VERSION ""

NS_ :

BS_:

BU_:IC_MMI AVM GW AC BCM DSM_D DSM_P FSCM CWC
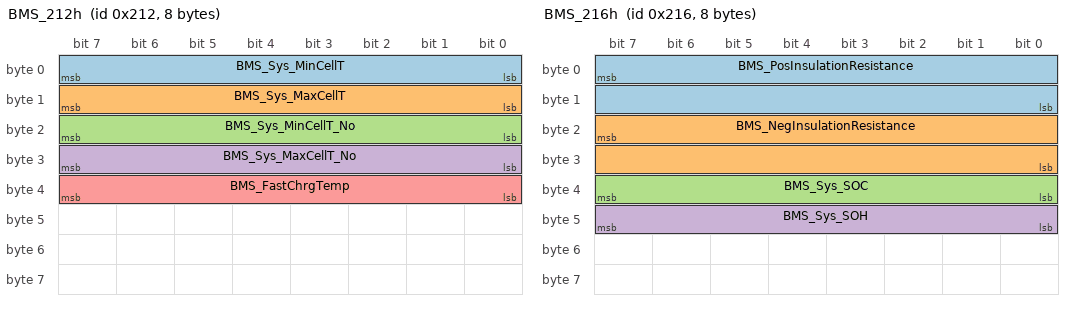
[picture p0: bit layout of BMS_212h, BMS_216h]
BO_ 530 BMS_212h: 8 GW
 SG_ BMS_Sys_MinCellT : 7|8@0+ (1,-50) [-50|204] "℃" IC_MMI
 SG_ BMS_Sys_MaxCellT : 15|8@0+ (1,-50) [-50|204] "℃" IC_MMI
 SG_ BMS_Sys_MinCellT_No : 23|8@0+ (1,0) [0|254] "℃" IC_MMI
 SG_ BMS_Sys_MaxCellT_No : 31|8@0+ (1,0) [0|254] "℃" IC_MMI
 SG_ BMS_FastChrgTemp : 39|8@0+ (1,-50) [-50|204] "℃" IC_MMI

BO_ 534 BMS_216h: 8 GW
 SG_ BMS_PosInsulationResistance : 7|16@0+ (1,0) [0|60000] "kΩ" IC_MMI
 SG_ BMS_NegInsulationResistance : 23|16@0+ (1,0) [0|60000] "kΩ" IC_MMI
 SG_ BMS_Sys_SOC : 39|8@0+ (1,0) [0|100] "%" IC_MMI
 SG_ BMS_Sys_SOH : 47|8@0+ (1,0) [0|100] "%" IC_MMI

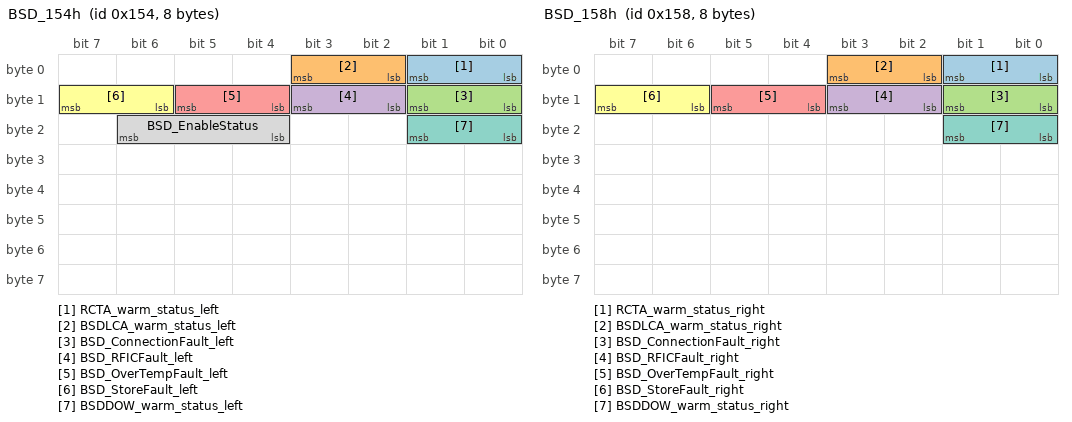
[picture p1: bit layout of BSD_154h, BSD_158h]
BO_ 340 BSD_154h: 8 GW
 SG_ RCTA_warm_status_left : 1|2@0+ (1,0) [0|3] "" IC_MMI
 SG_ BSDLCA_warm_status_left : 3|2@0+ (1,0) [0|3] "" IC_MMI
 SG_ BSD_ConnectionFault_left : 9|2@0+ (1,0) [0|3] "" IC_MMI
 SG_ BSD_RFICFault_left : 11|2@0+ (1,0) [0|3] "" IC_MMI
 SG_ BSD_OverTempFault_left : 13|2@0+ (1,0) [0|3] "" IC_MMI
 SG_ BSD_StoreFault_left : 15|2@0+ (1,0) [0|3] "" IC_MMI
 SG_ BSDDOW_warm_status_left : 17|2@0+ (1,0) [0|3] "" IC_MMI
 SG_ BSD_EnableStatus : 22|3@0+ (1,0) [0|7] "" IC_MMI

BO_ 344 BSD_158h: 8 GW
 SG_ RCTA_warm_status_right : 1|2@0+ (1,0) [0|3] "" IC_MMI
 SG_ BSDLCA_warm_status_right : 3|2@0+ (1,0) [0|3] "" IC_MMI
 SG_ BSD_ConnectionFault_right : 9|2@0+ (1,0) [0|3] "" IC_MMI
 SG_ BSD_RFICFault_right : 11|2@0+ (1,0) [0|3] "" IC_MMI
 SG_ BSD_OverTempFault_right : 13|2@0+ (1,0) [0|3] "" IC_MMI
 SG_ BSD_StoreFault_right : 15|2@0+ (1,0) [0|3] "" IC_MMI
 SG_ BSDDOW_warm_status_right : 17|2@0+ (1,0) [0|3] "" IC_MMI

BO_ 148 EHB_94h: 8 GW
 SG_ EHB_AEB_Available : 2|1@0+ (1,0) [0|1] "" IC_MMI
 SG_ EHB_ACC_Available : 3|1@0+ (1,0) [0|1] "" IC_MMI
 SG_ EHB_BrkPelPosActVD : 4|1@0+ (1,0) [0|1] "" IC_MMI
 SG_ EHB_FaultSt : 7|3@0+ (1,0) [0|7] "" IC_MMI
 SG_ EHB_BrkPelPosAct : 1|10@0+ (0.1,0) [0|100] "%" IC_MMI
 SG_ EHB_AEB_Jerk_Response : 19|1@0+ (1,0) [0|1] "" IC_MMI
 SG_ EHB_AEB_Request_Response : 20|1@0+ (1,0) [0|1] "" IC_MMI
 SG_ EHB_Prefill_Response : 21|1@0+ (1,0) [0|1] "" IC_MMI
 SG_ EHB_ACC_Request_Response : 22|1@0+ (1,0) [0|1] "" IC_MMI
 SG_ EHB_RegTorqReqVD : 23|1@0+ (1,0) [0|1] "" IC_MMI
 SG_ EHB_RegTorqReqWhl : 28|13@0+ (1,-6000) [-6000|0] "Nm" IC_MMI
 SG_ EHB_BrakePedalAppliedSt : 40|1@0+ (1,0) [0|1] "" IC_MMI
 SG_ EHB_94h_AliveCounter : 47|4@0+ (1,0) [0|15] "" IC_MMI
 SG_ EHB_BrakePedalApplied_Validity : 49|2@0+ (1,0) [0|3] "" IC_MMI
 SG_ EHBDiagActive : 52|1@0+ (1,0) [0|1] "" IC_MMI
 SG_ EHB_BrkLightAct : 53|1@0+ (1,0) [0|1] "" IC_MMI,BCM
 SG_ EHB_Hold : 54|1@0+ (1,0) [0|1] "" IC_MMI
 SG_ EHB_Hold_Available : 55|1@0+ (1,0) [0|1] "" IC_MMI
 SG_ EHB_94h_Checksum : 63|8@0+ (1,0) [0|255] "" IC_MMI

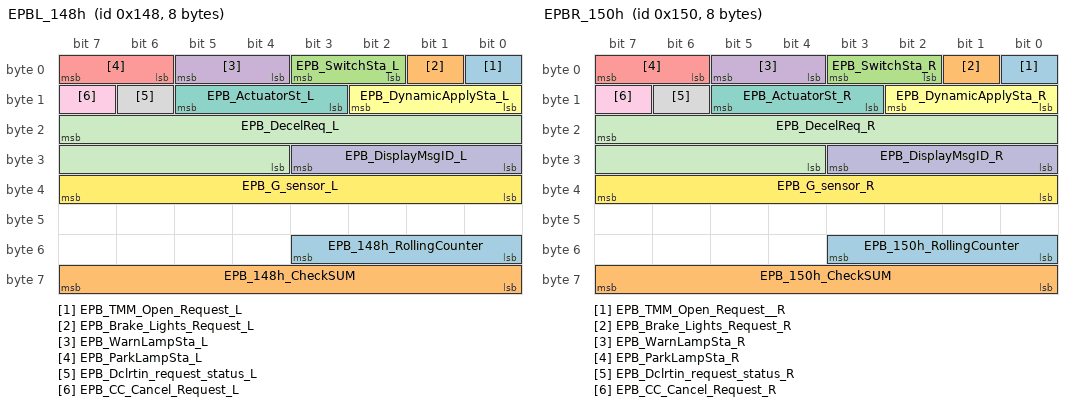
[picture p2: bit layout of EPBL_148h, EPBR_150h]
BO_ 328 EPBL_148h: 8 GW
 SG_ EPB_TMM_Open_Request_L : 0|1@0+ (1,0) [0|1] "" IC_MMI
 SG_ EPB_Brake_Lights_Request_L : 1|1@0+ (1,0) [0|1] "" IC_MMI,BCM
 SG_ EPB_SwitchSta_L : 3|2@0+ (1,0) [0|3] "" IC_MMI
 SG_ EPB_WarnLampSta_L : 5|2@0+ (1,0) [0|3] "" IC_MMI
 SG_ EPB_ParkLampSta_L : 7|2@0+ (1,0) [0|3] "" IC_MMI
 SG_ EPB_DynamicApplySta_L : 10|3@0+ (1,0) [0|7] "" IC_MMI
 SG_ EPB_ActuatorSt_L : 13|3@0+ (1,0) [0|7] "" IC_MMI,AVM
 SG_ EPB_Dclrtin_request_status_L : 14|1@0+ (1,0) [0|1] "" IC_MMI
 SG_ EPB_CC_Cancel_Request_L : 15|1@0+ (1,0) [0|1] "" IC_MMI
 SG_ EPB_DisplayMsgID_L : 27|4@0+ (1,0) [0|15] "" IC_MMI
 SG_ EPB_DecelReq_L : 23|12@0+ (0.01,-20.48) [-20.48|20.47] "" IC_MMI
 SG_ EPB_G_sensor_L : 39|8@0+ (1,0) [0|255] "" IC_MMI
 SG_ EPB_148h_RollingCounter : 51|4@0+ (1,0) [0|15] "" IC_MMI,AVM,BCM
 SG_ EPB_148h_CheckSUM : 63|8@0+ (1,0) [0|255] "" IC_MMI,AVM,BCM

BO_ 336 EPBR_150h: 8 GW
 SG_ EPB_TMM_Open_Request__R : 0|1@0+ (1,0) [0|1] "" IC_MMI
 SG_ EPB_Brake_Lights_Request_R : 1|1@0+ (1,0) [0|1] "" IC_MMI,BCM
 SG_ EPB_SwitchSta_R : 3|2@0+ (1,0) [0|3] "" IC_MMI
 SG_ EPB_WarnLampSta_R : 5|2@0+ (1,0) [0|3] "" IC_MMI
 SG_ EPB_ParkLampSta_R : 7|2@0+ (1,0) [0|3] "" IC_MMI
 SG_ EPB_DynamicApplySta_R : 10|3@0+ (1,0) [0|7] "" IC_MMI
 SG_ EPB_ActuatorSt_R : 13|3@0+ (1,0) [0|7] "" IC_MMI,AVM
 SG_ EPB_Dclrtin_request_status_R : 14|1@0+ (1,0) [0|1] "" IC_MMI
 SG_ EPB_CC_Cancel_Request_R : 15|1@0+ (1,0) [0|1] "" IC_MMI
 SG_ EPB_DisplayMsgID_R : 27|4@0+ (1,0) [0|15] "" IC_MMI
 SG_ EPB_DecelReq_R : 23|12@0+ (0.01,-20.48) [-20.48|20.47] "" IC_MMI
 SG_ EPB_G_sensor_R : 39|8@0+ (1,0) [0|255] "" IC_MMI
 SG_ EPB_150h_RollingCounter : 51|4@0+ (1,0) [0|15] "" IC_MMI,AVM,BCM
 SG_ EPB_150h_CheckSUM : 63|8@0+ (1,0) [0|255] "" IC_MMI,AVM,BCM

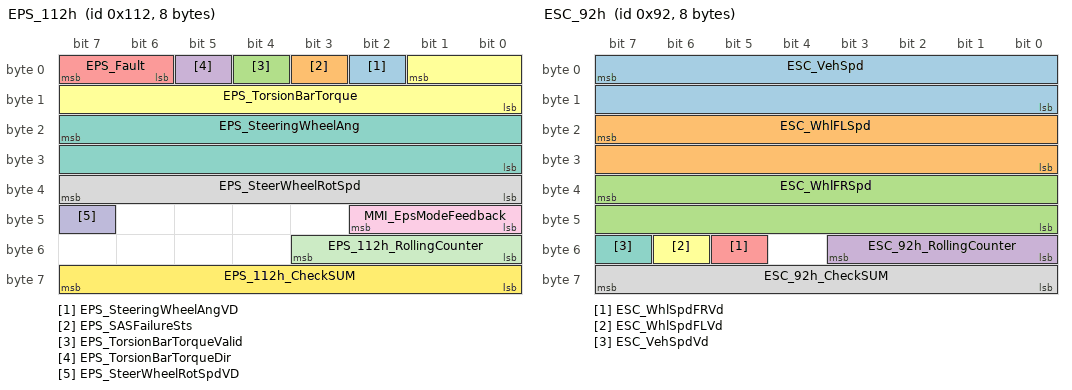
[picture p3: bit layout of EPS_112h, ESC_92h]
BO_ 274 EPS_112h: 8 GW
 SG_ EPS_SteeringWheelAngVD : 2|1@0+ (1,0) [0|1] "" IC_MMI,AVM
 SG_ EPS_SASFailureSts : 3|1@0+ (1,0) [0|1] "" IC_MMI,AVM
 SG_ EPS_TorsionBarTorqueValid : 4|1@0+ (1,0) [0|1] "" IC_MMI
 SG_ EPS_TorsionBarTorqueDir : 5|1@0+ (1,0) [0|1] "" IC_MMI
 SG_ EPS_Fault : 7|2@0+ (1,0) [0|3] "" IC_MMI
 SG_ EPS_TorsionBarTorque : 1|10@0+ (0.01,0) [0|8] "Nm" IC_MMI
 SG_ EPS_SteeringWheelAng : 23|16@0+ (0.1,-780) [-780|780] "degree" IC_MMI,AVM
 SG_ EPS_SteerWheelRotSpd : 39|8@0+ (4,0) [0|1016] "deg/s" IC_MMI
 SG_ MMI_EpsModeFeedback : 42|3@0+ (1,0) [0|7] "" IC_MMI
 SG_ EPS_SteerWheelRotSpdVD : 47|1@0+ (1,0) [0|1] "" IC_MMI
 SG_ EPS_112h_RollingCounter : 51|4@0+ (1,0) [0|15] "" IC_MMI
 SG_ EPS_112h_CheckSUM : 63|8@0+ (1,0) [0|255] "" IC_MMI

BO_ 144 ESC_90h: 8 GW
 SG_ ESC_TCSActive : 0|1@0+ (1,0) [0|1] "" IC_MMI
 SG_ ESC_HHC_Failure : 1|1@0+ (1,0) [0|1] "" IC_MMI
 SG_ ESC_HHCActive : 2|1@0+ (1,0) [0|1] "" IC_MMI
 SG_ ESC_EBDFailed : 3|1@0+ (1,0) [0|1] "" IC_MMI
 SG_ ESC_EBDActive : 4|1@0+ (1,0) [0|1] "" IC_MMI
 SG_ ESC_RBSState : 5|1@0+ (1,0) [0|1] "" IC_MMI
 SG_ ESC_ABSFailed : 6|1@0+ (1,0) [0|1] "" IC_MMI
 SG_ ESC_ABSActive : 7|1@0+ (1,0) [0|1] "" IC_MMI
 SG_ ESC_AVHactive : 8|1@0+ (1,0) [0|1] "" IC_MMI
 SG_ ESC_AutoholdStandby : 9|1@0+ (1,0) [0|1] "" IC_MMI
 SG_ ESC_AutoholdFailure : 10|1@0+ (1,0) [0|1] "" IC_MMI
 SG_ ESC_Sw : 11|1@0+ (1,0) [0|1] "" IC_MMI
 SG_ ESC_HBAActive : 12|1@0+ (1,0) [0|1] "" IC_MMI
 SG_ ESC_VDCFailure : 13|1@0+ (1,0) [0|1] "" IC_MMI
 SG_ ESC_VDCActive : 14|1@0+ (1,0) [0|1] "" IC_MMI
 SG_ ESC_TCSFailure : 15|1@0+ (1,0) [0|1] "" IC_MMI
 SG_ ESC_CDPAvailable : 20|1@0+ (1,0) [0|1] "" IC_MMI
 SG_ ESC_CDPActive : 21|1@0+ (1,0) [0|1] "" IC_MMI
 SG_ ESC_EPBRequest : 23|2@0+ (1,0) [0|3] "" IC_MMI
 SG_ ESC_BrkPrs : 19|12@0+ (0.1,0) [0|190] "bar" IC_MMI
 SG_ ESC_AVH_Warning1 : 40|1@0+ (1,0) [0|1] "" IC_MMI
 SG_ ESC_AVH_Warning2 : 41|1@0+ (1,0) [0|1] "" IC_MMI
 SG_ ESC_AVH_Warning3 : 42|1@0+ (1,0) [0|1] "" IC_MMI
 SG_ ESC_AVH_Warning4 : 43|1@0+ (1,0) [0|1] "" IC_MMI
 SG_ ESC_Brake_Light_Control : 38|1@0+ (1,0) [0|1] "" IC_MMI,BCM
 SG_ ESC_BrkPrsVd : 39|1@0+ (1,0) [0|1] "" IC_MMI
 SG_ ESC_90h_RollingCounter : 51|4@0+ (1,0) [0|15] "" IC_MMI,BCM
 SG_ ESC_90h_CheckSUM : 63|8@0+ (1,0) [0|255] "" IC_MMI,BCM

BO_ 146 ESC_92h: 8 GW
 SG_ ESC_VehSpd : 7|16@0+ (0.05625,0) [0|299.98] "km/h" IC_MMI,AVM,AC,BCM,DSM_D,DSM_P
 SG_ ESC_WhlFLSpd : 23|16@0+ (0.05625,0) [0|299.98125] "km/h" IC_MMI,AVM,BCM
 SG_ ESC_WhlFRSpd : 39|16@0+ (0.05625,0) [0|299.98125] "km/h" IC_MMI,AVM,BCM
 SG_ ESC_92h_RollingCounter : 51|4@0+ (1,0) [0|15] "" IC_MMI,AVM,AC,BCM,DSM_D,DSM_P
 SG_ ESC_WhlSpdFRVd : 53|1@0+ (1,0) [0|1] "" IC_MMI,AVM,BCM
 SG_ ESC_WhlSpdFLVd : 54|1@0+ (1,0) [0|1] "" IC_MMI,AVM,BCM
 SG_ ESC_VehSpdVd : 55|1@0+ (1,0) [0|1] "" IC_MMI,AVM,AC,BCM,DSM_D,DSM_P
 SG_ ESC_92h_CheckSUM : 63|8@0+ (1,0) [0|255] "" IC_MMI,AVM,AC,BCM,DSM_D,DSM_P

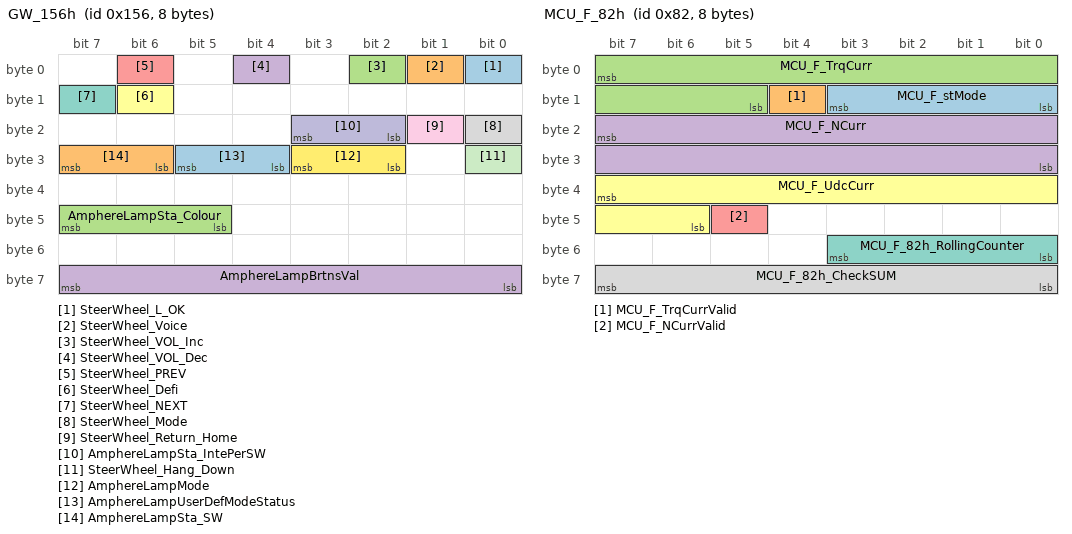
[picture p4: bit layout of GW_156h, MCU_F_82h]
BO_ 342 GW_156h: 8 GW
 SG_ SteerWheel_L_OK : 0|1@0+ (1,0) [0|1] "" IC_MMI
 SG_ SteerWheel_Voice : 1|1@0+ (1,0) [0|1] "" IC_MMI
 SG_ SteerWheel_VOL_Inc : 2|1@0+ (1,0) [0|1] "" IC_MMI
 SG_ SteerWheel_VOL_Dec : 4|1@0+ (1,0) [0|1] "" IC_MMI
 SG_ SteerWheel_PREV : 6|1@0+ (1,0) [0|1] "" IC_MMI
 SG_ SteerWheel_Defi : 14|1@0+ (1,0) [0|1] "" IC_MMI
 SG_ SteerWheel_NEXT : 15|1@0+ (1,0) [0|1] "" IC_MMI
 SG_ SteerWheel_Mode : 16|1@0+ (1,0) [0|1] "" IC_MMI
 SG_ SteerWheel_Return_Home : 17|1@0+ (1,0) [0|1] "" IC_MMI
 SG_ AmphereLampSta_IntePerSW : 19|2@0+ (1,0) [0|3] "" IC_MMI
 SG_ SteerWheel_Hang_Down : 24|1@0+ (1,0) [0|1] "" IC_MMI
 SG_ AmphereLampMode : 27|2@0+ (1,0) [0|3] "" IC_MMI
 SG_ AmphereLampUserDefModeStatus : 29|2@0+ (1,0) [0|3] "" IC_MMI
 SG_ AmphereLampSta_SW : 31|2@0+ (1,0) [0|3] "" IC_MMI
 SG_ AmphereLampSta_Colour : 47|3@0+ (1,0) [0|7] "" IC_MMI
 SG_ AmphereLampBrtnsVal : 63|8@0+ (1,0) [0|100] "%" IC_MMI

BO_ 594 MCU_F_252h: 8 GW
 SG_ MCU_F_FailureNum : 7|8@0+ (1,0) [0|255] "" IC_MMI
 SG_ MCU_F_ResolverFault : 8|1@0+ (1,0) [0|1] "" IC_MMI
 SG_ MCU_F_Err_IGBT : 9|1@0+ (1,0) [0|1] "" IC_MMI
 SG_ MCU_F_CurrentOverload : 11|2@0+ (1,0) [0|3] "" IC_MMI
 SG_ MCU_F_Controllertemp_Status : 13|2@0+ (1,0) [0|3] "" IC_MMI
 SG_ MCU_F_stDischg : 15|2@0+ (1,0) [0|3] "" IC_MMI
 SG_ MCU_F_SpeedOtLoopFalult : 18|1@0+ (1,0) [0|1] "" IC_MMI
 SG_ MCU_F_MdTepErr : 19|1@0+ (1,0) [0|1] "" IC_MMI
 SG_ MCU_F_ControllerOverVolt_Status : 21|2@0+ (1,0) [0|3] "" IC_MMI
 SG_ MCU_F_MotorTemp_Fault : 23|2@0+ (1,0) [0|3] "" IC_MMI
 SG_ MCU_F_MotorOverSpd : 25|1@0+ (1,0) [0|1] "" IC_MMI
 SG_ MCU_F_VCUCommErr : 26|1@0+ (1,0) [0|1] "" IC_MMI
 SG_ MCU_F_ControllerLowUnderVolt_Status : 27|1@0+ (1,0) [0|1] "" IC_MMI
 SG_ MCU_F_ControllerUnderVolt_Status : 29|2@0+ (1,0) [0|3] "" IC_MMI
 SG_ MCU_F_ControllerFault : 17|3@0+ (1,0) [0|7] "" IC_MMI
 SG_ FMCU_HV_Interlock_Falult : 35|2@0+ (1,0) [0|3] "" IC_MMI
 SG_ FMCU_Uncap_Falult : 37|2@0+ (1,0) [0|3] "" IC_MMI
 SG_ MCU_F_MotTepErr : 39|1@0+ (1,0) [0|1] "" IC_MMI

BO_ 130 MCU_F_82h: 8 GW
 SG_ MCU_F_stMode : 11|4@0+ (1,0) [0|15] "" IC_MMI
 SG_ MCU_F_TrqCurrValid : 12|1@0+ (1,0) [0|1] "" IC_MMI
 SG_ MCU_F_TrqCurr : 7|11@0+ (1,-1024) [-1024|1023] "Nm" IC_MMI
 SG_ MCU_F_NCurr : 23|16@0+ (1,-32768) [-32768|32767] "1/min" IC_MMI,AVM,BCM
 SG_ MCU_F_NCurrValid : 45|1@0+ (1,0) [0|1] "" IC_MMI,AVM,BCM
 SG_ MCU_F_UdcCurr : 39|10@0+ (1,0) [0|1021] "V" IC_MMI
 SG_ MCU_F_82h_RollingCounter : 51|4@0+ (1,0) [0|15] "" IC_MMI,AVM,BCM
 SG_ MCU_F_82h_CheckSUM : 63|8@0+ (1,0) [0|255] "" IC_MMI,AVM,BCM

BO_ 132 MCU_F_84h: 8 GW
 SG_ MCU_F_ControlerTemp : 7|8@0+ (1,-50) [-50|205] "℃" IC_MMI
 SG_ MCU_F_TempCurr : 31|8@0+ (1,-50) [-50|205] "℃" IC_MMI

BO_ 580 MCU_R_244h: 8 GW
 SG_ MCU_R_ControlerTemp : 7|8@0+ (1,-50) [-50|205] "℃" IC_MMI
 SG_ MCU_R_TempCurr : 31|8@0+ (1,-50) [-50|205] "℃" IC_MMI

BO_ 608 MCU_R_260h: 8 GW
 SG_ MCU_R_FailureNum : 7|8@0+ (1,0) [0|255] "" IC_MMI
 SG_ MCU_R_ResolverFault : 8|1@0+ (1,0) [0|1] "" IC_MMI
 SG_ MCU_R_Err_IGBT : 9|1@0+ (1,0) [0|1] "" IC_MMI
 SG_ MCU_R_CurrentOverload : 11|2@0+ (1,0) [0|3] "" IC_MMI
 SG_ MCU_R_Controllertemp_Status : 13|2@0+ (1,0) [0|3] "" IC_MMI
 SG_ MCU_R_stDischg : 15|2@0+ (1,0) [0|3] "" IC_MMI
 SG_ MCU_R_SpeedOtLoopFalult : 18|1@0+ (1,0) [0|1] "" IC_MMI
 SG_ MCU_R_MdTepErr : 19|1@0+ (1,0) [0|1] "" IC_MMI
 SG_ MCU_R_ControllerOverVolt_Status : 21|2@0+ (1,0) [0|3] "" IC_MMI
 SG_ MCU_R_MotorTemp_Fault : 23|2@0+ (1,0) [0|3] "" IC_MMI
 SG_ MCU_R_MotorOverSpd : 25|1@0+ (1,0) [0|1] "" IC_MMI
 SG_ MCU_R_VCUCommErr : 26|1@0+ (1,0) [0|1] "" IC_MMI
 SG_ MCU_R_ControllerLowUnderVolt_Status : 27|1@0+ (1,0) [0|1] "" IC_MMI
 SG_ MCU_R_ControllerUnderVolt_Status : 29|2@0+ (1,0) [0|3] "" IC_MMI
 SG_ MCU_R_ControllerFault : 17|3@0+ (1,0) [0|7] "" IC_MMI
 SG_ RMCU_HV_Interlock_Falult : 35|2@0+ (1,0) [0|3] "" IC_MMI
 SG_ RMCU_Uncap_Falult : 37|2@0+ (1,0) [0|3] "" IC_MMI
 SG_ MCU_R_MotTepErr : 39|1@0+ (1,0) [0|1] "" IC_MMI

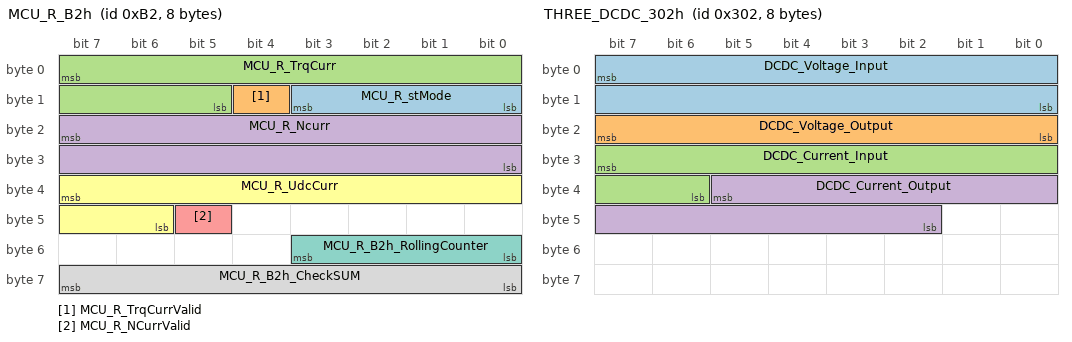
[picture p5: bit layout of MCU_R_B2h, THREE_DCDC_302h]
BO_ 178 MCU_R_B2h: 8 GW
 SG_ MCU_R_stMode : 11|4@0+ (1,0) [0|15] "" IC_MMI
 SG_ MCU_R_TrqCurrValid : 12|1@0+ (1,0) [0|1] "" IC_MMI
 SG_ MCU_R_TrqCurr : 7|11@0+ (1,-1024) [-1024|1023] "Nm" IC_MMI
 SG_ MCU_R_Ncurr : 23|16@0+ (1,-32768) [-32768|32767] "1/min" IC_MMI,AVM,BCM
 SG_ MCU_R_NCurrValid : 45|1@0+ (1,0) [0|1] "" IC_MMI,AVM,BCM
 SG_ MCU_R_UdcCurr : 39|10@0+ (1,0) [0|1021] "V" IC_MMI
 SG_ MCU_R_B2h_RollingCounter : 51|4@0+ (1,0) [0|15] "" IC_MMI,AVM,BCM
 SG_ MCU_R_B2h_CheckSUM : 63|8@0+ (1,0) [0|15] "" IC_MMI,AVM,BCM

BO_ 772 THREE_OBC_304h: 8 GW
 SG_ OBC_out_Cur_over_prot : 0|1@0+ (1,0) [0|1] "" IC_MMI
 SG_ OBC_out_vol_Less_prot : 1|1@0+ (1,0) [0|1] "" IC_MMI
 SG_ OBC_out_vol_over_prot : 2|1@0+ (1,0) [0|1] "" IC_MMI
 SG_ OBC_In_Cur_over_prot : 3|1@0+ (1,0) [0|1] "" IC_MMI
 SG_ OBC_ChargerInputVoltageLessFault : 4|1@0+ (1,0) [0|1] "" IC_MMI
 SG_ OBC_ChargerInputVoltageOverFault : 5|1@0+ (1,0) [0|1] "" IC_MMI
 SG_ ChargeInterfaceOverTemp : 6|1@0+ (1,0) [0|1] "" IC_MMI
 SG_ ChargeInterfacetemperature : 15|8@0+ (1,0) [0|255] "℃" IC_MMI
 SG_ OBC_ControllerTemp : 23|8@0+ (1,0) [0|255] "℃" IC_MMI
 SG_ OBC_ChargerOTP : 25|2@0+ (1,0) [0|3] "" IC_MMI
 SG_ OBC_ChargerCoolingRequest : 26|1@0+ (1,0) [0|1] "" IC_MMI
 SG_ OBC_ChargerHardwareFault : 27|1@0+ (1,0) [0|1] "" IC_MMI
 SG_ OBC_Charger_CAN_Fault : 28|1@0+ (1,0) [0|1] "" IC_MMI
 SG_ OBC_Charger_Fail_State : 29|1@0+ (1,0) [0|1] "" IC_MMI
 SG_ OBC_Charger_NoBatt : 31|2@0+ (1,0) [0|3] "" IC_MMI
 SG_ OBC_CP_DutyCycleValue : 39|8@0+ (1,0) [0|100] "%" IC_MMI
 SG_ OBC_CP_Rsv : 40|1@0+ (1,0) [0|1] "" IC_MMI
 SG_ OBC_CC_Resistance : 43|3@0+ (1,0) [0|7] "" IC_MMI
 SG_ OBC_ChargerStatus : 46|3@0+ (1,0) [0|7] "" IC_MMI
 SG_ KL30_UnderVolt : 49|2@0+ (1,0) [0|3] "" IC_MMI
 SG_ ElectronicLockSts : 50|1@0+ (1,0) [0|1] "" IC_MMI
 SG_ ElectronicLockFault : 52|2@0+ (1,0) [0|3] "" IC_MMI
 SG_ OBC_Charger_Instructions : 53|1@0+ (1,0) [0|1] "" IC_MMI
 SG_ OBC_Charger_Request : 54|1@0+ (1,0) [0|1] "" IC_MMI

BO_ 770 THREE_DCDC_302h: 8 GW
 SG_ DCDC_Voltage_Input : 7|16@0+ (0.1,0) [0|500] "V" IC_MMI
 SG_ DCDC_Voltage_Output : 23|8@0+ (0.1,0) [0|20] "A" IC_MMI
 SG_ DCDC_Current_Input : 31|10@0+ (0.1,0) [0|60] "V" IC_MMI
 SG_ DCDC_Current_Output : 37|12@0+ (0.1,0) [0|400] "A" IC_MMI

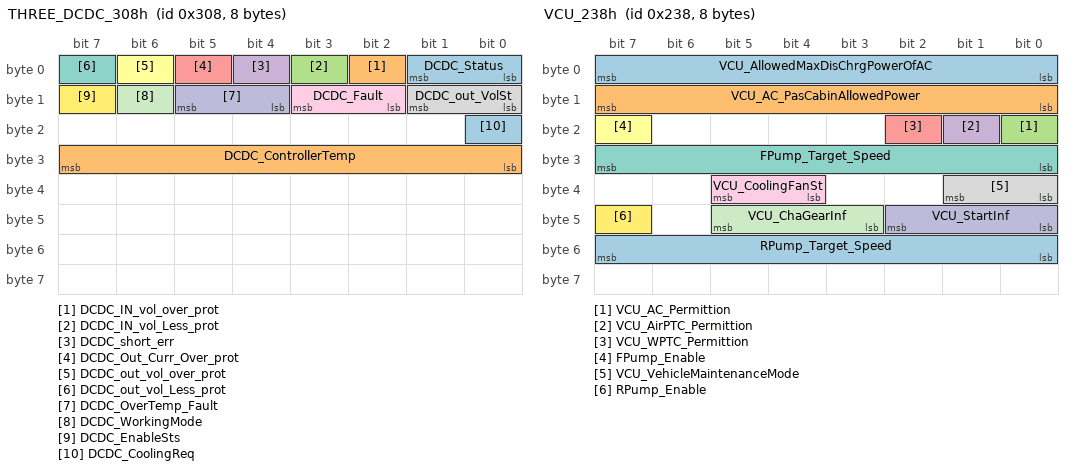
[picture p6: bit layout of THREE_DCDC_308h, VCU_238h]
BO_ 776 THREE_DCDC_308h: 8 GW
 SG_ DCDC_Status : 1|2@0+ (1,0) [0|3] "" IC_MMI
 SG_ DCDC_IN_vol_over_prot : 2|1@0+ (1,0) [0|1] "" IC_MMI
 SG_ DCDC_IN_vol_Less_prot : 3|1@0+ (1,0) [0|1] "" IC_MMI
 SG_ DCDC_short_err : 4|1@0+ (1,0) [0|1] "" IC_MMI
 SG_ DCDC_Out_Curr_Over_prot : 5|1@0+ (1,0) [0|1] "" IC_MMI
 SG_ DCDC_out_vol_over_prot : 6|1@0+ (1,0) [0|1] "" IC_MMI
 SG_ DCDC_out_vol_Less_prot : 7|1@0+ (1,0) [0|1] "" IC_MMI
 SG_ DCDC_out_VolSt : 9|2@0+ (1,0) [0|3] "" IC_MMI
 SG_ DCDC_Fault : 11|2@0+ (1,0) [0|3] "" IC_MMI
 SG_ DCDC_OverTemp_Fault : 13|2@0+ (1,0) [0|3] "" IC_MMI
 SG_ DCDC_WorkingMode : 14|1@0+ (1,0) [0|1] "" IC_MMI
 SG_ DCDC_EnableSts : 15|1@0+ (1,0) [0|1] "" IC_MMI
 SG_ DCDC_CoolingReq : 16|1@0+ (1,0) [0|1] "" IC_MMI
 SG_ DCDC_ControllerTemp : 31|8@0+ (1,0) [0|255] "℃" IC_MMI

BO_ 372 VCU_174h: 8 GW
 SG_ VCU_Err_BrakeSwitch : 0|1@0+ (1,0) [0|1] "" IC_MMI
 SG_ VCU_Err_BrakePedal : 1|1@0+ (1,0) [0|1] "" IC_MMI
 SG_ VCU_Err_AccPedal : 2|1@0+ (1,0) [0|1] "" IC_MMI
 SG_ VCU_GearPosition : 7|4@0+ (1,0) [0|15] "" IC_MMI,AVM,BCM,FSCM
 SG_ VCU_PrechrgAnodeRelay_Status : 9|2@0+ (1,0) [0|3] "" IC_MMI
 SG_ VCU_DischrgAnodeRelay_Control : 11|1@0+ (1,0) [0|1] "" IC_MMI
 SG_ VCU_DischrgAnodeRelay_Status : 14|2@0+ (1,0) [0|3] "" IC_MMI
 SG_ VCU_DischrgCathodeRelay_Control : 17|1@0+ (1,0) [0|1] "" IC_MMI
 SG_ VCU_DischrgCathodeRelay_status : 19|2@0+ (1,0) [0|3] "" IC_MMI
 SG_ VCU_PrechrgAnodeRelay_Control : 21|1@0+ (1,0) [0|1] "" IC_MMI
 SG_ VCU_PTSystem_Satus : 23|2@0+ (1,0) [0|3] "" IC_MMI,AVM
 SG_ VCU_VehSysStatus : 28|5@0+ (1,0) [0|31] "" IC_MMI,AVM,AC,BCM
 SG_ VCU_ChrgRelay_Control : 29|1@0+ (1,0) [0|1] "" IC_MMI
 SG_ VCU_Cruise_MainSwitch : 32|1@0+ (1,0) [0|1] "" IC_MMI
 SG_ VCU_OperationMode : 34|2@0+ (1,0) [0|3] "" IC_MMI,AC
 SG_ VCU_DrivingMode : 36|2@0+ (1,0) [0|1] "" IC_MMI
 SG_ VCU_SpeedMode : 37|1@0+ (1,0) [0|1] "" IC_MMI
 SG_ VCU_TortoiseIndicator : 44|1@0+ (1,0) [0|1] "" IC_MMI
 SG_ VCU_Comd_OpenHazardWarningLamp : 45|1@0+ (1,0) [0|1] "" IC_MMI,BCM
 SG_ VCU_ActiveDischargeOrder : 46|1@0+ (1,0) [0|1] "" IC_MMI
 SG_ VCU_Cruise_Enable : 47|1@0+ (1,0) [0|1] "" IC_MMI
 SG_ VCU_174h_RollingCounter : 51|4@0+ (1,0) [0|15] "" IC_MMI,AVM,AC,BCM,FSCM
 SG_ VCU_UnlockSts : 54|2@0+ (1,0) [0|3] "" IC_MMI,BCM
 SG_ VCU_StartAllow : 55|1@0+ (1,0) [0|1] "" IC_MMI,BCM
 SG_ VCU_174h_CheckSUM : 63|8@0+ (1,0) [0|255] "" IC_MMI,AVM,AC,BCM,FSCM

BO_ 568 VCU_238h: 8 GW
 SG_ VCU_AllowedMaxDisChrgPowerOfAC : 7|8@0+ (0.1,0) [0|20] "kw" IC_MMI,AC
 SG_ VCU_AC_PasCabinAllowedPower : 15|8@0+ (0.1,0) [0|20] "kw" IC_MMI,AC
 SG_ VCU_AC_Permittion : 16|1@0+ (1,0) [0|1] "" IC_MMI,AC
 SG_ VCU_AirPTC_Permittion : 17|1@0+ (1,0) [0|1] "" IC_MMI,AC
 SG_ VCU_WPTC_Permittion : 18|1@0+ (1,0) [0|1] "" IC_MMI,AC
 SG_ FPump_Enable : 23|1@0+ (1,0) [0|1] "" IC_MMI
 SG_ FPump_Target_Speed : 31|8@0+ (1,0) [0|100] "%" IC_MMI
 SG_ VCU_VehicleMaintenanceMode : 33|2@0+ (1,0) [0|3] "" IC_MMI,AC
 SG_ VCU_CoolingFanSt : 37|2@0+ (1,0) [0|3] "" IC_MMI,AC
 SG_ VCU_StartInf : 42|3@0+ (1,0) [0|7] "" IC_MMI
 SG_ VCU_ChaGearInf : 45|3@0+ (1,0) [0|7] "" IC_MMI
 SG_ RPump_Enable : 47|1@0+ (1,0) [0|1] "" IC_MMI
 SG_ RPump_Target_Speed : 55|8@0+ (1,0) [0|100] "%" IC_MMI

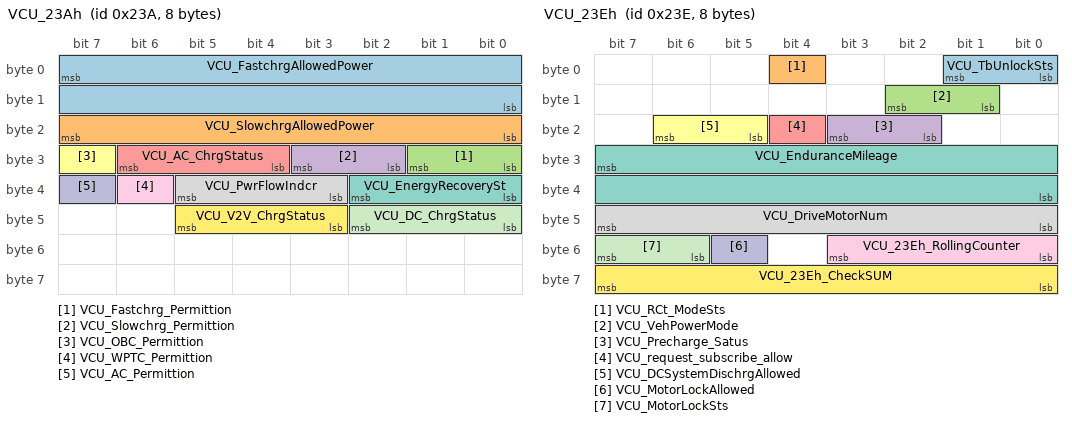
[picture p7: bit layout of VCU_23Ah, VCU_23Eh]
BO_ 570 VCU_23Ah: 8 GW
 SG_ VCU_FastchrgAllowedPower : 7|16@0+ (0.1,0) [0|100] "kw" IC_MMI
 SG_ VCU_SlowchrgAllowedPower : 23|8@0+ (0.1,0) [0|20] "kw" IC_MMI
 SG_ VCU_Fastchrg_Permittion : 25|2@0+ (1,0) [0|3] "" IC_MMI
 SG_ VCU_Slowchrg_Permittion : 27|2@0+ (1,0) [0|3] "" IC_MMI
 SG_ VCU_AC_ChrgStatus : 30|3@0+ (1,0) [0|7] "" IC_MMI
 SG_ VCU_OBC_Permittion : 31|1@0+ (1,0) [0|1] "" IC_MMI
 SG_ VCU_EnergyRecoverySt : 34|3@0+ (1,0) [0|7] "" IC_MMI
 SG_ VCU_PwrFlowIndcr : 37|3@0+ (1,0) [0|7] "" IC_MMI
 SG_ VCU_WPTC_Permittion : 38|1@0+ (1,0) [0|1] "" IC_MMI
 SG_ VCU_AC_Permittion : 39|1@0+ (1,0) [0|1] "" IC_MMI
 SG_ VCU_DC_ChrgStatus : 42|3@0+ (1,0) [0|7] "" IC_MMI
 SG_ VCU_V2V_ChrgStatus : 45|3@0+ (1,0) [0|7] "" IC_MMI

BO_ 574 VCU_23Eh: 8 GW
 SG_ VCU_TbUnlockSts : 1|2@0+ (1,0) [0|3] "" IC_MMI
 SG_ VCU_RCt_ModeSts : 4|1@0+ (1,0) [0|1] "" IC_MMI
 SG_ VCU_VehPowerMode : 10|2@0+ (1,0) [0|3] "" IC_MMI
 SG_ VCU_Precharge_Satus : 19|2@0+ (1,0) [0|3] "" IC_MMI
 SG_ VCU_request_subscribe_allow : 20|1@0+ (1,0) [0|1] "" IC_MMI
 SG_ VCU_DCSystemDischrgAllowed : 22|2@0+ (1,0) [0|3] "" IC_MMI
 SG_ VCU_EnduranceMileage : 31|16@0+ (0.1,0) [0|800] "km" IC_MMI
 SG_ VCU_DriveMotorNum : 47|8@0+ (1,0) [1|254] "" IC_MMI
 SG_ VCU_23Eh_RollingCounter : 51|4@0+ (1,0) [0|15] "" IC_MMI
 SG_ VCU_MotorLockAllowed : 53|1@0+ (1,0) [0|1] "" IC_MMI
 SG_ VCU_MotorLockSts : 55|2@0+ (1,0) [0|3] "" IC_MMI
 SG_ VCU_23Eh_CheckSUM : 63|8@0+ (1,0) [0|255] "" IC_MMI

BO_ 112 VCU_70h: 8 GW
 SG_ VCU_APA_FaildType : 2|3@0+ (1,0) [0|7] "" IC_MMI
 SG_ VCU_BrkPedPos_Validity : 3|1@0+ (1,0) [0|1] "" IC_MMI
 SG_ VCU_BrkSw_Sta : 4|1@0+ (1,0) [0|1] "" IC_MMI,AVM,BCM
 SG_ VCU_EHB_VLC_Response : 5|1@0+ (1,0) [0|1] "" IC_MMI
 SG_ VCU_BrkSw_V : 6|1@0+ (1,0) [0|1] "" IC_MMI,AVM,BCM
 SG_ VCU_Acc_Validity : 7|1@0+ (1,0) [0|1] "" IC_MMI,AVM
 SG_ VCU_BrkPed_Pos : 15|8@0+ (0.5,0) [0|100] "%" IC_MMI
 SG_ VCU_Acc_pedal_position : 23|8@0+ (0.5,0) [0|100] "%" IC_MMI,AVM
 SG_ VCU_APA_ActiveEnableSts : 30|1@0+ (1,0) [0|1] "bit" IC_MMI
 SG_ VCU_MotorTrqRegAllowed : 31|1@0+ (1,0) [0|1] "" IC_MMI
 SG_ VCU_MotorTrqRegLimit : 28|13@0+ (1,-6000) [-6000|0] "NM" IC_MMI
 SG_ VCU_Accel_Padel_Pos_Calc : 47|8@0+ (0.5,0) [0|100] "%" IC_MMI
 SG_ VCU_70h_RollingCounter : 51|4@0+ (1,0) [0|15] "" IC_MMI,AVM,BCM
 SG_ VCU_Request_Response : 52|1@0+ (1,0) [0|1] "" IC_MMI
 SG_ VCU_Kickdown_AEB : 53|1@0+ (1,0) [0|1] "" IC_MMI
 SG_ VCU_Accel_Padel_Override : 54|1@0+ (1,0) [0|1] "" IC_MMI
 SG_ VCU_Available : 55|1@0+ (1,0) [0|1] "" IC_MMI
 SG_ VCU_70h_CheckSUM : 63|8@0+ (1,0) [0|255] "" IC_MMI,AVM,BCM

BO_ 913 VSP_391h: 8 GW
 SG_ VSP_State : 2|2@0+ (1,0) [0|3] "" IC_MMI
 SG_ VSP_VoiceSourceSelectFeedback : 4|2@0+ (1,0) [0|3] "" IC_MMI

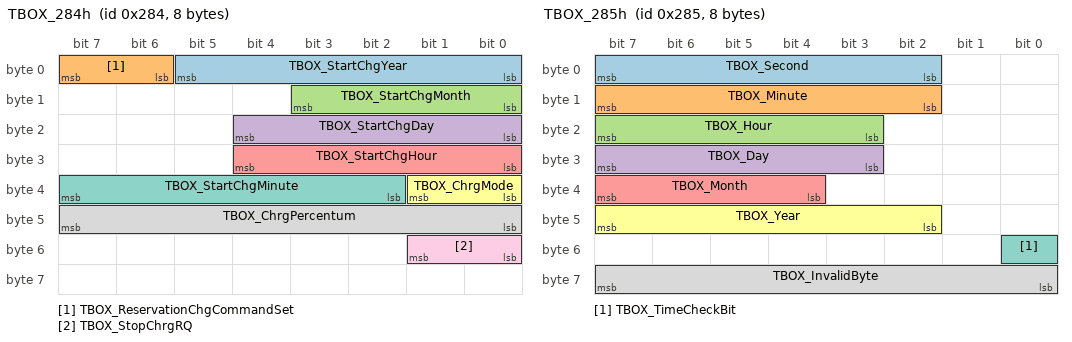
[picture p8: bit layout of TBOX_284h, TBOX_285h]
BO_ 644 TBOX_284h: 8 GW
 SG_ TBOX_StartChgYear : 5|6@0+ (1,2010) [2010|2072] "" IC_MMI
 SG_ TBOX_ReservationChgCommandSet : 7|2@0+ (1,0) [0|3] "" IC_MMI
 SG_ TBOX_StartChgMonth : 11|4@0+ (1,0) [1|12] "" IC_MMI
 SG_ TBOX_StartChgDay : 20|5@0+ (1,0) [1|31] "" IC_MMI
 SG_ TBOX_StartChgHour : 28|5@0+ (1,0) [0|23] "" IC_MMI
 SG_ TBOX_ChrgMode : 33|2@0+ (1,0) [0|3] "" IC_MMI
 SG_ TBOX_StartChgMinute : 39|6@0+ (1,0) [0|59] "" IC_MMI
 SG_ TBOX_ChrgPercentum : 47|8@0+ (1,0) [0|100] "%" IC_MMI
 SG_ TBOX_StopChrgRQ : 49|2@0+ (1,0) [0|3] "" IC_MMI

BO_ 645 TBOX_285h: 8 GW
 SG_ TBOX_Second : 7|6@0+ (1,0) [0|59] "s" IC_MMI,AVM,AC
 SG_ TBOX_Minute : 15|6@0+ (1,0) [0|59] "m" IC_MMI,AVM,AC
 SG_ TBOX_Hour : 23|5@0+ (1,0) [0|23] "h" IC_MMI,AVM,AC
 SG_ TBOX_Day : 31|5@0+ (1,0) [1|31] "d" IC_MMI,AVM,AC
 SG_ TBOX_Month : 39|4@0+ (1,0) [1|12] "m" IC_MMI,AVM,AC
 SG_ TBOX_Year : 47|6@0+ (1,2010) [2010|2072] "y" IC_MMI,AVM,AC
 SG_ TBOX_TimeCheckBit : 48|1@0+ (1,0) [0|1] "" IC_MMI,AVM,AC
 SG_ TBOX_InvalidByte : 63|8@0+ (1,0) [0|255] "" IC_MMI,AVM,AC

BO_ 662 TBOX_296h: 8 GW
 SG_ TBOX_VehiclePosition_longitude : 7|32@0+ (0.0000001,-180) [-180|180] "" IC_MMI,AC
 SG_ TBOX_VehiclePosition_latitude : 39|32@0+ (0.0000001,-90) [-90|90] "" IC_MMI,AC

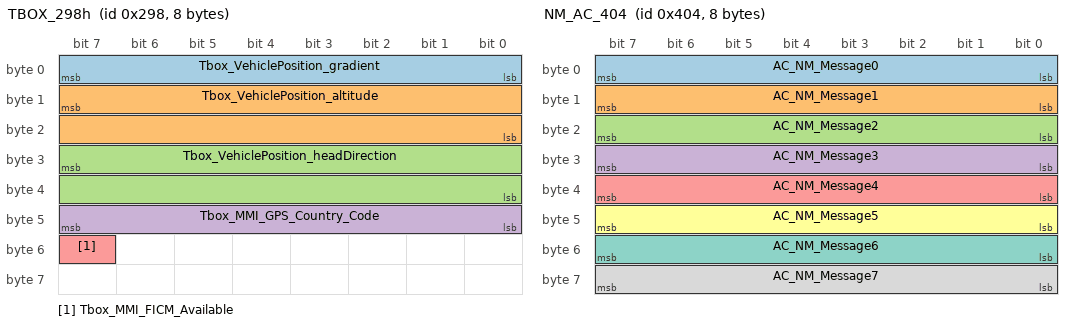
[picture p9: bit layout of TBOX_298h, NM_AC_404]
BO_ 664 TBOX_298h: 8 GW
 SG_ Tbox_VehiclePosition_gradient : 7|8@0+ (1,-90) [-90|90] "" IC_MMI,AC
 SG_ Tbox_VehiclePosition_altitude : 15|16@0+ (0.1,-53.4) [-53.4|6500] "" IC_MMI,AC
 SG_ Tbox_VehiclePosition_headDirection : 31|16@0+ (1,0) [0|359] "" IC_MMI,AC
 SG_ Tbox_MMI_GPS_Country_Code : 47|8@0+ (1,0) [0|255] "" IC_MMI
 SG_ Tbox_MMI_FICM_Available : 55|1@0+ (1,0) [0|1] "" IC_MMI

BO_ 1028 NM_AC_404: 8 AC
 SG_ AC_NM_Message0 : 7|8@0+ (1,0) [0|255] "" IC_MMI,GW,BCM
 SG_ AC_NM_Message1 : 15|8@0+ (1,0) [0|255] "" IC_MMI,GW,BCM
 SG_ AC_NM_Message2 : 23|8@0+ (1,0) [0|255] "" IC_MMI,GW,BCM
 SG_ AC_NM_Message3 : 31|8@0+ (1,0) [0|255] "" IC_MMI,GW,BCM
 SG_ AC_NM_Message4 : 39|8@0+ (1,0) [0|255] "" IC_MMI,GW,BCM
 SG_ AC_NM_Message5 : 47|8@0+ (1,0) [0|255] "" IC_MMI,GW,BCM
 SG_ AC_NM_Message6 : 55|8@0+ (1,0) [0|255] "" IC_MMI,GW,BCM
 SG_ AC_NM_Message7 : 63|8@0+ (1,0) [0|255] "" IC_MMI,GW,BCM

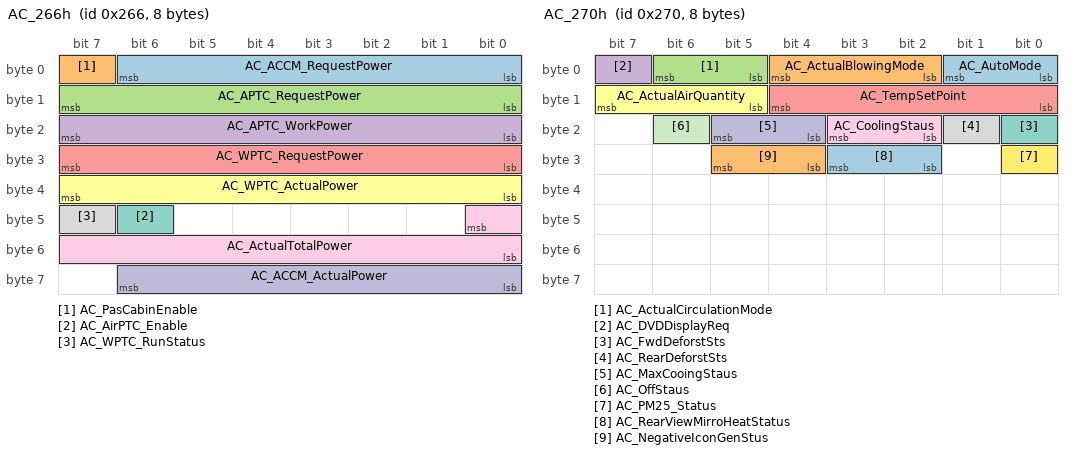
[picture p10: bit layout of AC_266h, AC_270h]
BO_ 614 AC_266h: 8 AC
 SG_ AC_ACCM_RequestPower : 6|7@0+ (40,0) [0|5000] "W" IC_MMI,GW
 SG_ AC_PasCabinEnable : 7|1@0+ (1,0) [0|1] "" IC_MMI,GW
 SG_ AC_APTC_RequestPower : 15|8@0+ (40,0) [0|6000] "W" IC_MMI,GW
 SG_ AC_APTC_WorkPower : 23|8@0+ (40,0) [0|6000] "W" IC_MMI,GW
 SG_ AC_WPTC_RequestPower : 31|8@0+ (40,0) [0|7000] "W" IC_MMI,GW
 SG_ AC_WPTC_ActualPower : 39|8@0+ (40,0) [0|7000] "W" IC_MMI,GW
 SG_ AC_AirPTC_Enable : 46|1@0+ (1,0) [0|1] "" IC_MMI,GW
 SG_ AC_WPTC_RunStatus : 47|1@0+ (1,0) [0|1] "" IC_MMI,GW
 SG_ AC_ActualTotalPower : 40|9@0+ (40,0) [0|20000] "W" IC_MMI,GW
 SG_ AC_ACCM_ActualPower : 62|7@0+ (40,0) [0|5000] "W" IC_MMI,GW

BO_ 624 AC_270h: 8 AC
 SG_ AC_AutoMode : 1|2@0+ (1,0) [0|3] "" IC_MMI,GW
 SG_ AC_ActualBlowingMode : 4|3@0+ (1,0) [0|7] "" IC_MMI,GW
 SG_ AC_ActualCirculationMode : 6|2@0+ (1,0) [0|3] "" IC_MMI,GW
 SG_ AC_DVDDisplayReq : 7|1@0+ (1,0) [0|1] "" IC_MMI,GW
 SG_ AC_TempSetPoint : 12|5@0+ (0.5,18) [18|32] "℃" IC_MMI,GW
 SG_ AC_ActualAirQuantity : 15|3@0+ (1,0) [0|7] "" IC_MMI,GW
 SG_ AC_FwdDeforstSts : 16|1@0+ (1,0) [0|1] "" IC_MMI,GW
 SG_ AC_RearDeforstSts : 17|1@0+ (1,0) [0|1] "" IC_MMI,GW
 SG_ AC_CoolingStaus : 19|2@0+ (1,0) [0|3] "" IC_MMI,GW
 SG_ AC_MaxCooingStaus : 21|2@0+ (1,0) [0|3] "" IC_MMI,GW
 SG_ AC_OffStaus : 22|1@0+ (1,0) [0|1] "" IC_MMI,GW
 SG_ AC_PM25_Status : 24|1@0+ (1,0) [0|1] "" IC_MMI,GW
 SG_ AC_RearViewMirroHeatStatus : 27|2@0+ (1,0) [0|3] "" IC_MMI,GW
 SG_ AC_NegativeIconGenStus : 29|2@0+ (1,0) [0|3] "" IC_MMI,GW

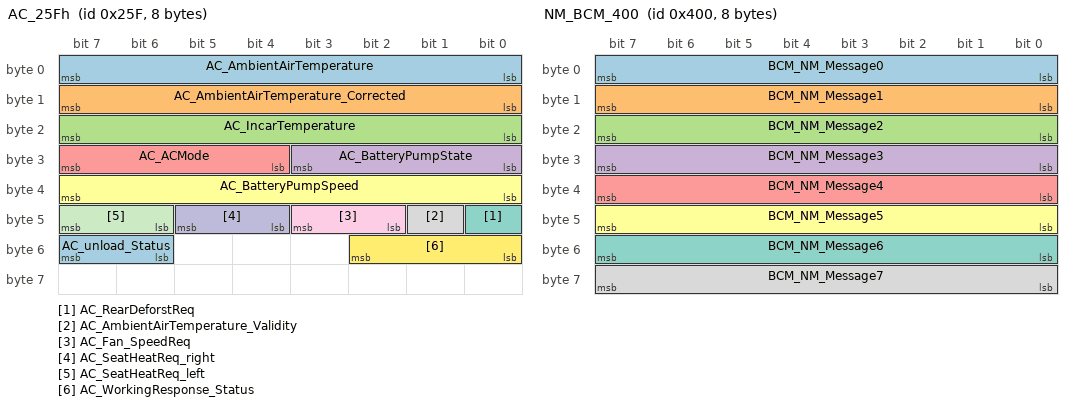
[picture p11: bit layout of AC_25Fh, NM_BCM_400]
BO_ 607 AC_25Fh: 8 AC
 SG_ AC_AmbientAirTemperature : 7|8@0+ (0.5,-40) [-40|87.5] "℃" IC_MMI,GW
 SG_ AC_AmbientAirTemperature_Corrected : 15|8@0+ (0.5,-40) [-40|87.5] "℃" IC_MMI,AVM,GW
 SG_ AC_IncarTemperature : 23|8@0+ (0.5,-40) [-40|87.5] "℃" IC_MMI,GW
 SG_ AC_BatteryPumpState : 27|4@0+ (1,0) [0|15] "" IC_MMI,GW
 SG_ AC_ACMode : 31|4@0+ (1,0) [0|15] "" IC_MMI,GW
 SG_ AC_BatteryPumpSpeed : 39|8@0+ (1,0) [0|100] "%" IC_MMI,GW
 SG_ AC_RearDeforstReq : 40|1@0+ (1,0) [0|1] "" IC_MMI,GW,BCM
 SG_ AC_AmbientAirTemperature_Validity : 41|1@0+ (1,0) [0|1] "" IC_MMI,AVM,GW
 SG_ AC_Fan_SpeedReq : 43|2@0+ (1,0) [0|3] "" IC_MMI,GW
 SG_ AC_SeatHeatReq_right : 45|2@0+ (1,0) [0|3] "" IC_MMI,GW
 SG_ AC_SeatHeatReq_left : 47|2@0+ (1,0) [0|3] "" IC_MMI,GW
 SG_ AC_WorkingResponse_Status : 50|3@0+ (1,0) [0|7] "" IC_MMI,GW
 SG_ AC_unload_Status : 55|2@0+ (1,0) [0|3] "" IC_MMI,GW

BO_ 1024 NM_BCM_400: 8 BCM
 SG_ BCM_NM_Message0 : 7|8@0+ (1,0) [0|255] "" IC_MMI,GW,AC
 SG_ BCM_NM_Message1 : 15|8@0+ (1,0) [0|255] "" IC_MMI,GW,AC
 SG_ BCM_NM_Message2 : 23|8@0+ (1,0) [0|255] "" IC_MMI,GW,AC
 SG_ BCM_NM_Message3 : 31|8@0+ (1,0) [0|255] "" IC_MMI,GW,AC
 SG_ BCM_NM_Message4 : 39|8@0+ (1,0) [0|255] "" IC_MMI,GW,AC
 SG_ BCM_NM_Message5 : 47|8@0+ (1,0) [0|255] "" IC_MMI,GW,AC
 SG_ BCM_NM_Message6 : 55|8@0+ (1,0) [0|255] "" IC_MMI,GW,AC
 SG_ BCM_NM_Message7 : 63|8@0+ (1,0) [0|255] "" IC_MMI,GW,AC

BO_ 338 BCM_152h: 8 BCM
 SG_ BCM_RFDoorSwitchSt : 0|1@0+ (1,0) [0|1] "" IC_MMI,AVM,GW,CWC
 SG_ BCM_LFDoorSwitchSt : 1|1@0+ (1,0) [0|1] "" IC_MMI,AVM,GW,DSM_D,DSM_P,CWC
 SG_ BCM_PositionLampSt : 2|1@0+ (1,0) [0|1] "" IC_MMI,GW
 SG_ BCM_FrontFogligthSt : 3|1@0+ (1,0) [0|1] "" IC_MMI,GW
 SG_ BCM_BackFogligthSt : 4|1@0+ (1,0) [0|1] "" IC_MMI,GW
 SG_ BCM_HighBeamStatus : 5|1@0+ (1,0) [0|1] "" IC_MMI,GW
 SG_ BCM_LowBeamStatus : 6|1@0+ (1,0) [0|1] "" IC_MMI,GW
 SG_ BCM_TrunkSt : 7|1@0+ (1,0) [0|1] "" IC_MMI,AVM,GW
 SG_ BCM_TurnLeverLoc : 9|2@0+ (1,0) [0|3] "" IC_MMI,AVM,GW
 SG_ BCM_RightligthFaultSt : 10|1@0+ (1,0) [0|1] "" IC_MMI,AVM,GW
 SG_ BCM_RightligthSt : 11|1@0+ (1,0) [0|1] "" IC_MMI,AVM,GW
 SG_ BCM_LetfligthFaultSt : 12|1@0+ (1,0) [0|1] "" IC_MMI,AVM,GW
 SG_ BCM_LetfligthSt : 13|1@0+ (1,0) [0|1] "" IC_MMI,AVM,GW
 SG_ BCM_LRDoorSwitchSt : 14|1@0+ (1,0) [0|1] "" IC_MMI,AVM,GW
 SG_ BCM_RRDoorSwitchSt : 15|1@0+ (1,0) [0|1] "" IC_MMI,AVM,GW
 SG_ BCM_CentralLockSt : 16|1@0+ (1,0) [0|1] "" IC_MMI,GW
 SG_ BCM_Reverse_Light : 17|1@0+ (1,0) [0|1] "" IC_MMI,GW
 SG_ BCM_Mainbeam_Available : 18|1@0+ (1,0) [0|1] "" IC_MMI,AVM,GW
 SG_ Bcm_OutSwitchPressCmd : 19|1@0+ (1,0) [0|1] "" IC_MMI,GW
 SG_ BCM_HazardwarnLampSt : 20|1@0+ (1,0) [0|1] "" IC_MMI,AVM,GW
 SG_ BCM_PassSeatbeltBucklestatus : 21|1@0+ (1,0) [0|1] "" IC_MMI,AVM,GW
 SG_ BCM_DrvSeatbeltBucklestatus : 22|1@0+ (1,0) [0|1] "" IC_MMI,AVM,GW
 SG_ BCM_FrontCoverSt : 23|1@0+ (1,0) [0|1] "" IC_MMI,AVM,GW
 SG_ BCM_Humidity : 31|8@0+ (0.39215,0) [0|100] "%" IC_MMI,GW,AC
 SG_ BCM_Auto_LightSwitch : 32|1@0+ (1,0) [0|1] "" IC_MMI,GW
 SG_ BCM_Brake_Light : 33|1@0+ (1,0) [0|1] "" IC_MMI,GW
 SG_ BCM_RearViewMirrorAutoFoldFucFeedback : 35|2@0+ (1,0) [0|3] "" IC_MMI,GW
 SG_ BCM_Rain_Sensor : 37|2@0+ (1,0) [0|3] "" IC_MMI,GW,AC
 SG_ BCM_DrvSeatbeltBucklevalidity : 38|1@0+ (1,0) [0|1] "" IC_MMI,AVM,GW
 SG_ BCM_PassSeatbeltBucklevalidity : 39|1@0+ (1,0) [0|1] "" IC_MMI,AVM,GW
 SG_ BCM_PowerMode : 42|3@0+ (1,0) [0|3] "" IC_MMI,GW,DSM_D,DSM_P,FSCM,CWC
 SG_ BCM_RearViewMirror : 45|2@0+ (1,0) [0|3] "" IC_MMI,GW
 SG_ BCM_ChargeCoverLockStatus : 46|1@0+ (1,0) [0|1] "" IC_MMI,GW
 SG_ BCM_RearDeforstSts : 47|1@0+ (1,0) [0|1] "" IC_MMI,GW,AC
 SG_ BCM_BkSeat_1_beltBucklevalidity : 48|1@0+ (1,0) [0|1] "" IC_MMI,GW
 SG_ BCM_BkSeat_1_beltBucklestatus : 49|1@0+ (1,0) [0|1] "" IC_MMI,GW
 SG_ BCM_BkSeat_2_beltBucklevalidity : 50|1@0+ (1,0) [0|1] "" IC_MMI,GW
 SG_ BCM_BkSeat_2_beltBucklestatus : 51|1@0+ (1,0) [0|1] "" IC_MMI,GW
 SG_ BCM_BkSeat_3_beltBucklevalidity : 52|1@0+ (1,0) [0|1] "" IC_MMI,GW
 SG_ BCM_BkSeat_3_beltBucklestatus : 53|1@0+ (1,0) [0|1] "" IC_MMI,GW
 SG_ BCM_RainAutoClsWindowFuncStus : 55|2@0+ (1,0) [0|3] "" IC_MMI
 SG_ BCM_LockVehicleWarmingTipStus : 57|2@0+ (1,0) [0|3] "" IC_MMI
 SG_ BCM_CourtesyLampStus : 58|1@0+ (1,0) [0|1] "" IC_MMI
 SG_ BCM_VehicleCourtesyLampFuncStus : 61|2@0+ (1,0) [0|3] "" IC_MMI
 SG_ BCM_AccLampSetStus : 63|2@0+ (1,0) [0|3] "" IC_MMI

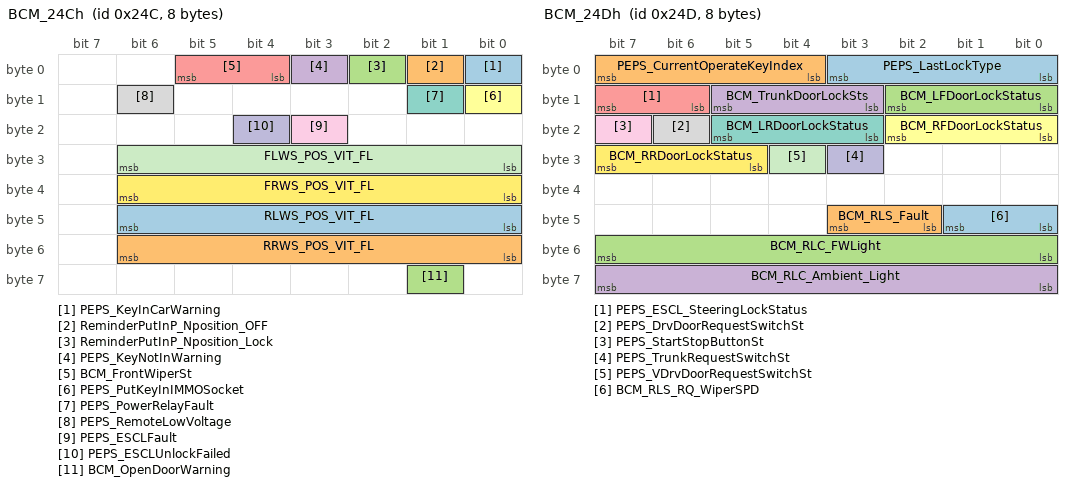
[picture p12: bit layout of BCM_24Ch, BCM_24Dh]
BO_ 588 BCM_24Ch: 8 BCM
 SG_ PEPS_KeyInCarWarning : 0|1@0+ (1,0) [0|1] "" IC_MMI,GW
 SG_ ReminderPutInP_Nposition_OFF : 1|1@0+ (1,0) [0|1] "" IC_MMI,GW
 SG_ ReminderPutInP_Nposition_Lock : 2|1@0+ (1,0) [0|1] "" IC_MMI,GW
 SG_ PEPS_KeyNotInWarning : 3|1@0+ (1,0) [0|1] "" IC_MMI,GW
 SG_ BCM_FrontWiperSt : 5|2@0+ (1,0) [0|3] "" IC_MMI,GW
 SG_ PEPS_PutKeyInIMMOSocket : 8|1@0+ (1,0) [0|1] "" IC_MMI,GW
 SG_ PEPS_PowerRelayFault : 9|1@0+ (1,0) [0|1] "" IC_MMI,GW
 SG_ PEPS_RemoteLowVoltage : 14|1@0+ (1,0) [0|1] "" IC_MMI,GW
 SG_ PEPS_ESCLFault : 19|1@0+ (1,0) [0|1] "" IC_MMI,GW
 SG_ PEPS_ESCLUnlockFailed : 20|1@0+ (1,0) [0|1] "" IC_MMI,GW
 SG_ FLWS_POS_VIT_FL : 30|7@0+ (1,0) [0|100] "%" IC_MMI,GW
 SG_ FRWS_POS_VIT_FL : 38|7@0+ (1,0) [0|100] "%" IC_MMI,GW
 SG_ RLWS_POS_VIT_FL : 46|7@0+ (1,0) [0|100] "%" IC_MMI,GW
 SG_ RRWS_POS_VIT_FL : 54|7@0+ (1,0) [0|100] "%" IC_MMI,GW
 SG_ BCM_OpenDoorWarning : 57|1@0+ (1,0) [0|1] "" IC_MMI,GW

BO_ 589 BCM_24Dh: 8 BCM
 SG_ PEPS_LastLockType : 3|4@0+ (1,0) [0|7] "" IC_MMI,GW
 SG_ PEPS_CurrentOperateKeyIndex : 7|4@0+ (1,0) [0|7] "" IC_MMI,GW
 SG_ BCM_LFDoorLockStatus : 10|3@0+ (1,0) [0|7] "" IC_MMI,GW
 SG_ BCM_TrunkDoorLockSts : 13|3@0+ (1,0) [0|7] "" IC_MMI,GW
 SG_ PEPS_ESCL_SteeringLockStatus : 15|2@0+ (1,0) [0|3] "" IC_MMI,GW
 SG_ BCM_RFDoorLockStatus : 18|3@0+ (1,0) [0|7] "" IC_MMI,GW
 SG_ BCM_LRDoorLockStatus : 21|3@0+ (1,0) [0|7] "" IC_MMI,GW
 SG_ PEPS_DrvDoorRequestSwitchSt : 22|1@0+ (1,0) [0|1] "" IC_MMI,GW
 SG_ PEPS_StartStopButtonSt : 23|1@0+ (1,0) [0|1] "" IC_MMI,GW
 SG_ PEPS_TrunkRequestSwitchSt : 27|1@0+ (1,0) [0|1] "" IC_MMI,GW
 SG_ PEPS_VDrvDoorRequestSwitchSt : 28|1@0+ (1,0) [0|1] "" IC_MMI,GW
 SG_ BCM_RRDoorLockStatus : 31|3@0+ (1,0) [0|7] "" IC_MMI,GW
 SG_ BCM_RLS_RQ_WiperSPD : 41|2@0+ (1,0) [0|3] "" IC_MMI,GW
 SG_ BCM_RLS_Fault : 43|2@0+ (1,0) [0|3] "" IC_MMI,GW,AC
 SG_ BCM_RLC_FWLight : 55|8@0+ (1,0) [0|255] "" IC_MMI,GW,AC
 SG_ BCM_RLC_Ambient_Light : 63|8@0+ (1,0) [0|255] "" IC_MMI,GW

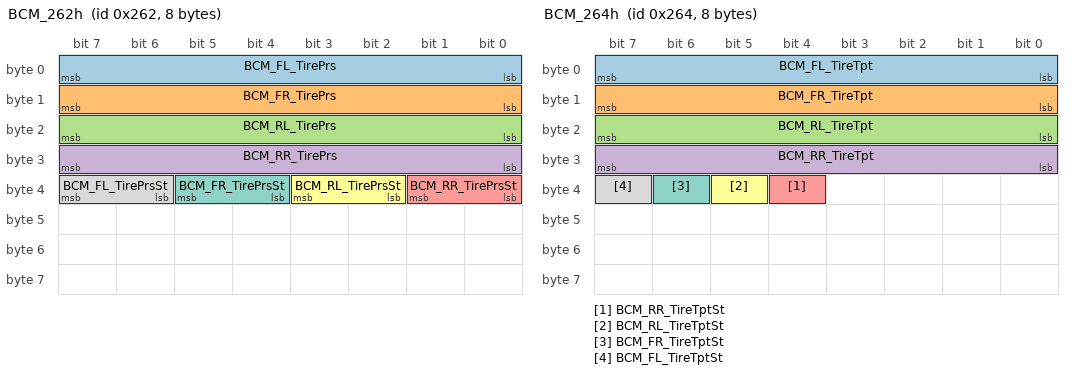
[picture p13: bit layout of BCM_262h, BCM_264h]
BO_ 610 BCM_262h: 8 BCM
 SG_ BCM_FL_TirePrs : 7|8@0+ (1.373,0) [0|348.742] "Kpa" IC_MMI,GW
 SG_ BCM_FR_TirePrs : 15|8@0+ (1.373,0) [0|348.742] "Kpa" IC_MMI,GW
 SG_ BCM_RL_TirePrs : 23|8@0+ (1.373,0) [0|348.742] "Kpa" IC_MMI,GW
 SG_ BCM_RR_TirePrs : 31|8@0+ (1.373,0) [0|348.742] "Kpa" IC_MMI,GW
 SG_ BCM_RR_TirePrsSt : 33|2@0+ (1,0) [0|3] "" IC_MMI,AVM,GW
 SG_ BCM_RL_TirePrsSt : 35|2@0+ (1,0) [0|3] "" IC_MMI,AVM,GW
 SG_ BCM_FR_TirePrsSt : 37|2@0+ (1,0) [0|3] "" IC_MMI,AVM,GW
 SG_ BCM_FL_TirePrsSt : 39|2@0+ (1,0) [0|3] "" IC_MMI,AVM,GW

BO_ 612 BCM_264h: 8 BCM
 SG_ BCM_FL_TireTpt : 7|8@0+ (1,-50) [-50|204] "" IC_MMI,GW
 SG_ BCM_FR_TireTpt : 15|8@0+ (1,-50) [-50|204] "" IC_MMI,GW
 SG_ BCM_RL_TireTpt : 23|8@0+ (1,-50) [-50|204] "" IC_MMI,GW
 SG_ BCM_RR_TireTpt : 31|8@0+ (1,-50) [-50|204] "" IC_MMI,GW
 SG_ BCM_RR_TireTptSt : 36|1@0+ (1,0) [0|1] "" IC_MMI,GW
 SG_ BCM_RL_TireTptSt : 37|1@0+ (1,0) [0|1] "" IC_MMI,GW
 SG_ BCM_FR_TireTptSt : 38|1@0+ (1,0) [0|1] "" IC_MMI,GW
 SG_ BCM_FL_TireTptSt : 39|1@0+ (1,0) [0|1] "" IC_MMI,GW

BO_ 613 BCM_265h: 8 BCM
 SG_ BCM_RR_TireLose : 0|1@0+ (1,0) [0|1] "" IC_MMI,GW
 SG_ BCM_RL_TireLose : 1|1@0+ (1,0) [0|1] "" IC_MMI,GW
 SG_ BCM_FR_TireLose : 2|1@0+ (1,0) [0|1] "" IC_MMI,GW
 SG_ BCM_FL_TireLose : 3|1@0+ (1,0) [0|1] "" IC_MMI,GW
 SG_ BCM_RR_TireLowVol : 4|1@0+ (1,0) [0|1] "" IC_MMI,GW
 SG_ BCM_RL_TireLowVol : 5|1@0+ (1,0) [0|1] "" IC_MMI,GW
 SG_ BCM_FR_TireLowVol : 6|1@0+ (1,0) [0|1] "" IC_MMI,GW
 SG_ BCM_FL_TireLowVol : 7|1@0+ (1,0) [0|1] "" IC_MMI,GW
 SG_ BCM_RR_TestSt : 9|1@0+ (1,0) [0|1] "" IC_MMI,AVM,GW
 SG_ BCM_RL_TestSt : 10|1@0+ (1,0) [0|1] "" IC_MMI,AVM,GW
 SG_ BCM_FR_TestSt : 11|1@0+ (1,0) [0|1] "" IC_MMI,AVM,GW
 SG_ BCM_FL_TestSt : 12|1@0+ (1,0) [0|1] "" IC_MMI,AVM,GW
 SG_ BCM_BatVol_ErrFlag : 13|1@0+ (1,0) [0|1] "" IC_MMI,GW
 SG_ BCM_TPMS_TestSt : 15|2@0+ (1,0) [0|3] "" IC_MMI,AVM,GW
 SG_ BCM_RR_Quikleakage : 20|1@0+ (1,0) [0|1] "" IC_MMI,AVM,GW
 SG_ BCM_RL_Quikleakage : 21|1@0+ (1,0) [0|1] "" IC_MMI,AVM,GW
 SG_ BCM_FR_Quikleakage : 22|1@0+ (1,0) [0|1] "" IC_MMI,AVM,GW
 SG_ BCM_FL_Quikleakage : 23|1@0+ (1,0) [0|1] "" IC_MMI,AVM,GW

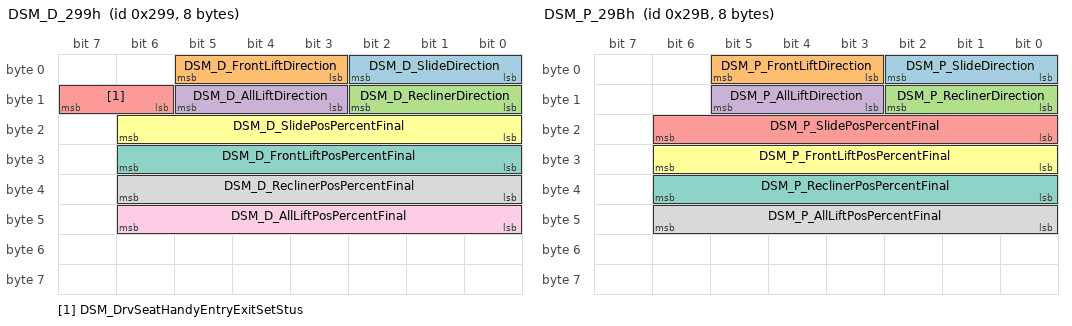
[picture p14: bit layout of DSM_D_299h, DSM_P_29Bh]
BO_ 665 DSM_D_299h: 8 DSM_D
 SG_ DSM_D_SlideDirection : 2|3@0+ (1,0) [0|3] "" IC_MMI
 SG_ DSM_D_FrontLiftDirection : 5|3@0+ (1,0) [0|3] "" IC_MMI
 SG_ DSM_D_ReclinerDirection : 10|3@0+ (1,0) [0|3] "" IC_MMI
 SG_ DSM_D_AllLiftDirection : 13|3@0+ (1,0) [0|3] "" IC_MMI
 SG_ DSM_DrvSeatHandyEntryExitSetStus : 15|2@0+ (1,0) [0|3] "" IC_MMI
 SG_ DSM_D_SlidePosPercentFinal : 22|7@0+ (1,0) [0|100] "%" IC_MMI
 SG_ DSM_D_FrontLiftPosPercentFinal : 30|7@0+ (1,0) [0|100] "%" IC_MMI
 SG_ DSM_D_ReclinerPosPercentFinal : 38|7@0+ (1,0) [0|100] "%" IC_MMI
 SG_ DSM_D_AllLiftPosPercentFinal : 46|7@0+ (1,0) [0|100] "%" IC_MMI

BO_ 667 DSM_P_29Bh: 8 DSM_P
 SG_ DSM_P_SlideDirection : 2|3@0+ (1,0) [0|3] "" IC_MMI
 SG_ DSM_P_FrontLiftDirection : 5|3@0+ (1,0) [0|3] "" IC_MMI
 SG_ DSM_P_ReclinerDirection : 10|3@0+ (1,0) [0|3] "" IC_MMI
 SG_ DSM_P_AllLiftDirection : 13|3@0+ (1,0) [0|3] "" IC_MMI
 SG_ DSM_P_SlidePosPercentFinal : 22|7@0+ (1,0) [0|100] "%" IC_MMI
 SG_ DSM_P_FrontLiftPosPercentFinal : 30|7@0+ (1,0) [0|100] "%" IC_MMI
 SG_ DSM_P_ReclinerPosPercentFinal : 38|7@0+ (1,0) [0|100] "%" IC_MMI
 SG_ DSM_P_AllLiftPosPercentFinal : 46|7@0+ (1,0) [0|100] "%" IC_MMI

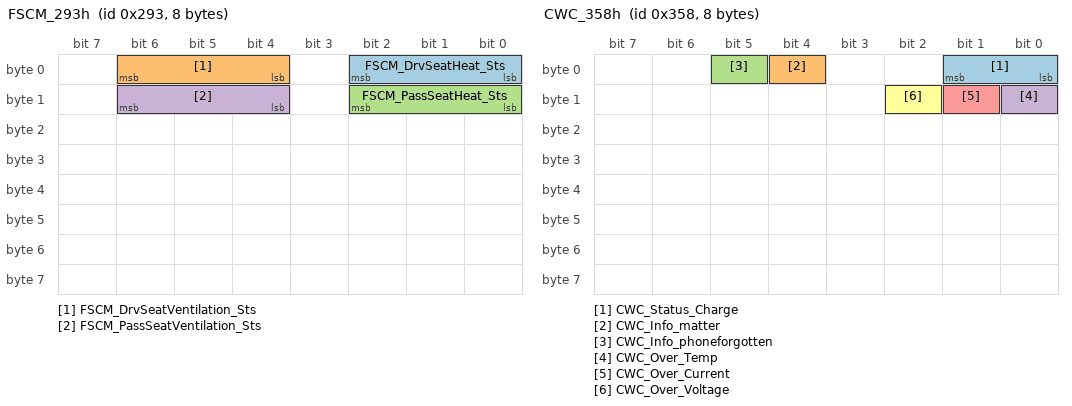
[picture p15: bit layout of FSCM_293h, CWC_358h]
BO_ 659 FSCM_293h: 8 FSCM
 SG_ FSCM_DrvSeatHeat_Sts : 2|3@0+ (1,0) [0|7] "" IC_MMI,GW
 SG_ FSCM_DrvSeatVentilation_Sts : 6|3@0+ (1,0) [0|7] "" IC_MMI,GW
 SG_ FSCM_PassSeatHeat_Sts : 10|3@0+ (1,0) [0|7] "" IC_MMI,GW
 SG_ FSCM_PassSeatVentilation_Sts : 14|3@0+ (1,0) [0|7] "" IC_MMI,GW

BO_ 856 CWC_358h: 8 CWC
 SG_ CWC_Status_Charge : 1|2@0+ (1,0) [0|3] "" IC_MMI
 SG_ CWC_Info_matter : 4|1@0+ (1,0) [0|1] "" IC_MMI
 SG_ CWC_Info_phoneforgotten : 5|1@0+ (1,0) [0|1] "" IC_MMI
 SG_ CWC_Over_Temp : 8|1@0+ (1,0) [0|1] "" IC_MMI
 SG_ CWC_Over_Current : 9|1@0+ (1,0) [0|1] "" IC_MMI
 SG_ CWC_Over_Voltage : 10|1@0+ (1,0) [0|1] "" IC_MMI

CM_ SG_ 530 BMS_Sys_MinCellT "Minimum temperature
最小温度";
CM_ SG_ 530 BMS_Sys_MaxCellT "Maximum temperature
最大温度";
CM_ SG_ 530 BMS_Sys_MinCellT_No "Minimum temperature range
最小温度位置";
CM_ SG_ 530 BMS_Sys_MaxCellT_No "Maximum temperature position
最大温度位置";
CM_ SG_ 530 BMS_FastChrgTemp "Fast Charging gun surface temperature
快充电枪表面温度";
CM_ SG_ 534 BMS_PosInsulationResistance "Cathode Insulation Resistance value
正极绝缘电阻值";
CM_ SG_ 534 BMS_NegInsulationResistance "Cathode Insulation Resistance value
负极绝缘电阻值";
CM_ SG_ 534 BMS_Sys_SOC "State Of Charge
电池SOC";
CM_ SG_ 534 BMS_Sys_SOH "State Of Health
电池SOH";
CM_ SG_ 340 RCTA_warm_status_left "后方交叉路口左侧车辆报警";
CM_ SG_ 340 BSDLCA_warm_status_left "左侧有车警告";
CM_ SG_ 340 BSD_ConnectionFault_left "左雷达异常报警";
CM_ SG_ 340 BSD_RFICFault_left "左雷达RFIC异常报警";
CM_ SG_ 340 BSD_OverTempFault_left "左雷达温度异常报警";
CM_ SG_ 340 BSD_StoreFault_left "左雷达存储异常报警";
CM_ SG_ 340 BSDDOW_warm_status_left "DOW左侧有车警告";
CM_ SG_ 340 BSD_EnableStatus "开关机状态反馈";
CM_ SG_ 344 RCTA_warm_status_right "后方交叉路口右侧车辆报警";
CM_ SG_ 344 BSDLCA_warm_status_right "右侧有车警告";
CM_ SG_ 344 BSD_ConnectionFault_right "右雷达异常报警";
CM_ SG_ 344 BSD_RFICFault_right "右雷达RFIC异常报警";
CM_ SG_ 344 BSD_OverTempFault_right "右雷达温度异常报警";
CM_ SG_ 344 BSD_StoreFault_right "右雷达存储异常报警";
CM_ SG_ 344 BSDDOW_warm_status_right "DOW右侧有车警告";
CM_ SG_ 148 EHB_AEB_Available "Indicates if EHB is ready to response AEB system decelerate request
指示EHB是否准备好响应AEB系统请求";
CM_ SG_ 148 EHB_ACC_Available "Indicates if EHB is ready to response ACC system decelerate request
指示EHB是否准备好响应ACC系统请求";
CM_ SG_ 148 EHB_BrkPelPosActVD "The actual value of brake pedal position validity
刹车踏板位置的实际值有效性";
CM_ SG_ 148 EHB_FaultSt "EHB Fault State
EHB 故障状态";
CM_ SG_ 148 EHB_BrkPelPosAct "The actual value of brake pedal position
刹车踏板位置的实际值";
CM_ SG_ 148 EHB_AEB_Jerk_Response "The signal indicates if ESP responsed AEB Jerk request or not
指示EHB是否响应了AEB的jerk请求";
CM_ SG_ 148 EHB_AEB_Request_Response "The signal indicates if ESP responsed AEB decelerate request or not
指示EHB是否响应了AEB的减速请求";
CM_ SG_ 148 EHB_Prefill_Response "The signal indicates if ESP responsed prefill request or not
指示EHB是否响应了AEB的预充请求";
CM_ SG_ 148 EHB_ACC_Request_Response "The signal indicates if ESP responsed ACC decelerate request or not
指示EHB是否响应了ACC的减速请求";
CM_ SG_ 148 EHB_RegTorqReqVD "Regeneration Torque Request validity
再生扭矩请求有效性";
CM_ SG_ 148 EHB_RegTorqReqWhl "Regeneration Torque Request(Wheel)
再生扭矩请求(轮端)";
CM_ SG_ 148 EHB_BrakePedalAppliedSt "Brake pedal step down state
制动踏板踩下状态";
CM_ SG_ 148 EHB_94h_AliveCounter "消息计数器";
CM_ SG_ 148 EHB_BrakePedalApplied_Validity "Brake pedal step under state effective position
制动踏板踩下状态有效位";
CM_ SG_ 148 EHBDiagActive "Nbooster Diagnostic Marker Bit
Nbooster诊断标志位";
CM_ SG_ 148 EHB_BrkLightAct "Lighting brake lights In response to ADAS braking
响应ADAS制动时点亮制动灯";
CM_ SG_ 148 EHB_Hold "Indicates whether EHB  keeping the vehicle at stationary state
指示EHB是否将车辆保持在静止状态";
CM_ SG_ 148 EHB_Hold_Available "Indicates whether EHB  can keep the vehicle at stationary state
指示EHB当前是否具备龅牙驻车的能力";
CM_ SG_ 148 EHB_94h_Checksum "校验和";
CM_ SG_ 328 EPB_TMM_Open_Request_L "TMM open request_reserved
四驱断开请求";
CM_ SG_ 328 EPB_Brake_Lights_Request_L "brake lights request
点亮刹车灯请求";
CM_ SG_ 328 EPB_SwitchSta_L "EPB Switch State 
EPB开关状态";
CM_ SG_ 328 EPB_WarnLampSta_L "EPB Warning Lamp State
EPB故障灯状态";
CM_ SG_ 328 EPB_ParkLampSta_L "Park Lamp State
驻车灯状态";
CM_ SG_ 328 EPB_DynamicApplySta_L "Dynamic Apply Status
动态制动状态";
CM_ SG_ 328 EPB_ActuatorSt_L "Lift EPB Actuator State
左Moc状态";
CM_ SG_ 328 EPB_Dclrtin_request_status_L "ESC deceleration request status
ESC减速请求状态";
CM_ SG_ 328 EPB_CC_Cancel_Request_L "CC cancle request
巡航退出请求";
CM_ SG_ 328 EPB_DisplayMsgID_L "Display  Message ID Requested by EPB to ICU   仪表文字提示信息";
CM_ SG_ 328 EPB_DecelReq_L "EPB Deceleration Request
EPB减速度请求";
CM_ SG_ 328 EPB_G_sensor_L "Acceleration sensor values
加速度传感器值";
CM_ SG_ 328 EPB_148h_RollingCounter "Rolling counter
循环计数器";
CM_ SG_ 328 EPB_148h_CheckSUM "校验和
checksum = (Byte0+Byte1 …+ Byte6) XOR 0xFF";
CM_ SG_ 336 EPB_TMM_Open_Request__R "TMM open request_reserved
四驱断开请求";
CM_ SG_ 336 EPB_Brake_Lights_Request_R "brake lights request
点亮刹车灯请求";
CM_ SG_ 336 EPB_SwitchSta_R "EPB Switch State 
EPB开关状态";
CM_ SG_ 336 EPB_WarnLampSta_R "EPB Warning Lamp State
EPB故障灯状态";
CM_ SG_ 336 EPB_ParkLampSta_R "Park Lamp State
驻车灯状态";
CM_ SG_ 336 EPB_DynamicApplySta_R "Dynamic Apply Status
动态制动状态";
CM_ SG_ 336 EPB_ActuatorSt_R "Right EPB Actuator State
右 EPD 执行器状态";
CM_ SG_ 336 EPB_Dclrtin_request_status_R "ESC deceleration request status
ESC减速请求状态";
CM_ SG_ 336 EPB_CC_Cancel_Request_R "CC cancle request
巡航退出请求";
CM_ SG_ 336 EPB_DisplayMsgID_R "Display  Message ID Requested by EPB to ICU   
仪表文字提示信息";
CM_ SG_ 336 EPB_DecelReq_R "EPB Deceleration Request
EPB减速度请求";
CM_ SG_ 336 EPB_G_sensor_R "Acceleration sensor values
加速度传感器值";
CM_ SG_ 336 EPB_150h_RollingCounter "Rolling counter
循环计数器";
CM_ SG_ 336 EPB_150h_CheckSUM "校验和
checksum = (Byte0+Byte1 …+ Byte6) XOR 0xFF";
CM_ SG_ 274 EPS_SteeringWheelAngVD "EPS steering wheel angle Valid Status
EPS中测量的方向盘转角信号有效性标识位";
CM_ SG_ 274 EPS_SASFailureSts "EPS SAS Failure Status
EPS中的转角传感器失效状态";
CM_ SG_ 274 EPS_TorsionBarTorqueValid "Validation bit of measured torsion bar torque.
转向杆扭矩有效位";
CM_ SG_ 274 EPS_TorsionBarTorqueDir "Direction of measured torsion bar torque
转向杆扭矩方向（左正右负）";
CM_ SG_ 274 EPS_Fault "Fault Lamp Status
故障灯状态";
CM_ SG_ 274 EPS_TorsionBarTorque "Measired torsion bar torque （Driver hand torque）
转向杆扭矩（驾驶员手力矩）";
CM_ SG_ 274 EPS_SteeringWheelAng "EPS steering wheel angle
EPS中测量的方向盘转角(左正右负)";
CM_ SG_ 274 EPS_SteerWheelRotSpd "EPS Steering wheel rotational speed
EPS中测量的方向盘转角速度";
CM_ SG_ 274 MMI_EpsModeFeedback "EPS多助力模式反馈（预留）";
CM_ SG_ 274 EPS_SteerWheelRotSpdVD "EPS Steering wheel rotational speed Valid Status
EPS中测量的方向盘转角速度有效性标识位";
CM_ SG_ 274 EPS_112h_RollingCounter "Rolling counter
循环计数器";
CM_ SG_ 274 EPS_112h_CheckSUM "校验和
checksum = (Byte0+Byte1 …+ Byte6) XOR 0xFF";
CM_ SG_ 144 ESC_TCSActive "TCS work or not 
TCS是否工作";
CM_ SG_ 144 ESC_HHC_Failure "HHC normal or not
HHC是否正常运行";
CM_ SG_ 144 ESC_HHCActive "HHC work or not 
HHC是否工作";
CM_ SG_ 144 ESC_EBDFailed "EBD normal or not
EBD是否正常运行";
CM_ SG_ 144 ESC_EBDActive "EBD work or not
EBD是否工作";
CM_ SG_ 144 ESC_RBSState "Regenate brake allow flag
回馈制动允许标志位";
CM_ SG_ 144 ESC_ABSFailed "ABS normal or not
是否正常运行";
CM_ SG_ 144 ESC_ABSActive "ABS work or not
ABS是否工作";
CM_ SG_ 144 ESC_AVHactive "AVH work or not 
AVH是否工作";
CM_ SG_ 144 ESC_AutoholdStandby "Autohold standby
Autohold功能待机";
CM_ SG_ 144 ESC_AutoholdFailure "Autohold failure
Autohold功能故障";
CM_ SG_ 144 ESC_Sw "ESC OFF switch
ESC OFF开关";
CM_ SG_ 144 ESC_HBAActive "HBA work or not 
HBA是否工作";
CM_ SG_ 144 ESC_VDCFailure "VDC normal or not
VDC是否正常运行";
CM_ SG_ 144 ESC_VDCActive "VDC work or not 
VDC是否工作";
CM_ SG_ 144 ESC_TCSFailure "TCS normal or not
TCS是否正常运行";
CM_ SG_ 144 ESC_CDPAvailable "Controlled Deceleration for
Parking Brake Available
停车制动减速控制可用";
CM_ SG_ 144 ESC_CDPActive "Controlled Deceleration for
Parking Brake Active
停车制动减速控制有效";
CM_ SG_ 144 ESC_EPBRequest "EPB request
EPB请求";
CM_ SG_ 144 ESC_BrkPrs "Brake pressure
刹车压力";
CM_ SG_ 144 ESC_AVH_Warning1 "warming: Please close driver door ,then press AVH switch 
提醒：请关好驾驶员侧车门，再按下AVH开关";
CM_ SG_ 144 ESC_AVH_Warning2 "warming: Please tie driver seat belt buckle,then press AVH switch 
提醒：请系好驾驶员安全带，再按下AVH开关";
CM_ SG_ 144 ESC_AVH_Warning3 "warming: Please Ready ,then press AVH switch 
提醒：请车辆Ready，再按下AVH开关";
CM_ SG_ 144 ESC_AVH_Warning4 "warming: Please press break switch,then press AVH switch 
提醒：请踩下制动踏板，再按下AVH开关";
CM_ SG_ 144 ESC_Brake_Light_Control "Request Lighting Brake Lamp
请求点亮制动灯";
CM_ SG_ 144 ESC_BrkPrsVd "Brake pressure active
刹车压力有效";
CM_ SG_ 144 ESC_90h_RollingCounter "Rolling counter
循环计数器";
CM_ SG_ 144 ESC_90h_CheckSUM "校验和
checksum = (Byte0+Byte1 …+ Byte6) XOR 0xFF";
CM_ SG_ 146 ESC_VehSpd "Speed,sending 0x7FFF when invalid
车速，当无效时发送0x7FFF";
CM_ SG_ 146 ESC_WhlFLSpd "Left front wheel wheel speed
左前轮轮速";
CM_ SG_ 146 ESC_WhlFRSpd "Right front wheel wheel speed
右前轮轮速";
CM_ SG_ 146 ESC_92h_RollingCounter "Rolling counter
循环计数器";
CM_ SG_ 146 ESC_WhlSpdFRVd "Right front wheel speed signal validity
右前轮速信号有效性";
CM_ SG_ 146 ESC_WhlSpdFLVd "Left front wheel speed signal validity
左前轮速信号有效性";
CM_ SG_ 146 ESC_VehSpdVd "Speed Signal validity
车速信号有效性";
CM_ SG_ 146 ESC_92h_CheckSUM "校验和
checksum = (Byte0+Byte1 …+ Byte6) XOR 0xFF";
CM_ SG_ 342 SteerWheel_L_OK "左确认键";
CM_ SG_ 342 SteerWheel_Voice "语音";
CM_ SG_ 342 SteerWheel_VOL_Inc "音量+";
CM_ SG_ 342 SteerWheel_VOL_Dec "音量-/静音";
CM_ SG_ 342 SteerWheel_PREV "上一曲/上一页";
CM_ SG_ 342 SteerWheel_Defi "自定义开关";
CM_ SG_ 342 SteerWheel_NEXT "下一曲/下一页";
CM_ SG_ 342 SteerWheel_Mode "MODE开关(MENU)";
CM_ SG_ 342 SteerWheel_Return_Home "返回/主页开关";
CM_ SG_ 342 AmphereLampSta_IntePerSW "氛围灯智能感知开关状态";
CM_ SG_ 342 SteerWheel_Hang_Down "接/挂电话";
CM_ SG_ 342 AmphereLampMode "氛围灯模式";
CM_ SG_ 342 AmphereLampUserDefModeStatus "氛围灯用户自定义模式状态";
CM_ SG_ 342 AmphereLampSta_SW "氛围灯开关状态";
CM_ SG_ 342 AmphereLampSta_Colour "氛围灯颜色状态";
CM_ SG_ 342 AmphereLampBrtnsVal "氛围灯亮度值（0-100%）";
CM_ SG_ 594 MCU_F_FailureNum "Number of current failures
当前故障数目";
CM_ SG_ 594 MCU_F_ResolverFault "MCU spin fault
MCU旋变故障";
CM_ SG_ 594 MCU_F_Err_IGBT "IGBT fault
IGBT故障";
CM_ SG_ 594 MCU_F_CurrentOverload "Overcurrent State
过流状态";
CM_ SG_ 594 MCU_F_Controllertemp_Status "Drive Motor controller Temperature state
驱动电机控制器温度状态";
CM_ SG_ 594 MCU_F_stDischg "Active discharge Status
主动放电状态";
CM_ SG_ 594 MCU_F_SpeedOtLoopFalult "Out Speed Loop Response Failure
外部转速环响应故障";
CM_ SG_ 594 MCU_F_MdTepErr "Module temperature Detection Value exception
模块温度检测值异常";
CM_ SG_ 594 MCU_F_ControllerOverVolt_Status "Overvoltage State of Motor controller
电机控制器过压状态";
CM_ SG_ 594 MCU_F_MotorTemp_Fault "Drive Motor Temperature Alarm
驱动电机温度报警";
CM_ SG_ 594 MCU_F_MotorOverSpd "Motor Overspeed Failure
电机超速故障";
CM_ SG_ 594 MCU_F_VCUCommErr "Abnormal communication with VCU
与VCU通讯异常";
CM_ SG_ 594 MCU_F_ControllerLowUnderVolt_Status "Low pressure undervoltage State of motor controller
电机控制器低压欠压状态";
CM_ SG_ 594 MCU_F_ControllerUnderVolt_Status "Voltage State of Motor controller
电机控制器欠压状态";
CM_ SG_ 594 MCU_F_ControllerFault "Motor Controller Failure
电机控制器故障";
CM_ SG_ 594 FMCU_HV_Interlock_Falult "FMCU HV Interlock Falult                                              前电机高压互锁故障";
CM_ SG_ 594 FMCU_Uncap_Falult "FMCU uncap fault                                                      前电控开盖故障";
CM_ SG_ 594 MCU_F_MotTepErr "Abnormal motor temperature detection value
电机温度检测值异常";
CM_ SG_ 130 MCU_F_stMode "PEB Current operating mode
PEB当前运行模式";
CM_ SG_ 130 MCU_F_TrqCurrValid "Motor Torque Signal Failure
电机扭矩信号有效性";
CM_ SG_ 130 MCU_F_TrqCurr "Current actual Axle torque of the motor
电机当前实际扭矩(轴端)";
CM_ SG_ 130 MCU_F_NCurr "Current actual Axle speed of the motor
电机当前实际转速(轴端)";
CM_ SG_ 130 MCU_F_NCurrValid "EV Motor Speed Signal Failure
EV电机转速信号有效性";
CM_ SG_ 130 MCU_F_UdcCurr "Current actual voltage of Busbar
母线当前实际电压";
CM_ SG_ 130 MCU_F_82h_RollingCounter "Rolling counter
循环计数器";
CM_ SG_ 130 MCU_F_82h_CheckSUM "校检和 checksum = (Byte0+Byte1 …+ Byte6) XOR 0xFF";
CM_ SG_ 132 MCU_F_ControlerTemp "Front MCU Controler Temperature
前电机控制器温度";
CM_ SG_ 132 MCU_F_TempCurr "Actual temperature of front motor
前电机实际温度";
CM_ SG_ 580 MCU_R_ControlerTemp "Rear MCU Controler Temperature
后电机控制器温度";
CM_ SG_ 580 MCU_R_TempCurr "Actual temperature of rear motor
后电机实际温度";
CM_ SG_ 608 MCU_R_FailureNum "Number of current failures
当前故障数目";
CM_ SG_ 608 MCU_R_ResolverFault "MCU spin fault
MCU旋变故障";
CM_ SG_ 608 MCU_R_Err_IGBT "IGBT fault
IGBT故障";
CM_ SG_ 608 MCU_R_CurrentOverload "Overcurrent State
过流状态";
CM_ SG_ 608 MCU_R_Controllertemp_Status "Drive Motor controller Temperature state
驱动电机控制器温度状态";
CM_ SG_ 608 MCU_R_stDischg "Active discharge Status
主动放电状态";
CM_ SG_ 608 MCU_R_SpeedOtLoopFalult "Out Speed Loop Response Failure
外部转速环响应故障";
CM_ SG_ 608 MCU_R_MdTepErr "Module temperature Detection Value exception
模块温度检测值异常";
CM_ SG_ 608 MCU_R_ControllerOverVolt_Status "Overvoltage State of Motor controller
电机控制器过压状态";
CM_ SG_ 608 MCU_R_MotorTemp_Fault "Drive Motor Temperature Alarm
驱动电机温度报警";
CM_ SG_ 608 MCU_R_MotorOverSpd "Motor Overspeed Failure
电机超速故障";
CM_ SG_ 608 MCU_R_VCUCommErr "Abnormal communication with VCU
与VCU通讯异常";
CM_ SG_ 608 MCU_R_ControllerLowUnderVolt_Status "Low pressure undervoltage State of motor controller
电机控制器低压欠压状态";
CM_ SG_ 608 MCU_R_ControllerUnderVolt_Status "Voltage State of Motor controller
电机控制器欠压状态";
CM_ SG_ 608 MCU_R_ControllerFault "Motor Controller Failure
电机控制器故障";
CM_ SG_ 608 RMCU_HV_Interlock_Falult "RMCU HV Interlock Falult                                              前电机高压互锁故障";
CM_ SG_ 608 RMCU_Uncap_Falult "RMCU uncap fault                                                      前电控开盖故障";
CM_ SG_ 608 MCU_R_MotTepErr "Abnormal motor temperature detection value
电机温度检测值异常";
CM_ SG_ 178 MCU_R_stMode "PEB Current operating mode
PEB当前运行模式";
CM_ SG_ 178 MCU_R_TrqCurrValid "Motor Torque Signal Failure
电机扭矩信号有效性";
CM_ SG_ 178 MCU_R_TrqCurr "Current actual Axle torque of the motor
电机当前实际扭矩(轴端)";
CM_ SG_ 178 MCU_R_Ncurr "Current actual Axle speed of the motor
电机当前实际转速(轴端)";
CM_ SG_ 178 MCU_R_NCurrValid "EV Motor Speed Signal Failure
EV电机转速信号有效性";
CM_ SG_ 178 MCU_R_UdcCurr "Current actual voltage of Busbar
母线当前实际电压";
CM_ SG_ 178 MCU_R_B2h_RollingCounter "Rolling counter
循环计数器";
CM_ SG_ 178 MCU_R_B2h_CheckSUM "校检和 checksum = (Byte0+Byte1 …+ Byte6) XOR 0xFF";
CM_ BO_ 772 "充电有关的信号2";
CM_ SG_ 772 OBC_out_Cur_over_prot "Charger Output Current Over Fault
充电机输出过流保护";
CM_ SG_ 772 OBC_out_vol_Less_prot "Charger Input Voltage Less Fault
充电机输出欠压保护";
CM_ SG_ 772 OBC_out_vol_over_prot "Charger Output Voltage Over Faul
充电机输出过压保护";
CM_ SG_ 772 OBC_In_Cur_over_prot "Charger Input Current Over Fault
充电机输入过流保护";
CM_ SG_ 772 OBC_ChargerInputVoltageLessFault "Charger Input Voltage Less Fault
充电机输入电压欠压保护";
CM_ SG_ 772 OBC_ChargerInputVoltageOverFault "Charger Input Voltage Over Fault
充电机输入电压过压保护";
CM_ SG_ 772 ChargeInterfaceOverTemp "Charger Temperature Over Fault
充电口过温";
CM_ SG_ 772 ChargeInterfacetemperature "Charger Temperature
充电口温度";
CM_ SG_ 772 OBC_ControllerTemp "OBC Controller Temperature
充电机控制器温度";
CM_ SG_ 772 OBC_ChargerOTP "Charger Over Temperature Protection
OBC过温保护状态";
CM_ SG_ 772 OBC_ChargerCoolingRequest "Request of OBC Cooling                                           充电机冷却请求";
CM_ SG_ 772 OBC_ChargerHardwareFault "Charger Hardware Fault
OBC硬件故障";
CM_ SG_ 772 OBC_Charger_CAN_Fault "CAN_Fault                                                                                              CAN故障";
CM_ SG_ 772 OBC_Charger_Fail_State "OBC Fail State                                                             充电机故障状态";
CM_ SG_ 772 OBC_Charger_NoBatt "NoBatt                                                                          充电机未检测到电池包或电池电压过低";
CM_ SG_ 772 OBC_CP_DutyCycleValue "CP DutyCycleValue                                                                                CP占空比数值";
CM_ SG_ 772 OBC_CP_Rsv "OBC_CP
外部能量状态";
CM_ SG_ 772 OBC_CC_Resistance "OBC_CC
充电连接CC状态";
CM_ SG_ 772 OBC_ChargerStatus "Charger  Status
OBC状态";
CM_ SG_ 772 KL30_UnderVolt "KL30_UnderVolt                                                                                     KL30电源过欠压";
CM_ SG_ 772 ElectronicLockSts "ElectronicLockSts                                                电子锁状态";
CM_ SG_ 772 ElectronicLockFault "ElectronicLockFault                                               电子锁故障状态";
CM_ SG_ 772 OBC_Charger_Instructions "AC Charge Indicator
交流充电指示";
CM_ SG_ 772 OBC_Charger_Request "AC Chargee Req
交流充电请求";
CM_ SG_ 770 DCDC_Voltage_Input "DCDC Input Voltage
DCDC输入电压";
CM_ SG_ 770 DCDC_Voltage_Output "DCDC Output Voltage
DCDC输出电压";
CM_ SG_ 770 DCDC_Current_Input "DCDC Input Current 
DCDC输入电流";
CM_ SG_ 770 DCDC_Current_Output "DCDC Output Current
DCDC输出电流";
CM_ BO_ 776 "DCDC有关的信号2";
CM_ SG_ 776 DCDC_Status "DCDC Controller Status
DCDC控制器状态";
CM_ SG_ 776 DCDC_IN_vol_over_prot "DCDC Input overvoltage Protection
DCDC输入过压保护";
CM_ SG_ 776 DCDC_IN_vol_Less_prot "DCDC Input undervoltage Protection
DCDC输入欠压保护";
CM_ SG_ 776 DCDC_short_err "DCDC Output Short Circuit fault
DCDC输出短路保护";
CM_ SG_ 776 DCDC_Out_Curr_Over_prot "DCDC OutputOverCurr                                   DCDC输出过流";
CM_ SG_ 776 DCDC_out_vol_over_prot "DCDC Output overvoltage Protection
DCDC输出过压保护";
CM_ SG_ 776 DCDC_out_vol_Less_prot "DCDC Output Undervoltage Protection
DCDC输出欠压保护";
CM_ SG_ 776 DCDC_out_VolSt "DCDC Output End Voltage state
DCDC输出端电压状态";
CM_ SG_ 776 DCDC_Fault "DCDC Controller Fault Alarm
DCDC控制器故障报警";
CM_ SG_ 776 DCDC_OverTemp_Fault "DCDC temperature is too high to malfunction
DCDC温度过高故障";
CM_ SG_ 776 DCDC_WorkingMode "DCDC WorkingMode                                                                               DCDC工作模式";
CM_ SG_ 776 DCDC_EnableSts "DCDC EnableStates                                                                              DCDC使能状态反馈";
CM_ SG_ 776 DCDC_CoolingReq "Request of DCDC Cooling                                DCDC冷却请求";
CM_ SG_ 776 DCDC_ControllerTemp "DCDC Controller Temperature
DCDC控制器温度";
CM_ SG_ 372 VCU_Err_BrakeSwitch "Brake Switch fault
制动开关故障";
CM_ SG_ 372 VCU_Err_BrakePedal "Brake pedal Failure
制动踏板故障(预留)";
CM_ SG_ 372 VCU_Err_AccPedal "Throttle Pedal Failure
油门踏板故障";
CM_ SG_ 372 VCU_GearPosition "Gear status (R\/N\/D/P)
档位状态（R/N/D/P）";
CM_ SG_ 372 VCU_PrechrgAnodeRelay_Status "Pre-recharge CONTACTOR status (reserved)
预充接触器状态（预留）";
CM_ SG_ 372 VCU_DischrgAnodeRelay_Control "Main CONTACTOR (discharge main connector) control
主接触器（放电主接）控制";
CM_ SG_ 372 VCU_DischrgAnodeRelay_Status "Main contactor (discharge main connection) status (reserved)
主接触器（放电主接）状态（预留）";
CM_ SG_ 372 VCU_DischrgCathodeRelay_Control "Cathode CONTACTOR Control
负极接触器控制";
CM_ SG_ 372 VCU_DischrgCathodeRelay_status "Cathode contactor Status (reserved)
负极接触器状态（预留）";
CM_ SG_ 372 VCU_PrechrgAnodeRelay_Control "Pre-recharge CONTACTOR control
预充接触器控制";
CM_ SG_ 372 VCU_PTSystem_Satus "Power system fault Status
动力系统故障状态";
CM_ SG_ 372 VCU_VehSysStatus "Full Vehicle system status
整车系统状态";
CM_ SG_ 372 VCU_ChrgRelay_Control "Charging CONTACTOR Control
充电接触器控制";
CM_ SG_ 372 VCU_Cruise_MainSwitch "Main Cruise Switch
主巡航开关";
CM_ SG_ 372 VCU_OperationMode "Running mode
运行模式";
CM_ SG_ 372 VCU_DrivingMode "Driving mode
驱动模式(两驱或四驱)";
CM_ SG_ 372 VCU_SpeedMode "Speed mode
转速模式";
CM_ SG_ 372 VCU_TortoiseIndicator "Turtle Speed Lamp Indication
龟速灯指示";
CM_ SG_ 372 VCU_Comd_OpenHazardWarningLamp "Turn on the double flash
打开双闪";
CM_ SG_ 372 VCU_ActiveDischargeOrder "Active Discharge Command
主动泄放命令";
CM_ SG_ 372 VCU_Cruise_Enable "Cruise enable
巡航使能";
CM_ SG_ 372 VCU_174h_RollingCounter "Rolling counter
循环计数器";
CM_ SG_ 372 VCU_UnlockSts "VCU anti-theft cancellation status
VCU防盗解除状态";
CM_ SG_ 372 VCU_StartAllow "Vehicle Start Allowed
车辆启动允许";
CM_ SG_ 372 VCU_174h_CheckSUM "校检和 checksum = (Byte0+Byte1 …+ Byte6) XOR 0xFF";
CM_ SG_ 568 VCU_AllowedMaxDisChrgPowerOfAC "AC Maximum allowable discharge power
AC最大允许放电功率(总系统功率)";
CM_ SG_ 568 VCU_AC_PasCabinAllowedPower "Passenge Cabin allowed For AC Power
乘客舱AC允许的功率";
CM_ SG_ 568 VCU_AC_Permittion "AC allowed
AC是否允许(AC使能)";
CM_ SG_ 568 VCU_AirPTC_Permittion "Air PTC allowed
风PTC是否允许(风PTC使能)";
CM_ SG_ 568 VCU_WPTC_Permittion "Water PTC allowed
水PTC是否允许(水PTC使能)";
CM_ SG_ 568 FPump_Enable "前水泵使能信号";
CM_ SG_ 568 FPump_Target_Speed "Front water pump target speed
前水泵目标转速（0-100%）";
CM_ SG_ 568 VCU_VehicleMaintenanceMode "Vehicle Maintenance Mode
车辆维修模式";
CM_ SG_ 568 VCU_CoolingFanSt "Cooling Fan Status
冷却风扇状态";
CM_ SG_ 568 VCU_StartInf "Veicle Start Information                                     车辆启动提示";
CM_ SG_ 568 VCU_ChaGearInf "Change gear Information                                    换挡提示";
CM_ SG_ 568 RPump_Enable "后水泵使能信号";
CM_ SG_ 568 RPump_Target_Speed "后水泵目标转速（0-100%）";
CM_ SG_ 570 VCU_FastchrgAllowedPower "Fast charge maximum allowable charging power
快充充电最大允许充电功率";
CM_ SG_ 570 VCU_SlowchrgAllowedPower "Slow charge maximum allowable charging power
慢充充电最大允许充电功率";
CM_ SG_ 570 VCU_Fastchrg_Permittion "is fast charging allowed
快充充电是否允许";
CM_ SG_ 570 VCU_Slowchrg_Permittion "Is slow charging allowed
慢充充电是否允许";
CM_ SG_ 570 VCU_AC_ChrgStatus "AC Charging Status
交流充电状态";
CM_ SG_ 570 VCU_OBC_Permittion "OBC allowed
OBC是否允许";
CM_ SG_ 570 VCU_EnergyRecoverySt "Energy Recovery Grade Status
能量回收等级状态";
CM_ SG_ 570 VCU_PwrFlowIndcr "Power flow indicator
能量流";
CM_ SG_ 570 VCU_WPTC_Permittion "Water PTC allowed
水PTC是否允许";
CM_ SG_ 570 VCU_AC_Permittion "AC allowed
AC是否允许";
CM_ SG_ 570 VCU_DC_ChrgStatus "DC Charging Status
直流充电状态";
CM_ SG_ 570 VCU_V2V_ChrgStatus "V2V Charging Status
对外放电状态";
CM_ SG_ 574 VCU_TbUnlockSts "VCU防盗解除状态（与TBOX之间的交互）";
CM_ SG_ 574 VCU_RCt_ModeSts "远控模式/状态";
CM_ SG_ 574 VCU_VehPowerMode "整车动力模式（国标）";
CM_ SG_ 574 VCU_Precharge_Satus "预充状态";
CM_ SG_ 574 VCU_request_subscribe_allow "预约充电允许";
CM_ SG_ 574 VCU_DCSystemDischrgAllowed "DC放电允许";
CM_ SG_ 574 VCU_EnduranceMileage "Mileage of continuous driving
续驶里程";
CM_ SG_ 574 VCU_DriveMotorNum "Number of drive motors (GB)
驱动电机个数（国标）";
CM_ SG_ 574 VCU_23Eh_RollingCounter "Rolling counter
循环计数器";
CM_ SG_ 574 VCU_MotorLockAllowed "Allow lock motor commands
允许锁电机命令";
CM_ SG_ 574 VCU_MotorLockSts "Lock Motor Status
锁电机状态";
CM_ SG_ 574 VCU_23Eh_CheckSUM "校检和 checksum = (Byte0+Byte1 …+ Byte6) XOR 0xFF";
CM_ SG_ 112 VCU_APA_FaildType "VCU to APA faild type
指示VCU反馈给APA的失败类型";
CM_ SG_ 112 VCU_BrkPedPos_Validity "Brake pedal position Validity
刹车踏板位置有效标识位(预留)";
CM_ SG_ 112 VCU_BrkSw_Sta "Brake switch signal status
刹车开关信号状态";
CM_ SG_ 112 VCU_EHB_VLC_Response "The signal indicates if VCU is responsing the EHB system request or not
指示VCU是否响应了EHB的扭矩请求";
CM_ SG_ 112 VCU_BrkSw_V "Brake switch signal Vaild
刹车开关信号有效标识位";
CM_ SG_ 112 VCU_Acc_Validity "Accelerator Eff. Position Validity
油门踏板位置信号有效标识位";
CM_ SG_ 112 VCU_BrkPed_Pos "Brake pedal position
刹车踏板位置（预留）";
CM_ SG_ 112 VCU_Acc_pedal_position "Throttle Pedal Input Depth
油门踏板输入深度";
CM_ SG_ 112 VCU_APA_ActiveEnableSts "Active enable status
激活使能状态";
CM_ SG_ 112 VCU_MotorTrqRegAllowed "Motor Torque Regeneration Allowed
电机扭矩回馈允许标志位";
CM_ SG_ 112 VCU_MotorTrqRegLimit "Motor Torque Regeneration Limitition
电机回馈扭矩限制值";
CM_ SG_ 112 VCU_Accel_Padel_Pos_Calc "calculated acceleration pedal position
计算的加速踏板位置";
CM_ SG_ 112 VCU_70h_RollingCounter "Rolling counter
循环计数器";
CM_ SG_ 112 VCU_Request_Response "The signal indicates if VCU is responsing the system request or not
指示VCU是否响应了ADAS的扭矩请求";
CM_ SG_ 112 VCU_Kickdown_AEB "request for kickdown (AEB)
驾驶员油门kickdown信号";
CM_ SG_ 112 VCU_Accel_Padel_Override "This signal indicates if acceleration pedal torque is larger than ACC torque request
指示驾驶员油门踏板超控（实际油门踏板扭矩超过ACC的扭矩请求值）";
CM_ SG_ 112 VCU_Available "Indicates if VCU is ready to response system request
指示VCU是否可以响应ADAS的请求";
CM_ SG_ 112 VCU_70h_CheckSUM "校检和 checksum = (Byte0+Byte1 …+ Byte6) XOR 0xFF'";
CM_ SG_ 913 VSP_State "VSP状态";
CM_ SG_ 913 VSP_VoiceSourceSelectFeedback "VSP声源切换反馈";
CM_ BO_ 644 "预约充电命令设置";
CM_ SG_ 644 TBOX_StartChgYear "预约开始时间年设置";
CM_ SG_ 644 TBOX_ReservationChgCommandSet "预约充电命令设置";
CM_ SG_ 644 TBOX_StartChgMonth "预约开始时间月设置";
CM_ SG_ 644 TBOX_StartChgDay "预约开始时间日设置";
CM_ SG_ 644 TBOX_StartChgHour "预约开始时间时设置";
CM_ SG_ 644 TBOX_ChrgMode "充电功率模式";
CM_ SG_ 644 TBOX_StartChgMinute "预约开始时间分设置";
CM_ SG_ 644 TBOX_ChrgPercentum "预约充电设定百分比";
CM_ SG_ 644 TBOX_StopChrgRQ "请求停止充电";
CM_ BO_ 645 "年月日时分秒";
CM_ SG_ 645 TBOX_Second "秒";
CM_ SG_ 645 TBOX_Minute "分";
CM_ SG_ 645 TBOX_Hour "小时";
CM_ SG_ 645 TBOX_Day "天";
CM_ SG_ 645 TBOX_Month "月";
CM_ SG_ 645 TBOX_Year "年，基础年份为2000年";
CM_ SG_ 645 TBOX_TimeCheckBit "时间校验位";
CM_ SG_ 645 TBOX_InvalidByte "无效字节";
CM_ SG_ 662 TBOX_VehiclePosition_longitude "车辆定位经度-度数";
CM_ SG_ 662 TBOX_VehiclePosition_latitude "车辆定位纬度-度数";
CM_ SG_ 664 Tbox_VehiclePosition_gradient "坡度";
CM_ SG_ 664 Tbox_VehiclePosition_altitude "海拔";
CM_ SG_ 664 Tbox_VehiclePosition_headDirection "车辆朝向(正北为0，正南为180)";
CM_ SG_ 664 Tbox_MMI_GPS_Country_Code "GPS enum code that can tell camera in which country ego car is running
GPS国家码";
CM_ SG_ 664 Tbox_MMI_FICM_Available "Indicate whether GPS national code signal is available
指示GPS国家码信号是否可用";
CM_ SG_ 614 AC_ACCM_RequestPower "空调压缩机需求功率";
CM_ SG_ 614 AC_PasCabinEnable "空调系统乘客舱使能";
CM_ SG_ 614 AC_APTC_RequestPower "空气PTC需求作功率";
CM_ SG_ 614 AC_APTC_WorkPower "空气PTC实际工作功率";
CM_ SG_ 614 AC_WPTC_RequestPower "水加热PTC需求功率";
CM_ SG_ 614 AC_WPTC_ActualPower "水加热PTC实际功率";
CM_ SG_ 614 AC_AirPTC_Enable "风PTC使能信号";
CM_ SG_ 614 AC_WPTC_RunStatus "水PTC状态";
CM_ SG_ 614 AC_ActualTotalPower "空调系统实际总功率";
CM_ SG_ 614 AC_ACCM_ActualPower "空调压缩机实际工作功率";
CM_ SG_ 624 AC_AutoMode "AC自动模式";
CM_ SG_ 624 AC_ActualBlowingMode "AC实际吹风模式";
CM_ SG_ 624 AC_ActualCirculationMode "AC实际内外循环模式";
CM_ SG_ 624 AC_DVDDisplayReq "大屏弹窗请求";
CM_ SG_ 624 AC_TempSetPoint "Temp set point
AC设定温度";
CM_ SG_ 624 AC_ActualAirQuantity "AC实际风量大小";
CM_ SG_ 624 AC_FwdDeforstSts "前除霜状态";
CM_ SG_ 624 AC_RearDeforstSts "后除霜状态(预留)";
CM_ SG_ 624 AC_CoolingStaus "AC制冷状态";
CM_ SG_ 624 AC_MaxCooingStaus "AC最大制冷状态";
CM_ SG_ 624 AC_OffStaus "AC关机状态";
CM_ SG_ 624 AC_PM25_Status "PM2.5 Status
PM2.5 状态";
CM_ SG_ 624 AC_RearViewMirroHeatStatus "Rear View Mirror Heat Status
后视镜加热状态反馈";
CM_ SG_ 624 AC_NegativeIconGenStus "AC Negative Icon genarator status
负离子发生器状态";
CM_ SG_ 607 AC_AmbientAirTemperature "环境温度";
CM_ SG_ 607 AC_AmbientAirTemperature_Corrected "校准后环境温度";
CM_ SG_ 607 AC_IncarTemperature "车内温度";
CM_ SG_ 607 AC_BatteryPumpState "电池回路水泵状态";
CM_ SG_ 607 AC_ACMode "空调模式";
CM_ SG_ 607 AC_BatteryPumpSpeed "电池回路水泵转速";
CM_ SG_ 607 AC_RearDeforstReq "Rear deforst request
后除霜请求";
CM_ SG_ 607 AC_AmbientAirTemperature_Validity "环境温度有效性";
CM_ SG_ 607 AC_Fan_SpeedReq "电子扇转速请求（热泵模式用）";
CM_ SG_ 607 AC_SeatHeatReq_right "副驾座椅加热请求（预留）";
CM_ SG_ 607 AC_SeatHeatReq_left "主驾座椅加热请求（预留）";
CM_ SG_ 607 AC_WorkingResponse_Status "AC反馈工作状态";
CM_ SG_ 607 AC_unload_Status "AC卸载";
CM_ SG_ 338 BCM_RFDoorSwitchSt "Right front door status signal
右前车门状态信号";
CM_ SG_ 338 BCM_LFDoorSwitchSt "Left Front door status signal
左前车门状态信号";
CM_ SG_ 338 BCM_PositionLampSt "Position lamp Status
位置灯状态";
CM_ SG_ 338 BCM_FrontFogligthSt "Front fog lamp Status
前雾灯状态";
CM_ SG_ 338 BCM_BackFogligthSt "Rear fog lamp status
后雾灯状态";
CM_ SG_ 338 BCM_HighBeamStatus "Remote Light Status
远光灯状态";
CM_ SG_ 338 BCM_LowBeamStatus "Near light status
近光灯状态";
CM_ SG_ 338 BCM_TrunkSt "Suitcase Door Status Signal
行李箱门状态信号";
CM_ SG_ 338 BCM_TurnLeverLoc "Turn Level Location
转向拨杆位置";
CM_ SG_ 338 BCM_RightligthFaultSt "Right Turn light malfunction
右转向灯故障";
CM_ SG_ 338 BCM_RightligthSt "Right steering State signal
右转向状态信号";
CM_ SG_ 338 BCM_LetfligthFaultSt "Left Turn lamp fault
左转向灯故障";
CM_ SG_ 338 BCM_LetfligthSt "Left steering State signal
左转向状态信号";
CM_ SG_ 338 BCM_LRDoorSwitchSt "Left rear door status signal
左后车门状态信号";
CM_ SG_ 338 BCM_RRDoorSwitchSt "Right rear door status signal
右后车门状态信号";
CM_ SG_ 338 BCM_CentralLockSt "Switch state of central control lock
中控锁开关状态";
CM_ SG_ 338 BCM_Reverse_Light "status of reverse lights
倒车灯状态";
CM_ SG_ 338 BCM_Mainbeam_Available "indicates if Mainbeam is available
指示远光灯是否可用";
CM_ SG_ 338 Bcm_OutSwitchPressCmd "Back door control command (lateral button)
后背门控制命令（外侧按键）";
CM_ SG_ 338 BCM_HazardwarnLampSt "Hazard Alarm Lamp Status signal
危险报警灯状态信号";
CM_ SG_ 338 BCM_PassSeatbeltBucklestatus "Passenger seat belt buckle status
副驾驶安全带状态";
CM_ SG_ 338 BCM_DrvSeatbeltBucklestatus "Driver seat belt buckle status
驾驶员安全带状态";
CM_ SG_ 338 BCM_FrontCoverSt "Front Hatch Status Signal
前舱盖状态信号";
CM_ SG_ 338 BCM_Humidity "Vehicle humidity
车内湿度";
CM_ SG_ 338 BCM_Auto_LightSwitch "Whether the far and near light switch is in 'Auto' gear
远近光灯开关是否处于AUTO挡";
CM_ SG_ 338 BCM_Brake_Light "status of brake lights
刹车灯状态";
CM_ SG_ 338 BCM_RearViewMirrorAutoFoldFucFeedback "后视镜自动折叠功能反馈";
CM_ SG_ 338 BCM_Rain_Sensor "indicate rain level
雨量等级(AUTO挡时，雨量传感器请求的雨刮状态)";
CM_ SG_ 338 BCM_DrvSeatbeltBucklevalidity "Driver seat belt buckle validity
驾驶员安全带状态信号有效性";
CM_ SG_ 338 BCM_PassSeatbeltBucklevalidity "Passenger seat belt buckle validity
副驾驶安全带状态信号有效性";
CM_ SG_ 338 BCM_PowerMode "System power supply
That is: ignition status
系统电源
即：点火状态";
CM_ SG_ 338 BCM_RearViewMirror "RearViewMirror Status
后视镜状态";
CM_ SG_ 338 BCM_ChargeCoverLockStatus "Charge Cover Lock Status
充电口盖锁状态";
CM_ SG_ 338 BCM_RearDeforstSts "Rear deforst status
后除霜状态";
CM_ SG_ 338 BCM_BkSeat_1_beltBucklevalidity "Back seat 1 belt buckle validity
后排座椅安全带1状态信号有效性";
CM_ SG_ 338 BCM_BkSeat_1_beltBucklestatus "Back seat 1 belt buckle status
后排1安全带状态";
CM_ SG_ 338 BCM_BkSeat_2_beltBucklevalidity "Back seat 2 belt buckle validity
后排座椅安全带2状态信号有效性";
CM_ SG_ 338 BCM_BkSeat_2_beltBucklestatus "Back seat 2 belt buckle status
后排2安全带状态";
CM_ SG_ 338 BCM_BkSeat_3_beltBucklevalidity "Back seat 3 belt buckle validity
后排座椅安全带1状态信号有效性";
CM_ SG_ 338 BCM_BkSeat_3_beltBucklestatus "Back seat 3 belt buckle status
后排1安全带状态";
CM_ SG_ 338 BCM_RainAutoClsWindowFuncStus "雨天自动关闭四门车窗功能状态";
CM_ SG_ 338 BCM_LockVehicleWarmingTipStus "锁车提醒方式状态";
CM_ SG_ 338 BCM_CourtesyLampStus "迎宾灯状态";
CM_ SG_ 338 BCM_VehicleCourtesyLampFuncStus "车辆迎宾灯功能状态";
CM_ SG_ 338 BCM_AccLampSetStus "伴我回家灯设置状态";
CM_ SG_ 588 PEPS_KeyInCarWarning "Failed lock warning for the key is in the car 
钥匙遗忘在车内 驾驶员提醒（IP:智能钥匙遗忘车内）";
CM_ SG_ 588 ReminderPutInP_Nposition_OFF "Display the reminder of put in P/N position or neutral when OFF.
请切换至P档提醒（IP:请切换至P档下电）";
CM_ SG_ 588 ReminderPutInP_Nposition_Lock "Display the reminder of put in P/N position or neutral when lock.
请切换至P档提醒（IP:请切换至P档）";
CM_ SG_ 588 PEPS_KeyNotInWarning "Display there is no valid key inside.
钥匙不在车内提醒（IP:智能钥匙不在车内）";
CM_ SG_ 588 BCM_FrontWiperSt "Front Wiper Switch Status
前雨刮开关状态";
CM_ SG_ 588 PEPS_PutKeyInIMMOSocket "Put Key In IMMO socket
请将遥控钥匙放置将智能钥匙放置于钥匙槽来执行IMMO启动提醒（IP:将智能钥匙放置于钥匙槽）";
CM_ SG_ 588 PEPS_PowerRelayFault "Power Relay fault
电源故障（任何一个继电器坏掉都报故障）（IP:电源故障）";
CM_ SG_ 588 PEPS_RemoteLowVoltage "Display the key battery low status
遥控钥匙电压低提醒（IP:智能钥匙电量低）";
CM_ SG_ 588 PEPS_ESCLFault "ESCL fault（预留）
ESCL故障（IP:ESCL故障）";
CM_ SG_ 588 PEPS_ESCLUnlockFailed "ESCL unlock failed（预留）
ESCL解锁失败（IP:请转动方向盘）";
CM_ SG_ 588 FLWS_POS_VIT_FL "Left Front window position
左前车窗位置";
CM_ SG_ 588 FRWS_POS_VIT_FL "Right front window position
右前车窗位置";
CM_ SG_ 588 RLWS_POS_VIT_FL "Left rear Window position
左后车窗位置";
CM_ SG_ 588 RRWS_POS_VIT_FL "Right rear Window position
右后车窗位置";
CM_ SG_ 588 BCM_OpenDoorWarning "开门语音提醒（仅针对远控Ready模式下使用）";
CM_ SG_ 589 PEPS_LastLockType "Last lock type
上次锁类型";
CM_ SG_ 589 PEPS_CurrentOperateKeyIndex "current operation key index
当前操作键索引";
CM_ SG_ 589 BCM_LFDoorLockStatus "Left front door door lock status
左前门门锁状态";
CM_ SG_ 589 BCM_TrunkDoorLockSts "Backup Box door lock status
后备箱门锁状态";
CM_ SG_ 589 PEPS_ESCL_SteeringLockStatus "current ESCL lock status
当前 escl 锁定状态";
CM_ SG_ 589 BCM_RFDoorLockStatus "Right front door door lock status
右前门门锁状态";
CM_ SG_ 589 BCM_LRDoorLockStatus "Left Backdoor door lock status
左后门门锁状态";
CM_ SG_ 589 PEPS_DrvDoorRequestSwitchSt "Left front door request switch status
左前门请求开关状态";
CM_ SG_ 589 PEPS_StartStopButtonSt "Current Boot switch status
当前启动开关状态";
CM_ SG_ 589 PEPS_TrunkRequestSwitchSt "Backup door\/Suitcase Request switch status
后备门/行李箱请求开关状态";
CM_ SG_ 589 PEPS_VDrvDoorRequestSwitchSt "Right front door request switch status (reserved)
右前门请求开关状态（预留）";
CM_ SG_ 589 BCM_RRDoorLockStatus "Right Backdoor door lock status右后门门锁状态";
CM_ SG_ 589 BCM_RLS_RQ_WiperSPD "The Sensor requested wiper speed 雨量传感器请求的雨刮速度.";
CM_ SG_ 589 BCM_RLS_Fault "Rain/Light sensor fault status
雨量光照传感器故障";
CM_ SG_ 589 BCM_RLC_FWLight "Forward light前向光";
CM_ SG_ 589 BCM_RLC_Ambient_Light "Ambient light上方光";
CM_ SG_ 610 BCM_FL_TirePrs "Left Front tire pressure pressure
左前轮胎压压力";
CM_ SG_ 610 BCM_FR_TirePrs "Right Front tire pressure pressure
右前轮胎压压力";
CM_ SG_ 610 BCM_RL_TirePrs "Left rear tire pressure pressure
左后轮胎压压力";
CM_ SG_ 610 BCM_RR_TirePrs "Right rear tire pressure pressure
右后轮胎压压力";
CM_ SG_ 610 BCM_RR_TirePrsSt "Right rear tire pressure state
右后轮胎压状态";
CM_ SG_ 610 BCM_RL_TirePrsSt "Left rear tire pressure state
左后轮胎压状态";
CM_ SG_ 610 BCM_FR_TirePrsSt "Right front tire pressure state右前轮胎右前轮胎压状态";
CM_ SG_ 610 BCM_FL_TirePrsSt "Left Front tire pressure state
左前轮胎压状态";
CM_ SG_ 612 BCM_FL_TireTpt "Left Front tire temperature
左前轮胎温";
CM_ SG_ 612 BCM_FR_TireTpt "Right front tire temperature
右前轮胎温";
CM_ SG_ 612 BCM_RL_TireTpt "Left rear tire temperature
左后轮胎温";
CM_ SG_ 612 BCM_RR_TireTpt "Right rear tire temperature
右后轮胎温";
CM_ SG_ 612 BCM_RR_TireTptSt "Right rear wheel tire temperature state
右后轮轮胎温状态";
CM_ SG_ 612 BCM_RL_TireTptSt "Left rear wheel tire temperature state
左后轮轮胎温状态";
CM_ SG_ 612 BCM_FR_TireTptSt "Right front wheel tire temperature state
右前轮轮胎温状态";
CM_ SG_ 612 BCM_FL_TireTptSt "Left front wheel tire temperature state
左前轮轮胎温状态";
CM_ SG_ 613 BCM_RR_TireLose "Right rear wheel sensor RF signal failure
右后轮传感器RF信号故障";
CM_ SG_ 613 BCM_RL_TireLose "Left rear wheel sensor RF signal failure
左后轮传感器RF信号故障";
CM_ SG_ 613 BCM_FR_TireLose "Right front wheel sensor RF signal failure
右前轮传感器RF信号故障";
CM_ SG_ 613 BCM_FL_TireLose "Left front wheel sensor RF signal failure
左前轮传感器RF信号故障";
CM_ SG_ 613 BCM_RR_TireLowVol "Right rear wheel sensor low voltage tips
右后轮传感器低压提示";
CM_ SG_ 613 BCM_RL_TireLowVol "Left rear wheel sensor low voltage tips
左后轮传感器低压提示";
CM_ SG_ 613 BCM_FR_TireLowVol "Right front wheel sensor low voltage tips
右前轮传感器低压提示";
CM_ SG_ 613 BCM_FL_TireLowVol "Left front wheel sensor low voltage tips
左前轮传感器低压提示";
CM_ SG_ 613 BCM_RR_TestSt "TPMS right rear wheel test status
TPMS右后轮测试状态";
CM_ SG_ 613 BCM_RL_TestSt "TPMS left rear wheel test status
TPMS左后轮测试状态";
CM_ SG_ 613 BCM_FR_TestSt "TPMS right front wheel test status
TPMS右前轮测试状态";
CM_ SG_ 613 BCM_FL_TestSt "TPMS left front wheel test status
TPMS左前轮测试状态";
CM_ SG_ 613 BCM_BatVol_ErrFlag "TPMS Supply voltage anomaly
TPMS供电电压异常";
CM_ SG_ 613 BCM_TPMS_TestSt "TPMS Test Status
TPMS 测试状态";
CM_ SG_ 613 BCM_RR_Quikleakage "Right rear wheel sensor fast leak alarm prompt
右后轮传感器快速漏气报警提示";
CM_ SG_ 613 BCM_RL_Quikleakage "Left rear wheel sensor fast leak alarm prompt
左后轮传感器快速漏气报警提示";
CM_ SG_ 613 BCM_FR_Quikleakage "Right front wheel sensor fast leak alarm Tips
右前轮传感器快速漏气报警提示";
CM_ SG_ 613 BCM_FL_Quikleakage "Left front wheel sensor fast leak alarm Tips
左前轮传感器快速漏气报警提示";
CM_ BO_ 665 "主驾座椅电机状态反馈";
CM_ SG_ 665 DSM_D_SlideDirection "主驾座椅前后调节状态";
CM_ SG_ 665 DSM_D_FrontLiftDirection "主驾座椅前升降调节状态";
CM_ SG_ 665 DSM_D_ReclinerDirection "主驾座椅靠背调角调节状态";
CM_ SG_ 665 DSM_D_AllLiftDirection "主驾座椅全升降调节状态";
CM_ SG_ 665 DSM_DrvSeatHandyEntryExitSetStus "便利进出设置状态";
CM_ SG_ 665 DSM_D_SlidePosPercentFinal "主驾座椅前后位置";
CM_ SG_ 665 DSM_D_FrontLiftPosPercentFinal "主驾座椅前升位置";
CM_ SG_ 665 DSM_D_ReclinerPosPercentFinal "主驾座椅靠背位置百分比";
CM_ SG_ 665 DSM_D_AllLiftPosPercentFinal "主驾座椅全升降位置百分比";
CM_ BO_ 667 "副驾座椅电机状态反馈";
CM_ SG_ 667 DSM_P_SlideDirection "副驾座椅前后调节状态";
CM_ SG_ 667 DSM_P_FrontLiftDirection "副驾座椅前升降调节状态";
CM_ SG_ 667 DSM_P_ReclinerDirection "副驾座椅靠背调角调节状态";
CM_ SG_ 667 DSM_P_AllLiftDirection "副驾座椅全升降调节状态";
CM_ SG_ 667 DSM_P_SlidePosPercentFinal "副驾座椅前后位置";
CM_ SG_ 667 DSM_P_FrontLiftPosPercentFinal "副驾座椅前升位置";
CM_ SG_ 667 DSM_P_ReclinerPosPercentFinal "副驾座椅靠背位置百分比";
CM_ SG_ 667 DSM_P_AllLiftPosPercentFinal "副驾座椅全升降位置百分比";
CM_ BO_ 659 "座椅加热与通风状态反馈";
CM_ SG_ 659 FSCM_DrvSeatHeat_Sts "Driver seat heat degree status
驾驶员座椅加热等级状态";
CM_ SG_ 659 FSCM_DrvSeatVentilation_Sts "Driver seat ventilation degree status
驾驶员座椅通风等级状态";
CM_ SG_ 659 FSCM_PassSeatHeat_Sts "Pass Driver seat heat degree status
驾驶员座椅加热等级状态";
CM_ SG_ 659 FSCM_PassSeatVentilation_Sts "Pass Driver seat ventilation degree status
驾驶员座椅通风等级状态";
CM_ BO_ 856 "手机无线充电器CWC发出信号";
CM_ SG_ 856 CWC_Status_Charge "手机充电状态";
CM_ SG_ 856 CWC_Info_matter "无线充电器异物检测";
CM_ SG_ 856 CWC_Info_phoneforgotten "手机遗忘提醒";
CM_ SG_ 856 CWC_Over_Temp "充电器过温";
CM_ SG_ 856 CWC_Over_Current "充电器过流";
CM_ SG_ 856 CWC_Over_Voltage "充电器过压";
BA_DEF_ BO_  "NmMessage" ENUM "No","Yes";
BA_DEF_ BO_  "DiagState" ENUM  "No","Yes";
BA_DEF_ BO_  "DiagResponse" ENUM  "No","Yes";
BA_DEF_ BO_  "GenMsgSendType" ENUM  "NoSendType","Cycle","Event","IfActive","CE","CA";
BA_DEF_ BO_  "GenMsgCycleTime" INT 0 0;
BA_DEF_ SG_  "GenSigSendType" ENUM  "NoSendType","Cycle","OnWrite","OnWriteWithRepetition","OnChange","OnChangeWithRepetition","IfActive","IfActiveWithRepetition";
BA_DEF_ SG_  "GenSigStartValue" INT 0 0;
BA_DEF_ SG_  "GenSigInvalidValue" STRING;
BA_DEF_ BO_  "GenMsgCycleTimeFast" INT 0 0;
BA_DEF_ BO_  "GenMsgNrOfRepetition" INT 0 0;
BA_DEF_ BO_  "GenMsgDelayTime" INT 0 0;

BA_DEF_DEF_  "NmMessage" "No";
BA_DEF_DEF_  "DiagState" "No";
BA_DEF_DEF_  "DiagResponse" "No";
BA_DEF_DEF_  "GenMsgSendType" "Cycle";
BA_DEF_DEF_  "GenMsgCycleTime" 0;
BA_DEF_DEF_  "GenSigSendType" "Cycle";
BA_DEF_DEF_  "GenSigStartValue" 0;
BA_DEF_DEF_  "GenSigInvalidValue" "";
BA_DEF_DEF_  "GenMsgCycleTimeFast" 0;
BA_DEF_DEF_  "GenMsgNrOfRepetition" 0;
BA_DEF_DEF_  "GenMsgDelayTime" 0;
BA_ "GenMsgCycleTime" BO_ 530 100 ;
BA_ "GenSigInvalidValue" SG_ 530 BMS_Sys_MinCellT "0xFF";
BA_ "GenSigInvalidValue" SG_ 530 BMS_Sys_MaxCellT "0xFF";
BA_ "GenSigInvalidValue" SG_ 530 BMS_Sys_MinCellT_No "0xFF";
BA_ "GenSigInvalidValue" SG_ 530 BMS_Sys_MaxCellT_No "0xFF";
BA_ "GenSigInvalidValue" SG_ 530 BMS_FastChrgTemp "0xFF";
BA_ "GenMsgCycleTime" BO_ 534 100 ;
BA_ "GenSigInvalidValue" SG_ 534 BMS_PosInsulationResistance "0xFFFF";
BA_ "GenSigInvalidValue" SG_ 534 BMS_NegInsulationResistance "0xFFFF";
BA_ "GenSigInvalidValue" SG_ 534 BMS_Sys_SOC "0xFF";
BA_ "GenSigInvalidValue" SG_ 534 BMS_Sys_SOH "0xFF";
BA_ "GenMsgCycleTime" BO_ 340 50 ;
BA_ "GenSigInvalidValue" SG_ 340 RCTA_warm_status_left "0x3";
BA_ "GenSigInvalidValue" SG_ 340 BSDLCA_warm_status_left "0x3";
BA_ "GenSigInvalidValue" SG_ 340 BSDDOW_warm_status_left "0x3";
BA_ "GenSigInvalidValue" SG_ 340 BSD_EnableStatus "0x0";
BA_ "GenMsgCycleTime" BO_ 344 50 ;
BA_ "GenSigInvalidValue" SG_ 344 RCTA_warm_status_right "0x3";
BA_ "GenSigInvalidValue" SG_ 344 BSDLCA_warm_status_right "0x3";
BA_ "GenSigInvalidValue" SG_ 344 BSDDOW_warm_status_right "0x3";
BA_ "GenMsgCycleTime" BO_ 148 10 ;
BA_ "GenSigInvalidValue" SG_ 148 EHB_BrkPelPosActVD "0x0";
BA_ "GenSigInvalidValue" SG_ 148 EHB_RegTorqReqVD "0x0";
BA_ "GenSigInvalidValue" SG_ 148 EHB_RegTorqReqWhl "0x1FFF";
BA_ "GenMsgCycleTime" BO_ 328 20 ;
BA_ "GenSigInvalidValue" SG_ 328 EPB_SwitchSta_L "0x3";
BA_ "GenMsgCycleTime" BO_ 336 20 ;
BA_ "GenSigInvalidValue" SG_ 336 EPB_SwitchSta_R "0x3";
BA_ "GenMsgCycleTime" BO_ 274 20 ;
BA_ "GenSigInvalidValue" SG_ 274 EPS_SteeringWheelAngVD "0x0";
BA_ "GenSigInvalidValue" SG_ 274 EPS_TorsionBarTorqueValid "0x0";
BA_ "GenSigInvalidValue" SG_ 274 EPS_TorsionBarTorque "0x3FF";
BA_ "GenSigInvalidValue" SG_ 274 EPS_SteeringWheelAng "0x3FFF";
BA_ "GenSigInvalidValue" SG_ 274 EPS_SteerWheelRotSpd "0xFF";
BA_ "GenSigInvalidValue" SG_ 274 MMI_EpsModeFeedback "0x0";
BA_ "GenSigInvalidValue" SG_ 274 EPS_SteerWheelRotSpdVD "0x0";
BA_ "GenMsgCycleTime" BO_ 144 10 ;
BA_ "GenSigInvalidValue" SG_ 144 ESC_EPBRequest "0x3";
BA_ "GenSigInvalidValue" SG_ 144 ESC_BrkPrs "0xFFF";
BA_ "GenMsgCycleTime" BO_ 146 10 ;
BA_ "GenSigInvalidValue" SG_ 146 ESC_VehSpd "0x7FFF";
BA_ "GenSigInvalidValue" SG_ 146 ESC_WhlFLSpd "0xFFFF";
BA_ "GenSigInvalidValue" SG_ 146 ESC_WhlFRSpd "0xFFFF";
BA_ "GenSigInvalidValue" SG_ 146 ESC_WhlSpdFRVd "0x0";
BA_ "GenSigInvalidValue" SG_ 146 ESC_WhlSpdFLVd "0x0";
BA_ "GenSigInvalidValue" SG_ 146 ESC_VehSpdVd "0x0";
BA_ "GenMsgCycleTime" BO_ 342 20 ;
BA_ "GenSigInvalidValue" SG_ 342 AmphereLampSta_IntePerSW "0x0";
BA_ "GenSigInvalidValue" SG_ 342 AmphereLampMode "0x0";
BA_ "GenSigInvalidValue" SG_ 342 AmphereLampUserDefModeStatus "0x0";
BA_ "GenSigInvalidValue" SG_ 342 AmphereLampSta_SW "0x0";
BA_ "GenSigStartValue" SG_ 342 AmphereLampBrtnsVal 255;
BA_ "GenSigInvalidValue" SG_ 342 AmphereLampBrtnsVal "0xFF";
BA_ "GenMsgCycleTime" BO_ 594 100 ;
BA_ "GenSigInvalidValue" SG_ 594 FMCU_HV_Interlock_Falult "0x0";
BA_ "GenSigInvalidValue" SG_ 594 FMCU_Uncap_Falult "0x0";
BA_ "GenMsgCycleTime" BO_ 130 10 ;
BA_ "GenSigInvalidValue" SG_ 130 MCU_F_UdcCurr "0x3FF";
BA_ "GenMsgCycleTime" BO_ 132 100 ;
BA_ "GenMsgCycleTime" BO_ 580 100 ;
BA_ "GenMsgCycleTime" BO_ 608 100 ;
BA_ "GenSigInvalidValue" SG_ 608 RMCU_HV_Interlock_Falult "0x0";
BA_ "GenSigInvalidValue" SG_ 608 RMCU_Uncap_Falult "0x0";
BA_ "GenMsgCycleTime" BO_ 178 10 ;
BA_ "GenSigInvalidValue" SG_ 178 MCU_R_UdcCurr "0x3FF";
BA_ "GenMsgCycleTime" BO_ 772 500 ;
BA_ "GenSigInvalidValue" SG_ 772 OBC_CP_DutyCycleValue "0xFF";
BA_ "GenMsgCycleTime" BO_ 770 500 ;
BA_ "GenSigInvalidValue" SG_ 770 DCDC_Voltage_Input "0xFFFF";
BA_ "GenSigInvalidValue" SG_ 770 DCDC_Current_Input "0x3FF";
BA_ "GenMsgCycleTime" BO_ 776 500 ;
BA_ "GenMsgCycleTime" BO_ 372 50 ;
BA_ "GenSigInvalidValue" SG_ 372 VCU_GearPosition "0x0";
BA_ "GenSigInvalidValue" SG_ 372 VCU_PrechrgAnodeRelay_Status "0x0";
BA_ "GenSigInvalidValue" SG_ 372 VCU_DischrgAnodeRelay_Status "0x0";
BA_ "GenSigInvalidValue" SG_ 372 VCU_DischrgCathodeRelay_status "0x0";
BA_ "GenSigInvalidValue" SG_ 372 VCU_VehSysStatus "0x0";
BA_ "GenSigInvalidValue" SG_ 372 VCU_UnlockSts "0x0";
BA_ "GenMsgCycleTime" BO_ 568 100 ;
BA_ "GenSigInvalidValue" SG_ 568 VCU_AllowedMaxDisChrgPowerOfAC "0xFF";
BA_ "GenSigInvalidValue" SG_ 568 VCU_AC_PasCabinAllowedPower "0xFF";
BA_ "GenSigStartValue" SG_ 568 VCU_AC_Permittion 1;
BA_ "GenSigStartValue" SG_ 568 VCU_AirPTC_Permittion 1;
BA_ "GenSigStartValue" SG_ 568 VCU_WPTC_Permittion 1;
BA_ "GenSigInvalidValue" SG_ 568 FPump_Target_Speed "0xFF";
BA_ "GenSigInvalidValue" SG_ 568 VCU_CoolingFanSt "0x0";
BA_ "GenSigInvalidValue" SG_ 568 RPump_Target_Speed "0xFF";
BA_ "GenMsgCycleTime" BO_ 570 100 ;
BA_ "GenSigInvalidValue" SG_ 570 VCU_FastchrgAllowedPower "0x3FF";
BA_ "GenSigInvalidValue" SG_ 570 VCU_SlowchrgAllowedPower "0xFF";
BA_ "GenSigInvalidValue" SG_ 570 VCU_Fastchrg_Permittion "0x0";
BA_ "GenSigInvalidValue" SG_ 570 VCU_Slowchrg_Permittion "0x0";
BA_ "GenSigStartValue" SG_ 570 VCU_OBC_Permittion 1;
BA_ "GenSigInvalidValue" SG_ 570 VCU_EnergyRecoverySt "0x7";
BA_ "GenSigStartValue" SG_ 570 VCU_WPTC_Permittion 1;
BA_ "GenSigStartValue" SG_ 570 VCU_AC_Permittion 1;
BA_ "GenMsgCycleTime" BO_ 574 100 ;
BA_ "GenSigInvalidValue" SG_ 574 VCU_TbUnlockSts "0x0";
BA_ "GenSigInvalidValue" SG_ 574 VCU_EnduranceMileage "0xFFFF";
BA_ "GenSigStartValue" SG_ 574 VCU_DriveMotorNum 1;
BA_ "GenSigInvalidValue" SG_ 574 VCU_DriveMotorNum "0xFF";
BA_ "GenMsgCycleTime" BO_ 112 10 ;
BA_ "GenSigInvalidValue" SG_ 112 VCU_APA_FaildType "0x7";
BA_ "GenSigInvalidValue" SG_ 112 VCU_Acc_Validity "0x1";
BA_ "GenSigInvalidValue" SG_ 112 VCU_BrkPed_Pos "0xFF";
BA_ "GenSigInvalidValue" SG_ 112 VCU_Acc_pedal_position "0xFF";
BA_ "GenSigInvalidValue" SG_ 112 VCU_MotorTrqRegLimit "0x1FFF";
BA_ "GenSigInvalidValue" SG_ 112 VCU_Accel_Padel_Pos_Calc "0xFF";
BA_ "GenSigStartValue" SG_ 112 VCU_Available 1;
BA_ "GenMsgCycleTime" BO_ 913 500 ;
BA_ "GenMsgSendType" BO_ 644 2;
BA_ "GenMsgCycleTimeFast" BO_ 644 100 ;
BA_ "GenMsgNrOfRepetition" BO_ 644 3 ;
BA_ "GenSigSendType" SG_ 644 TBOX_StartChgYear 3;
BA_ "GenSigInvalidValue" SG_ 644 TBOX_StartChgYear "0x3F";
BA_ "GenSigSendType" SG_ 644 TBOX_ReservationChgCommandSet 3;
BA_ "GenSigStartValue" SG_ 644 TBOX_ReservationChgCommandSet 3;
BA_ "GenSigInvalidValue" SG_ 644 TBOX_ReservationChgCommandSet "0x3";
BA_ "GenSigSendType" SG_ 644 TBOX_StartChgMonth 3;
BA_ "GenSigStartValue" SG_ 644 TBOX_StartChgMonth 15;
BA_ "GenSigInvalidValue" SG_ 644 TBOX_StartChgMonth "0xF";
BA_ "GenSigSendType" SG_ 644 TBOX_StartChgDay 3;
BA_ "GenSigInvalidValue" SG_ 644 TBOX_StartChgDay "0x0";
BA_ "GenSigSendType" SG_ 644 TBOX_StartChgHour 3;
BA_ "GenSigInvalidValue" SG_ 644 TBOX_StartChgHour "0x1F";
BA_ "GenSigSendType" SG_ 644 TBOX_ChrgMode 3;
BA_ "GenSigSendType" SG_ 644 TBOX_StartChgMinute 3;
BA_ "GenSigStartValue" SG_ 644 TBOX_StartChgMinute 63;
BA_ "GenSigInvalidValue" SG_ 644 TBOX_StartChgMinute "0x3F";
BA_ "GenSigSendType" SG_ 644 TBOX_ChrgPercentum 3;
BA_ "GenSigSendType" SG_ 644 TBOX_StopChrgRQ 3;
BA_ "GenMsgSendType" BO_ 645 2;
BA_ "GenMsgCycleTimeFast" BO_ 645 100 ;
BA_ "GenMsgNrOfRepetition" BO_ 645 3 ;
BA_ "GenSigSendType" SG_ 645 TBOX_Second 3;
BA_ "GenSigSendType" SG_ 645 TBOX_Minute 3;
BA_ "GenSigSendType" SG_ 645 TBOX_Hour 3;
BA_ "GenSigSendType" SG_ 645 TBOX_Day 3;
BA_ "GenSigStartValue" SG_ 645 TBOX_Day 1;
BA_ "GenSigSendType" SG_ 645 TBOX_Month 3;
BA_ "GenSigStartValue" SG_ 645 TBOX_Month 1;
BA_ "GenSigSendType" SG_ 645 TBOX_Year 3;
BA_ "GenSigInvalidValue" SG_ 645 TBOX_Year "0x3F";
BA_ "GenSigSendType" SG_ 645 TBOX_TimeCheckBit 3;
BA_ "GenSigInvalidValue" SG_ 645 TBOX_TimeCheckBit "0x1";
BA_ "GenSigSendType" SG_ 645 TBOX_InvalidByte 3;
BA_ "GenSigInvalidValue" SG_ 645 TBOX_InvalidByte "0xFF";
BA_ "GenMsgCycleTime" BO_ 662 100 ;
BA_ "GenMsgCycleTime" BO_ 664 100 ;
BA_ "GenSigInvalidValue" SG_ 664 Tbox_MMI_GPS_Country_Code "0x0";
BA_ "GenSigStartValue" SG_ 664 Tbox_MMI_FICM_Available 1;
BA_ "NmMessage" BO_ 1028 1 ;
BA_ "GenMsgSendType" BO_ 1028 2;
BA_ "GenSigSendType" SG_ 1028 AC_NM_Message0 2;
BA_ "GenSigSendType" SG_ 1028 AC_NM_Message1 2;
BA_ "GenSigSendType" SG_ 1028 AC_NM_Message2 2;
BA_ "GenSigSendType" SG_ 1028 AC_NM_Message3 2;
BA_ "GenSigSendType" SG_ 1028 AC_NM_Message4 2;
BA_ "GenSigSendType" SG_ 1028 AC_NM_Message5 2;
BA_ "GenSigSendType" SG_ 1028 AC_NM_Message6 2;
BA_ "GenSigSendType" SG_ 1028 AC_NM_Message7 2;
BA_ "GenMsgCycleTime" BO_ 614 100 ;
BA_ "GenSigInvalidValue" SG_ 614 AC_ACCM_RequestPower "0x7F";
BA_ "GenSigStartValue" SG_ 614 AC_PasCabinEnable 1;
BA_ "GenSigInvalidValue" SG_ 614 AC_APTC_RequestPower "0xFF";
BA_ "GenSigInvalidValue" SG_ 614 AC_APTC_WorkPower "0xFF";
BA_ "GenSigInvalidValue" SG_ 614 AC_WPTC_RequestPower "0xFF";
BA_ "GenSigInvalidValue" SG_ 614 AC_WPTC_ActualPower "0xFF";
BA_ "GenSigInvalidValue" SG_ 614 AC_ActualTotalPower "0x1FF";
BA_ "GenSigInvalidValue" SG_ 614 AC_ACCM_ActualPower "0x7F";
BA_ "GenMsgCycleTime" BO_ 624 100 ;
BA_ "GenSigInvalidValue" SG_ 624 AC_AutoMode "0x0";
BA_ "GenSigInvalidValue" SG_ 624 AC_ActualBlowingMode "0x0";
BA_ "GenSigInvalidValue" SG_ 624 AC_ActualCirculationMode "0x0";
BA_ "GenSigStartValue" SG_ 624 AC_TempSetPoint 31;
BA_ "GenSigInvalidValue" SG_ 624 AC_TempSetPoint "0x1F";
BA_ "GenSigInvalidValue" SG_ 624 AC_ActualAirQuantity "0x0";
BA_ "GenSigInvalidValue" SG_ 624 AC_CoolingStaus "0x0";
BA_ "GenSigInvalidValue" SG_ 624 AC_MaxCooingStaus "0x0";
BA_ "GenSigInvalidValue" SG_ 624 AC_OffStaus "0x0";
BA_ "GenSigInvalidValue" SG_ 624 AC_PM25_Status "0x0";
BA_ "GenSigInvalidValue" SG_ 624 AC_RearViewMirroHeatStatus "0x0";
BA_ "GenSigInvalidValue" SG_ 624 AC_NegativeIconGenStus "0x0";
BA_ "GenMsgCycleTime" BO_ 607 100 ;
BA_ "GenSigInvalidValue" SG_ 607 AC_BatteryPumpSpeed "0xff";
BA_ "GenSigInvalidValue" SG_ 607 AC_AmbientAirTemperature_Validity "0x1";
BA_ "GenSigInvalidValue" SG_ 607 AC_WorkingResponse_Status "0x0";
BA_ "GenSigInvalidValue" SG_ 607 AC_unload_Status "0x0";
BA_ "NmMessage" BO_ 1024 1 ;
BA_ "GenMsgSendType" BO_ 1024 2;
BA_ "GenSigSendType" SG_ 1024 BCM_NM_Message0 2;
BA_ "GenSigSendType" SG_ 1024 BCM_NM_Message1 2;
BA_ "GenSigSendType" SG_ 1024 BCM_NM_Message2 2;
BA_ "GenSigSendType" SG_ 1024 BCM_NM_Message3 2;
BA_ "GenSigSendType" SG_ 1024 BCM_NM_Message4 2;
BA_ "GenSigSendType" SG_ 1024 BCM_NM_Message5 2;
BA_ "GenSigSendType" SG_ 1024 BCM_NM_Message6 2;
BA_ "GenSigSendType" SG_ 1024 BCM_NM_Message7 2;
BA_ "GenMsgCycleTime" BO_ 338 50 ;
BA_ "GenSigInvalidValue" SG_ 338 BCM_PowerMode "0x0";
BA_ "GenSigInvalidValue" SG_ 338 BCM_RearViewMirror "0x0";
BA_ "GenSigInvalidValue" SG_ 338 BCM_BkSeat_1_beltBucklevalidity "0x0";
BA_ "GenSigInvalidValue" SG_ 338 BCM_BkSeat_2_beltBucklevalidity "0x0";
BA_ "GenSigInvalidValue" SG_ 338 BCM_BkSeat_3_beltBucklevalidity "0x0";
BA_ "GenSigInvalidValue" SG_ 338 BCM_RainAutoClsWindowFuncStus "0";
BA_ "GenSigInvalidValue" SG_ 338 BCM_LockVehicleWarmingTipStus "0";
BA_ "GenSigInvalidValue" SG_ 338 BCM_VehicleCourtesyLampFuncStus "0";
BA_ "GenSigInvalidValue" SG_ 338 BCM_AccLampSetStus "0";
BA_ "GenMsgCycleTime" BO_ 588 100 ;
BA_ "GenSigInvalidValue" SG_ 588 FLWS_POS_VIT_FL "0x7F";
BA_ "GenSigInvalidValue" SG_ 588 FRWS_POS_VIT_FL "0x7F";
BA_ "GenSigInvalidValue" SG_ 588 RLWS_POS_VIT_FL "0x7F";
BA_ "GenSigInvalidValue" SG_ 588 RRWS_POS_VIT_FL "0x7F";
BA_ "GenMsgCycleTime" BO_ 589 100 ;
BA_ "GenSigInvalidValue" SG_ 589 BCM_LFDoorLockStatus "0x7";
BA_ "GenSigInvalidValue" SG_ 589 BCM_TrunkDoorLockSts "0x7";
BA_ "GenSigInvalidValue" SG_ 589 BCM_RFDoorLockStatus "0x7";
BA_ "GenSigInvalidValue" SG_ 589 BCM_LRDoorLockStatus "0x7";
BA_ "GenSigInvalidValue" SG_ 589 BCM_RRDoorLockStatus "0x7";
BA_ "GenMsgCycleTime" BO_ 610 200 ;
BA_ "GenSigInvalidValue" SG_ 610 BCM_FL_TirePrs "0xFF";
BA_ "GenSigInvalidValue" SG_ 610 BCM_FR_TirePrs "0xFF";
BA_ "GenSigInvalidValue" SG_ 610 BCM_RL_TirePrs "0xFF";
BA_ "GenSigInvalidValue" SG_ 610 BCM_RR_TirePrs "0xFF";
BA_ "GenMsgCycleTime" BO_ 612 200 ;
BA_ "GenSigInvalidValue" SG_ 612 BCM_FL_TireTpt "0xFF";
BA_ "GenSigInvalidValue" SG_ 612 BCM_FR_TireTpt "0xFF";
BA_ "GenSigInvalidValue" SG_ 612 BCM_RL_TireTpt "0xFF";
BA_ "GenSigInvalidValue" SG_ 612 BCM_RR_TireTpt "0xFF";
BA_ "GenMsgCycleTime" BO_ 613 200 ;
BA_ "GenMsgSendType" BO_ 665 2;
BA_ "GenMsgCycleTimeFast" BO_ 665 100 ;
BA_ "GenMsgNrOfRepetition" BO_ 665 3 ;
BA_ "GenSigSendType" SG_ 665 DSM_D_SlideDirection 3;
BA_ "GenSigSendType" SG_ 665 DSM_D_FrontLiftDirection 3;
BA_ "GenSigSendType" SG_ 665 DSM_D_ReclinerDirection 3;
BA_ "GenSigSendType" SG_ 665 DSM_D_AllLiftDirection 3;
BA_ "GenSigSendType" SG_ 665 DSM_DrvSeatHandyEntryExitSetStus 3;
BA_ "GenSigInvalidValue" SG_ 665 DSM_DrvSeatHandyEntryExitSetStus "0x0";
BA_ "GenSigSendType" SG_ 665 DSM_D_SlidePosPercentFinal 3;
BA_ "GenSigInvalidValue" SG_ 665 DSM_D_SlidePosPercentFinal "0x7F";
BA_ "GenSigSendType" SG_ 665 DSM_D_FrontLiftPosPercentFinal 3;
BA_ "GenSigInvalidValue" SG_ 665 DSM_D_FrontLiftPosPercentFinal "0x7F";
BA_ "GenSigSendType" SG_ 665 DSM_D_ReclinerPosPercentFinal 3;
BA_ "GenSigInvalidValue" SG_ 665 DSM_D_ReclinerPosPercentFinal "0x7F";
BA_ "GenSigSendType" SG_ 665 DSM_D_AllLiftPosPercentFinal 3;
BA_ "GenSigInvalidValue" SG_ 665 DSM_D_AllLiftPosPercentFinal "0x7F";
BA_ "GenMsgSendType" BO_ 667 2;
BA_ "GenMsgCycleTimeFast" BO_ 667 100 ;
BA_ "GenMsgNrOfRepetition" BO_ 667 3 ;
BA_ "GenSigSendType" SG_ 667 DSM_P_SlideDirection 3;
BA_ "GenSigSendType" SG_ 667 DSM_P_FrontLiftDirection 3;
BA_ "GenSigSendType" SG_ 667 DSM_P_ReclinerDirection 3;
BA_ "GenSigSendType" SG_ 667 DSM_P_AllLiftDirection 3;
BA_ "GenSigSendType" SG_ 667 DSM_P_SlidePosPercentFinal 3;
BA_ "GenSigInvalidValue" SG_ 667 DSM_P_SlidePosPercentFinal "0x7F";
BA_ "GenSigSendType" SG_ 667 DSM_P_FrontLiftPosPercentFinal 3;
BA_ "GenSigInvalidValue" SG_ 667 DSM_P_FrontLiftPosPercentFinal "0x7F";
BA_ "GenSigSendType" SG_ 667 DSM_P_ReclinerPosPercentFinal 3;
BA_ "GenSigInvalidValue" SG_ 667 DSM_P_ReclinerPosPercentFinal "0x7F";
BA_ "GenSigSendType" SG_ 667 DSM_P_AllLiftPosPercentFinal 3;
BA_ "GenSigInvalidValue" SG_ 667 DSM_P_AllLiftPosPercentFinal "0x7F";
BA_ "GenMsgCycleTime" BO_ 659 200 ;
BA_ "GenMsgCycleTime" BO_ 856 200 ;
VAL_ 340 RCTA_warm_status_left 0 " No Alarm" 1 " warning" 2 " Serious Warnning" 3 " Invalid"  ;
VAL_ 340 BSDLCA_warm_status_left 0 " No Alarm" 1 " warning" 2 " Serious Warnning" 3 " Invalid"  ;
VAL_ 340 BSD_ConnectionFault_left 0 " 正常；" 1 " 异常；"  ;
VAL_ 340 BSD_RFICFault_left 0 " 正常；" 1 " 异常；"  ;
VAL_ 340 BSD_OverTempFault_left 0 " 正常；" 1 " 异常；"  ;
VAL_ 340 BSD_StoreFault_left 0 " 正常；" 1 " 异常；"  ;
VAL_ 340 BSDDOW_warm_status_left 0 " No Alarm" 1 " warning" 2 " Serious Warnning" 3 " Invalid"  ;
VAL_ 340 BSD_EnableStatus 0 " Invalid" 1 " BSD系统待机" 2 " BSD系统工作" 3 " BSD系统异常"  ;
VAL_ 344 RCTA_warm_status_right 0 " No Alarm" 1 " warning" 2 " Serious Warnning" 3 " Invalid"  ;
VAL_ 344 BSDLCA_warm_status_right 0 " No Alarm" 1 " warning" 2 " Serious Warnning" 3 " Invalid"  ;
VAL_ 344 BSD_ConnectionFault_right 0 " 正常；" 1 " 异常；"  ;
VAL_ 344 BSD_RFICFault_right 0 " 正常；" 1 " 异常；"  ;
VAL_ 344 BSD_OverTempFault_right 0 " 正常；" 1 " 异常；"  ;
VAL_ 344 BSD_StoreFault_right 0 " 正常；" 1 " 异常；"  ;
VAL_ 344 BSDDOW_warm_status_right 0 " No Alarm" 1 " warning" 2 " Serious Warnning" 3 " Invalid"  ;
VAL_ 148 EHB_AEB_Available 0 " Available" 1 " Unavailable"  ;
VAL_ 148 EHB_ACC_Available 0 " Available" 1 " Unavailable"  ;
VAL_ 148 EHB_BrkPelPosActVD 0 " Invalid" 1 " Valid"  ;
VAL_ 148 EHB_FaultSt 0 " No fault" 1 " Fault state1" 2 " Fault state2" 3 " Fault state3" 4 " Fault state4" 5 " Fault state5" 6 " Fault state6" 7 " Reserved"  ;
VAL_ 148 EHB_AEB_Jerk_Response 0 " No response" 1 " Response"  ;
VAL_ 148 EHB_AEB_Request_Response 0 " No response" 1 " Response"  ;
VAL_ 148 EHB_Prefill_Response 0 " No response" 1 " Response"  ;
VAL_ 148 EHB_ACC_Request_Response 0 " No response" 1 " Response"  ;
VAL_ 148 EHB_RegTorqReqVD 0 " Invalid" 1 " Valid"  ;
VAL_ 148 EHB_BrakePedalAppliedSt 0 " not pressed" 1 " pressed"  ;
VAL_ 148 EHB_BrakePedalApplied_Validity 0 " NotInitialized" 1 " Normal" 2 " Faulty" 3 " reserved"  ;
VAL_ 148 EHBDiagActive 0 " Nbooster诊断服务未激活" 1 " Nbooster诊断服务激活"  ;
VAL_ 148 EHB_BrkLightAct 0 " No request to the brake light" 1 " Brake light requested"  ;
VAL_ 148 EHB_Hold 0 " Unhold" 1 " Hold"  ;
VAL_ 148 EHB_Hold_Available 0 " Available" 1 " Unavailable"  ;
VAL_ 328 EPB_TMM_Open_Request_L 0 " No request" 1 " Request"  ;
VAL_ 328 EPB_Brake_Lights_Request_L 0 " No request" 1 " Request"  ;
VAL_ 328 EPB_SwitchSta_L 0 " Neutral" 1 " Release" 2 " Apply" 3 " invalid"  ;
VAL_ 328 EPB_WarnLampSta_L 0 " OFF" 1 " ON" 2 " Blinking" 3 " Reserved"  ;
VAL_ 328 EPB_ParkLampSta_L 0 " OFF" 1 " ON" 2 " Blinking" 3 " Reserved"  ;
VAL_ 328 EPB_DynamicApplySta_L 0 " Not Active" 1 " EDC request active EDC" 2 " RWU active RWU" 3 " Degrade Apply"  ;
VAL_ 328 EPB_ActuatorSt_L 0 " Releasing" 1 " Brake On" 2 " Brake Off" 3 " Applying" 4 " Maintenance brake off" 5 " Broken" 6 " Hold" 7 " ActuatorAdjust"  ;
VAL_ 328 EPB_Dclrtin_request_status_L 0 " No request" 1 " Request"  ;
VAL_ 328 EPB_CC_Cancel_Request_L 0 " No request" 1 " Request"  ;
VAL_ 328 EPB_DisplayMsgID_L 0 " off" 1 " Fasten seatbelt" 2 " push brake pedal" 3 " Change Gear to no P gear"  ;
VAL_ 336 EPB_TMM_Open_Request__R 0 " No request" 1 " Request"  ;
VAL_ 336 EPB_Brake_Lights_Request_R 0 " No request" 1 " Request"  ;
VAL_ 336 EPB_SwitchSta_R 0 " Neutral" 1 " Release" 2 " Apply" 3 " invalid"  ;
VAL_ 336 EPB_WarnLampSta_R 0 " OFF" 1 " ON" 2 " Blinking" 3 " Reserved"  ;
VAL_ 336 EPB_ParkLampSta_R 0 " OFF" 1 " ON" 2 " Blinking" 3 " Reserved"  ;
VAL_ 336 EPB_DynamicApplySta_R 0 " Not Active" 1 " EDC request active EDC" 2 " RWU active RWU" 3 " Degrade Apply"  ;
VAL_ 336 EPB_ActuatorSt_R 0 " Releasing" 1 " Brake On" 2 " Brake Off" 3 " Applying" 4 " Maintenance brake off" 5 " Broken" 6 " Hold" 7 " ActuatorAdjust"  ;
VAL_ 336 EPB_Dclrtin_request_status_R 0 " No request" 1 " Request"  ;
VAL_ 336 EPB_CC_Cancel_Request_R 0 " No request" 1 " Request"  ;
VAL_ 336 EPB_DisplayMsgID_R 0 " off" 1 " Fasten seatbelt" 2 " push brake pedal" 3 " Change Gear to no P gear"  ;
VAL_ 274 EPS_SteeringWheelAngVD 0 " Invalid" 1 " Valid"  ;
VAL_ 274 EPS_SASFailureSts 0 " Sensor information invalid an internal sensor fault occurred传感器信息无效发生内部传感器故障" 1 " Sensor information valid传感器信息有效"  ;
VAL_ 274 EPS_TorsionBarTorqueValid 0 " Invalid" 1 "Valid"  ;
VAL_ 274 EPS_TorsionBarTorqueDir 0 " Positive" 1 " Negative"  ;
VAL_ 274 EPS_Fault 0 " off 故障灯灭" 1 " on 故障灯亮" 2 " flashing 故障灯闪烁（没标中位）"  ;
VAL_ 274 MMI_EpsModeFeedback 0 " Invalid" 1 " Conf舒适" 2 " Standard标准" 3 " Sport运动" 4 " Snowfield雪地" 5 " Reserved" 6 " Reserved" 7 " Reserved"  ;
VAL_ 274 EPS_SteerWheelRotSpdVD 0 " Invalid" 1 " Valid"  ;
VAL_ 144 ESC_TCSActive 0 " Not Active" 1 " Active"  ;
VAL_ 144 ESC_HHC_Failure 0 " no failure" 1 " failure"  ;
VAL_ 144 ESC_HHCActive 0 " Not Active" 1 " Active"  ;
VAL_ 144 ESC_EBDFailed 0 " no failure" 1 " failure"  ;
VAL_ 144 ESC_EBDActive 0 " Not Active" 1 " Active"  ;
VAL_ 144 ESC_RBSState 0 " Not allowed不能回馈制动" 1 " Allowed允许回馈制动"  ;
VAL_ 144 ESC_ABSFailed 0 " no failure" 1 " failure"  ;
VAL_ 144 ESC_ABSActive 0 " Not Active" 1 " Active"  ;
VAL_ 144 ESC_AVHactive 0 " Not Active" 1 " Active"  ;
VAL_ 144 ESC_AutoholdStandby 0 " Not standby" 1 " Standby"  ;
VAL_ 144 ESC_AutoholdFailure 0 " no failure" 1 " failure"  ;
VAL_ 144 ESC_Sw 0 " ESC switch on" 1 " ESC switch off"  ;
VAL_ 144 ESC_HBAActive 0 " Not Active" 1 " Active"  ;
VAL_ 144 ESC_VDCFailure 0 " no failure" 1 " failure"  ;
VAL_ 144 ESC_VDCActive 0 " Not Active" 1 " Active"  ;
VAL_ 144 ESC_TCSFailure 0 " no failure" 1 " failure"  ;
VAL_ 144 ESC_CDPAvailable 0 " no failure" 1 " failure"  ;
VAL_ 144 ESC_CDPActive 0 " Not Active" 1 " Active"  ;
VAL_ 144 ESC_EPBRequest 0 " No Request" 1 " Apply Request" 2 " Release Request" 3 " Invalid"  ;
VAL_ 144 ESC_AVH_Warning1 0 " Inactive" 1 " Active"  ;
VAL_ 144 ESC_AVH_Warning2 0 " Inactive" 1 " Active"  ;
VAL_ 144 ESC_AVH_Warning3 0 " Inactive" 1 " Active"  ;
VAL_ 144 ESC_AVH_Warning4 0 " Inactive" 1 " Active"  ;
VAL_ 144 ESC_Brake_Light_Control 0 " OFF" 1 " ON"  ;
VAL_ 144 ESC_BrkPrsVd 0 " Not Active" 1 " Active"  ;
VAL_ 146 ESC_WhlSpdFRVd 0 " invalid" 1 " Valid"  ;
VAL_ 146 ESC_WhlSpdFLVd 0 " invalid" 1 " Valid"  ;
VAL_ 146 ESC_VehSpdVd 0 " invalid" 1 " Valid"  ;
VAL_ 342 SteerWheel_L_OK 0 " not pressed" 1 " pressed"  ;
VAL_ 342 SteerWheel_Voice 0 " not pressed" 1 " pressed"  ;
VAL_ 342 SteerWheel_VOL_Inc 0 " not pressed" 1 " pressed"  ;
VAL_ 342 SteerWheel_VOL_Dec 0 " not pressed" 1 " pressed"  ;
VAL_ 342 SteerWheel_PREV 0 " not pressed" 1 " pressed"  ;
VAL_ 342 SteerWheel_Defi 0 " not pressed" 1 " pressed"  ;
VAL_ 342 SteerWheel_NEXT 0 " not pressed" 1 " pressed"  ;
VAL_ 342 SteerWheel_Mode 0 " not pressed" 1 " pressed"  ;
VAL_ 342 SteerWheel_Return_Home 0 " not pressed" 1 " pressed"  ;
VAL_ 342 AmphereLampSta_IntePerSW 0 " Invalid" 1 " OFF" 2 " ON" 3 " Reserved"  ;
VAL_ 342 SteerWheel_Hang_Down 0 " not pressed" 1 " pressed"  ;
VAL_ 342 AmphereLampMode 0 " 无效" 1 " 自定义模式" 2 " 车速随动模式" 3 " 驾驶随动模式"  ;
VAL_ 342 AmphereLampUserDefModeStatus 0 " 无效" 1 " 单色常亮" 2 " 单色呼吸" 3 " 炫彩呼吸"  ;
VAL_ 342 AmphereLampSta_SW 0 " Invalid" 1 " OFF" 2 " ON" 3 " Reserved"  ;
VAL_ 342 AmphereLampSta_Colour 0 " 默认颜色" 1 " 红色" 2 " 橙色" 3 " 黄色" 4 " 绿色" 5 " 青色" 6 " 蓝色" 7 " 紫色"  ;
VAL_ 594 MCU_F_ResolverFault 0 " No_Failure" 1 " Failure"  ;
VAL_ 594 MCU_F_Err_IGBT 0 " No_Failure" 1 " Failure"  ;
VAL_ 594 MCU_F_CurrentOverload 0 " fault-free无故障；" 1 " First-level faults一级故障；" 2 " Second-degree faults二级故障；" 3 " reserved保留"  ;
VAL_ 594 MCU_F_Controllertemp_Status 0 " fault-free无故障；" 1 " First-level faults一级故障；" 2 " Second-degree faults二级故障；" 3 " reserved保留"  ;
VAL_ 594 MCU_F_stDischg 0 " off未泄放" 1 " discharging主动泄放中" 2 " finished泄放完成" 3 " fault泄放故障"  ;
VAL_ 594 MCU_F_SpeedOtLoopFalult 0 " No_Failure" 1 " Failure"  ;
VAL_ 594 MCU_F_MdTepErr 0 " No_Failure" 1 " Failure"  ;
VAL_ 594 MCU_F_ControllerOverVolt_Status 0 " fault-free无故障；" 1 " First-level faults一级故障；" 2 " Second-degree faults二级故障；" 3 " reserved保留"  ;
VAL_ 594 MCU_F_MotorTemp_Fault 0 " fault-free无故障；" 1 " First-level faults一级故障；" 2 " Second-degree faults二级故障；" 3 " reserved保留"  ;
VAL_ 594 MCU_F_MotorOverSpd 0 " No_Failure" 1 " Failure"  ;
VAL_ 594 MCU_F_VCUCommErr 0 " No_Failure" 1 " Failure"  ;
VAL_ 594 MCU_F_ControllerLowUnderVolt_Status 0 " No_Failure" 1 " Failure"  ;
VAL_ 594 MCU_F_ControllerUnderVolt_Status 0 " fault-free无故障；" 1 " First-level faults一级故障；" 2 " Second-degree faults二级故障；" 3 " reserved保留"  ;
VAL_ 594 MCU_F_ControllerFault 0 " fault-free无故障；" 1 " First-level faults一级故障（报警，无上下电要求 Alarm，no power up and down req）；" 2 " Second-degree faults二级故障（降功率，无上下电要求 reduce power，no power up and down req）；" 3 " Third-degree faults三级故障" 4 " Fourth-degree faults四级故障(下高压，不允许上高压，若MCU高压在充电回路，不允许充电 down HV,fobit up HV,if MCU HV is charging,forbit charge)；" 5 " Reserved" 6 " Reserved" 7 " Reserved"  ;
VAL_ 594 FMCU_HV_Interlock_Falult 0 " Invalid" 1 " No_Failure无故障" 2 " Failure故障" 3 " Reserved预留"  ;
VAL_ 594 FMCU_Uncap_Falult 0 " Invalid" 1 " No_Failure无故障" 2 " Failure故障" 3 " Reserved预留"  ;
VAL_ 594 MCU_F_MotTepErr 0 " No_Failure" 1 " Failure"  ;
VAL_ 130 MCU_F_stMode 0 " Initialization 初始化模式" 1 " Precharge 预充模式" 2 " Standby 待机模式" 3 " RUN 扭矩或转速模式" 4 " Failure 故障模式" 5 " Discharge 主动放电模式" 6 " Afterrun 下电模式" 7 " Reserved" 8 " Reserved" 9 " Reserved" 10 " Reserved" 11 " Reserved" 12 " Reserved" 13 " Reserved" 14 " Reserved" 15 " Reserved"  ;
VAL_ 130 MCU_F_TrqCurrValid 0 " Normal" 1 " Failure"  ;
VAL_ 130 MCU_F_NCurrValid 0 " Normal" 1 " Failure"  ;
VAL_ 608 MCU_R_ResolverFault 0 " No_Failure" 1 " Failure"  ;
VAL_ 608 MCU_R_Err_IGBT 0 " No_Failure" 1 " Failure"  ;
VAL_ 608 MCU_R_CurrentOverload 0 " fault-free无故障；" 1 " First-level faults一级故障；" 2 " Second-degree faults二级故障；" 3 " reserved保留"  ;
VAL_ 608 MCU_R_Controllertemp_Status 0 " fault-free无故障；" 1 " First-level faults一级故障；" 2 " Second-degree faults二级故障；" 3 " reserved保留"  ;
VAL_ 608 MCU_R_stDischg 0 " off未泄放" 1 " discharging主动泄放中" 2 " finished泄放完成" 3 " fault泄放故障"  ;
VAL_ 608 MCU_R_SpeedOtLoopFalult 0 " No_Failure" 1 " Failure"  ;
VAL_ 608 MCU_R_MdTepErr 0 " No_Failure" 1 " Failure"  ;
VAL_ 608 MCU_R_ControllerOverVolt_Status 0 " fault-free无故障；" 1 " First-level faults一级故障；" 2 " Second-degree faults二级故障；" 3 " reserved保留"  ;
VAL_ 608 MCU_R_MotorTemp_Fault 0 " fault-free无故障；" 1 " First-level faults一级故障；" 2 " Second-degree faults二级故障；" 3 " reserved保留"  ;
VAL_ 608 MCU_R_MotorOverSpd 0 " No_Failure" 1 " Failure"  ;
VAL_ 608 MCU_R_VCUCommErr 0 " No_Failure" 1 " Failure"  ;
VAL_ 608 MCU_R_ControllerLowUnderVolt_Status 0 " No_Failure" 1 " Failure"  ;
VAL_ 608 MCU_R_ControllerUnderVolt_Status 0 " fault-free无故障；" 1 " First-level faults一级故障；" 2 " Second-degree faults二级故障；" 3 " reserved保留"  ;
VAL_ 608 MCU_R_ControllerFault 0 " fault-free无故障；" 1 " First-level faults一级故障（报警，无上下电要求 Alarm，no power up and down req）；" 2 " Second-degree faults二级故障（降功率，无上下电要求 reduce power，no power up and down req）；" 3 " Third-degree faults三级故障" 4 " Fourth-degree faults四级故障(下高压，不允许上高压，若MCU高压在充电回路，不允许充电 down HV,fobit up HV,if MCU HV is charging,forbit charge)；" 5 " Reserved" 6 " Reserved" 7 " Reserved"  ;
VAL_ 608 RMCU_HV_Interlock_Falult 0 " Invalid" 1 " No_Failure无故障" 2 " Failure故障" 3 " Reserved预留"  ;
VAL_ 608 RMCU_Uncap_Falult 0 " Invalid" 1 " No_Failure无故障" 2 " Failure故障" 3 " Reserved预留"  ;
VAL_ 608 MCU_R_MotTepErr 0 " No_Failure" 1 " Failure"  ;
VAL_ 178 MCU_R_stMode 0 " Initialization 初始化模式" 1 " Precharge 预充模式" 2 " Standby 待机模式" 3 " RUN 扭矩或转速模式" 4 " Failure 故障模式" 5 " Discharge 主动放电模式" 6 " Afterrun 下电模式" 7 " Reserved" 8 " Reserved" 9 " Reserved" 10 " Reserved" 11 " Reserved" 12 " Reserved" 13 " Reserved" 14 " Reserved" 15 " Reserved"  ;
VAL_ 178 MCU_R_TrqCurrValid 0 " Normal" 1 " Failure"  ;
VAL_ 178 MCU_R_NCurrValid 0 " Normal" 1 " Failure"  ;
VAL_ 772 OBC_out_Cur_over_prot 0 " False正常；" 1 " True异常；"  ;
VAL_ 772 OBC_out_vol_Less_prot 0 " False正常；" 1 " True异常；"  ;
VAL_ 772 OBC_out_vol_over_prot 0 " False正常；" 1 " True异常；"  ;
VAL_ 772 OBC_In_Cur_over_prot 0 " False正常；" 1 " True异常；"  ;
VAL_ 772 OBC_ChargerInputVoltageLessFault 0 " False正常；" 1 " True异常；"  ;
VAL_ 772 OBC_ChargerInputVoltageOverFault 0 " False正常；" 1 " True异常；"  ;
VAL_ 772 ChargeInterfaceOverTemp 0 " 温度正常；" 1 " 过温；"  ;
VAL_ 772 OBC_ChargerOTP 0 " No failure无故障；" 1 " 温度过高一级故障；" 2 " 温度过高二级故障；" 3 " 温度过高三级故障；"  ;
VAL_ 772 OBC_ChargerCoolingRequest 0 " 不需冷却；" 1 " 请求冷却；"  ;
VAL_ 772 OBC_ChargerHardwareFault 0 " True正常；" 1 " False异常；"  ;
VAL_ 772 OBC_Charger_CAN_Fault 0 " No failure无故障；" 1 " failure故障；"  ;
VAL_ 772 OBC_Charger_Fail_State 0 " No failure无故障；" 1 " failure故障；"  ;
VAL_ 772 OBC_Charger_NoBatt 0 " 未连接；" 1 " 连接；" 2 " 电池包电压过低；"  ;
VAL_ 772 OBC_CP_Rsv 0 " False；" 1 " Connected"  ;
VAL_ 772 OBC_CC_Resistance 0 " 未连接；" 1 " 半连接；" 2 " 充电电缆数量为10A；" 3 " 充电电缆数量为16A；" 4 " 充电电缆数量为32A；" 5 " 充电电缆数量为63A；" 6 " Reserved；" 7 " Reserved；"  ;
VAL_ 772 OBC_ChargerStatus 0 " Init（初始化）" 1 " Standby（待机）" 2 " Working（工作）" 3 " ChargerOver（类似于关机，过一段时间会休眠）" 4 " Sleep（休眠）" 5 " Recovery Fault（可恢复故障）" 6 " DisRecovery Fault（不可恢复故障，输出过欠压不可恢复，其余均可恢复）" 7 " Reserved"  ;
VAL_ 772 KL30_UnderVolt 0 " 正常；" 1 " 过压；" 2 " 欠压；" 3 " Reserved"  ;
VAL_ 772 ElectronicLockSts 0 " 解锁状态；" 1 " 闭锁状态；"  ;
VAL_ 772 ElectronicLockFault 0 " 无故障；" 1 " 解锁故障；" 2 " 闭锁故障；" 3 " Reserved"  ;
VAL_ 772 OBC_Charger_Instructions 0 " 未充电；" 1 " 充电中（OBC输出电流＞0A）；"  ;
VAL_ 772 OBC_Charger_Request 0 " 不请求充电；" 1 " 请求充电；"  ;
VAL_ 776 DCDC_Status 0 " normal正常输出" 1 " sleep休眠" 2 " standby待机"  ;
VAL_ 776 DCDC_IN_vol_over_prot 0 " normal" 1 " overvoltage"  ;
VAL_ 776 DCDC_IN_vol_Less_prot 0 " normal" 1 " undervoltage"  ;
VAL_ 776 DCDC_short_err 0 " normal" 1 " short"  ;
VAL_ 776 DCDC_Out_Curr_Over_prot 0 " normal" 1 " Overcurr"  ;
VAL_ 776 DCDC_out_vol_over_prot 0 " normal" 1 " overvoltage"  ;
VAL_ 776 DCDC_out_vol_Less_prot 0 " normal" 1 " undervoltage"  ;
VAL_ 776 DCDC_out_VolSt 0 " normal" 1 " overvoltage" 2 " undervoltage"  ;
VAL_ 776 DCDC_Fault 0 " No failure无故障；" 1 " failure故障；" 2 " reserved"  ;
VAL_ 776 DCDC_OverTemp_Fault 0 " No failure无故障；" 1 " 温度过高一级故障；" 2 " 温度过高二级故障；" 3 " 温度过高三级故障；"  ;
VAL_ 776 DCDC_WorkingMode 0 " normal" 1 " abnormal"  ;
VAL_ 776 DCDC_EnableSts 0 " normal" 1 " abnormal"  ;
VAL_ 776 DCDC_CoolingReq 0 " 不需冷却；" 1 " 请求冷却；"  ;
VAL_ 372 VCU_Err_BrakeSwitch 0 " No_Error无错误" 1 " Error错误"  ;
VAL_ 372 VCU_Err_BrakePedal 0 " No_Error无错误" 1 " Error错误"  ;
VAL_ 372 VCU_Err_AccPedal 0 " No_Error无错误" 1 " Error错误"  ;
VAL_ 372 VCU_GearPosition 0 " Invalid" 1 " P档" 2 " R倒挡" 3 " N空挡" 4 " D前进挡" 5 " Reserved保留" 6 " Error错误" 7 " Reserved保留" 8 " Reserved保留" 9 " Reserved保留" 10 " Reserved保留" 11 " Reserved保留" 12 " Reserved保留" 13 " Reserved保留" 14 " Reserved保留" 15 " Reserved保留"  ;
VAL_ 372 VCU_PrechrgAnodeRelay_Status 0 " Invalid" 1 " Open打开" 2 " Connect连接" 3 " Reserved"  ;
VAL_ 372 VCU_DischrgAnodeRelay_Control 0 " Open打开" 1 " Connect连接"  ;
VAL_ 372 VCU_DischrgAnodeRelay_Status 0 " Invalid" 1 " Open打开" 2 " Connect连接" 3 " Reserved"  ;
VAL_ 372 VCU_DischrgCathodeRelay_Control 0 " Open打开" 1 " Connect连接"  ;
VAL_ 372 VCU_DischrgCathodeRelay_status 0 " Invalid" 1 " Open打开" 2 " Connect连接" 3 " Reserved"  ;
VAL_ 372 VCU_PrechrgAnodeRelay_Control 0 " Open打开" 1 " Connect连接"  ;
VAL_ 372 VCU_PTSystem_Satus 0 " normal无故障" 1 " slight一般动力系统故障" 2 " serious严重动力系统故障" 3 " reserved预留"  ;
VAL_ 372 VCU_VehSysStatus 0 " invalid" 1 " 初始化状态" 2 " HV_Off" 3 " StartHVing" 4 " StartHving_Fault" 5 " ShutdownHVing" 6 " Local_HV" 7 " Remote_READY" 8 " Local_READY" 9 " ACChargeMode" 10 " DCChargeMode" 11 " V2VChargeMode" 12 " NorShutdownCpt" 13 " FaultShutdownCpt" 14 " Initialization_Fail" 15 "Remote_HV" 16 " reserved" 17 " reserved" 18 " reserved" 19 " reserved" 20 " reserved" 21 " reserved" 22 " reserved" 23 " reserved" 24 " reserved" 25 " reserved" 26 " reserved" 27 " reserved" 28 " reserved" 29 " reserved" 30 " reserved" 31 " reserved"  ;
VAL_ 372 VCU_ChrgRelay_Control 0 " Open打开" 1 " Connect连接"  ;
VAL_ 372 VCU_Cruise_MainSwitch 0 " Cruise_Main_Switch_Off关闭" 1 " Cruise_Main_Switch_On打开"  ;
VAL_ 372 VCU_OperationMode 0 " Reserved保留" 1 " normal正常" 2 " Economic经济" 3 " Sport运动"  ;
VAL_ 372 VCU_DrivingMode 0 " 2 drive 两驱" 1 " 4 drive 四驱" 2 " Auto" 3 " Reservedd"  ;
VAL_ 372 VCU_SpeedMode 0 " torque_model转矩模式" 1 " speed_model转速模式"  ;
VAL_ 372 VCU_TortoiseIndicator 0 " OFF关闭" 1 " ON打开"  ;
VAL_ 372 VCU_Comd_OpenHazardWarningLamp 0 " OFF关闭" 1 " ON打开"  ;
VAL_ 372 VCU_ActiveDischargeOrder 0 " disactive关闭" 1 " active开启"  ;
VAL_ 372 VCU_Cruise_Enable 0 " inactive" 1 " active"  ;
VAL_ 372 VCU_UnlockSts 0 " Invalid" 1 " succeed防盗解除成功" 2 " failed防盗解除失败" 3 " reserved"  ;
VAL_ 372 VCU_StartAllow 0 " Allowed" 1 " Not allowed"  ;
VAL_ 568 VCU_AC_Permittion 0 " prohibit" 1 " allow"  ;
VAL_ 568 VCU_AirPTC_Permittion 0 " prohibit" 1 " allow"  ;
VAL_ 568 VCU_WPTC_Permittion 0 " prohibit" 1 " allow"  ;
VAL_ 568 FPump_Enable 0 " false" 1 " true"  ;
VAL_ 568 VCU_VehicleMaintenanceMode 0 " Inactive" 1 " active" 2 " Reserved" 3 " Reserved"  ;
VAL_ 568 VCU_CoolingFanSt 0 " Invalid" 1 " first_gear" 2 " second_gear" 3 " Reserved"  ;
VAL_ 568 VCU_StartInf 0 "无提示" 1 "启动时请勿松开制动踏板" 2 "启动时请勿睬油门" 3 "禁止在充电时启动车辆" 4 "请在P挡或N挡启动车辆" 5 "  请确保深踩刹车、松开油门、断开充电枪、档位P/N" 6 " Reserved" 7 " Reserved"  ;
VAL_ 568 VCU_ChaGearInf 0 "无提示" 1 "请踩住制动踏板换挡" 2 "车辆行驶中，禁止换挡" 3 "换挡失败，请重新尝试" 4 " Reserved" 5 " Reserved" 6 " Reserved" 7 " Reserved"  ;
VAL_ 570 VCU_Fastchrg_Permittion 0 " Invalid" 1 " prohibit" 2 " allow" 3 " Reserved"  ;
VAL_ 570 VCU_Slowchrg_Permittion 0 " Invalid" 1 " prohibit" 2 " allow" 3 " Reserved"  ;
VAL_ 570 VCU_AC_ChrgStatus 0 " DCChrgDisable" 1 " ChrgHandSharking" 2 " ChrgFault" 3 " DC_Charing" 4 " DC_Heating" 5 " ChargeToHeatHangup" 6 " HeatToChargeHangup" 7 " ChargeShutDown"  ;
VAL_ 570 VCU_OBC_Permittion 0 " prohibit" 1 " allow"  ;
VAL_ 570 VCU_EnergyRecoverySt 0 " Lev0" 1 " Lev1" 2 " Lev2" 3 " Lev3" 4 " reserved" 5 " reserved" 6 " reserved" 7 " invalid"  ;
VAL_ 570 VCU_PwrFlowIndcr 0 " No Power Flow" 1 " Charging Power Flow" 2 " Charge Finished Power Flow" 3 " Driving Power Flow" 4 " Regener Power Flow" 5 " reserved" 6 " reserved" 7 " reserved"  ;
VAL_ 570 VCU_WPTC_Permittion 0 " prohibit" 1 " allow"  ;
VAL_ 570 VCU_AC_Permittion 0 " prohibit" 1 " allow"  ;
VAL_ 570 VCU_DC_ChrgStatus 0 " DCChrgDisable" 1 " ChrgHandSharking" 2 " ChrgFault" 3 " DC_Charing" 4 " DC_Heating" 5 " ChargeToHeatHangup" 6 " HeatToChargeHangup" 7 " ChargeShutDown"  ;
VAL_ 570 VCU_V2V_ChrgStatus 0 " DCChrgDisable" 1 " ChrgHandSharking" 2 " ChrgFault" 3 " DC_Charing" 4 " DC_Heating" 5 " ChargeToHeatHangup" 6 " HeatToChargeHangup" 7 " ChargeShutDown"  ;
VAL_ 574 VCU_TbUnlockSts 0 " Invalid" 1 " 防盗解除成功" 2 " 防盗解除失败" 3 " reserved"  ;
VAL_ 574 VCU_RCt_ModeSts 0 " OFF" 1 " ON"  ;
VAL_ 574 VCU_VehPowerMode 0 " 纯电动；" 1 " 混动；" 2 " 燃油；" 3 " reserved"  ;
VAL_ 574 VCU_Precharge_Satus 0 " Not_precharge" 1 " Pecharging" 2 " Precharge_complete" 3 " Precharge_Failure"  ;
VAL_ 574 VCU_request_subscribe_allow 0 " prohibit" 1 " allow"  ;
VAL_ 574 VCU_DCSystemDischrgAllowed 0 " Discharge_forbid" 1 " Discharge_allow" 2 " Reserved" 3 " Reserved"  ;
VAL_ 574 VCU_MotorLockAllowed 0 " Allowed" 1 " Not Allowed"  ;
VAL_ 574 VCU_MotorLockSts 0 " unlocked" 1 " locking" 2 " reserved" 3 " reserved"  ;
VAL_ 112 VCU_APA_FaildType 0 " none 无" 1 " user interrupt 用户干预" 2 " Vehicle fault整车系统故障" 3 " communication fault对APA通讯故障" 4 " reserved 预留" 5 " reserved 预留" 6 " reserved 预留" 7 " invalid"  ;
VAL_ 112 VCU_BrkPedPos_Validity 0 " Inactive" 1 " Active"  ;
VAL_ 112 VCU_BrkSw_Sta 0 " not pressed" 1 " pressed"  ;
VAL_ 112 VCU_EHB_VLC_Response 0 " No response" 1 " Response"  ;
VAL_ 112 VCU_BrkSw_V 0 " Inactive" 1 " Active"  ;
VAL_ 112 VCU_Acc_Validity 0 " Valid" 1 " Invalid"  ;
VAL_ 112 VCU_APA_ActiveEnableSts 0 " Inactive 未激活/未使能" 1 " Active 激活/使能"  ;
VAL_ 112 VCU_MotorTrqRegAllowed 0 " Not allowed" 1 " Allowed"  ;
VAL_ 112 VCU_Request_Response 0 " No response" 1 " Response"  ;
VAL_ 112 VCU_Kickdown_AEB 0 " No kickdown" 1 " Kickdown"  ;
VAL_ 112 VCU_Accel_Padel_Override 0 " No override" 1 " Override"  ;
VAL_ 112 VCU_Available 0 " Available" 1 " Unavailable"  ;
VAL_ 913 VSP_State 0 " OFF" 1 " ON" 2 " Fail（故障）" 3 " reserved"  ;
VAL_ 913 VSP_VoiceSourceSelectFeedback 0 " 无反馈" 1 " 声源切换成功" 2 " 声源切换失败" 3 " 保留"  ;
VAL_ 644 TBOX_ReservationChgCommandSet 0 " Default" 1 " SET" 2 " Cancel" 3 " Invalid"  ;
VAL_ 644 TBOX_ChrgMode 0 " 普通模式" 1 " 电池健康模式" 2 " 效率最高模式" 3 " reserved"  ;
VAL_ 644 TBOX_StopChrgRQ 0 " No Command；" 1 " 停止充电" 2 " 继续充电" 3 " reserved"  ;
VAL_ 645 TBOX_TimeCheckBit 0 " Valid" 1 " invalid"  ;
VAL_ 664 Tbox_MMI_FICM_Available 0 " Available" 1 " Unavailable"  ;
VAL_ 614 AC_PasCabinEnable 0 " prohibit不允许" 1 " allowed允许"  ;
VAL_ 614 AC_AirPTC_Enable 0 "inactive" 1 "active"  ;
VAL_ 614 AC_WPTC_RunStatus 0 " 关波" 1 " 开波"  ;
VAL_ 624 AC_AutoMode 0 " Invalid" 1 " 自动模式已开启" 2 " 自动模式未开启" 3 " reserved"  ;
VAL_ 624 AC_ActualBlowingMode 0 " Invalid" 1 " 吹面" 2 " 吹面吹脚" 3 " 吹脚" 4 " 吹脚吹玻璃" 5 " 吹玻璃" 6 " Reserved" 7 " Reserved"  ;
VAL_ 624 AC_ActualCirculationMode 0 " Invalid" 1 " 内循环" 2 " 外循环" 3 " reserved"  ;
VAL_ 624 AC_DVDDisplayReq 0 " No req" 1 " Req"  ;
VAL_ 624 AC_ActualAirQuantity 0 " Invalid" 1 " 1档；" 2 " 2档；" 3 " 3档；" 4 " 4档；" 5 " 5档；" 6 " 6档；" 7 " 7档；"  ;
VAL_ 624 AC_FwdDeforstSts 0 " OFF" 1 " ON"  ;
VAL_ 624 AC_RearDeforstSts 0 " OFF" 1 " ON"  ;
VAL_ 624 AC_CoolingStaus 0 " Invalid" 1 " opened" 2 " closed" 3 " reserved"  ;
VAL_ 624 AC_MaxCooingStaus 0 " Invalid" 1 " opened" 2 " closed" 3 " reserved"  ;
VAL_ 624 AC_OffStaus 0 " Invalid" 1 " valid"  ;
VAL_ 624 AC_PM25_Status 0 " Invalid" 1 " valid"  ;
VAL_ 624 AC_RearViewMirroHeatStatus 0 " Invalid" 1 " on" 2 " off" 3 " reserved"  ;
VAL_ 624 AC_NegativeIconGenStus 0 " Invalid" 1 " on" 2 " off" 3 " reserved"  ;
VAL_ 607 AC_BatteryPumpState 0 " 正常停机" 1 " 水泵运行" 2 " 故障停机" 3 " Reserved" 4 " Reserved" 5 " Reserved" 6 " Reserved" 7 " Reserved" 8 " Reserved" 9 " Reserved" 10 " Reserved" 11 " Reserved" 12 " Reserved" 13 " Reserved" 14 " Reserved" 15 " Reserved"  ;
VAL_ 607 AC_ACMode 0 " Off" 1 " Cabin cooling" 2 " Cabin heating" 3 " Defog" 4 " Defrost" 5 " Reserved" 6 " Reserved" 7 " Reserved" 8 " Reserved" 9 " Reserved" 10 " Reserved" 11 " Reserved" 12 " Reserved" 13 " Reserved" 14 " Reserved" 15 " Reserved"  ;
VAL_ 607 AC_RearDeforstReq 0 "off" 1 "on"  ;
VAL_ 607 AC_AmbientAirTemperature_Validity 0 " valid；" 1 " invalid"  ;
VAL_ 607 AC_Fan_SpeedReq 0 " No RQ" 1 " 1档" 2 " 2档" 3 " reserved"  ;
VAL_ 607 AC_SeatHeatReq_right 0 " off" 1 " 1档" 2 " 2档" 3 " reserved"  ;
VAL_ 607 AC_SeatHeatReq_left 0 " off" 1 " 1档" 2 " 2档" 3 " reserved"  ;
VAL_ 607 AC_WorkingResponse_Status 0 " invalid" 1 " 未工作" 2 " 加热" 3 " 制冷" 4 " 水泵自循环" 5 " 故障" 6 " 保留" 7 " 保留"  ;
VAL_ 607 AC_unload_Status 0 " Invalid" 1 " 未卸载" 2 " 卸载中" 3 " 卸载完成"  ;
VAL_ 338 BCM_RFDoorSwitchSt 0 " Close" 1 " Open"  ;
VAL_ 338 BCM_LFDoorSwitchSt 0 " Close" 1 " Open"  ;
VAL_ 338 BCM_PositionLampSt 0 " Close" 1 " Open"  ;
VAL_ 338 BCM_FrontFogligthSt 0 " Close" 1 " Open"  ;
VAL_ 338 BCM_BackFogligthSt 0 " Close" 1 " Open"  ;
VAL_ 338 BCM_HighBeamStatus 0 " Close" 1 " Open"  ;
VAL_ 338 BCM_LowBeamStatus 0 " Close" 1 " Open"  ;
VAL_ 338 BCM_TrunkSt 0 " Close" 1 " Open"  ;
VAL_ 338 BCM_TurnLeverLoc 0 " Invalid(左右转向未开启)" 1 " 左转向" 2 " 右转向" 3 " Reserved"  ;
VAL_ 338 BCM_RightligthFaultSt 0 " No_Failure" 1 " Failure"  ;
VAL_ 338 BCM_RightligthSt 0 " Close" 1 " Open"  ;
VAL_ 338 BCM_LetfligthFaultSt 0 " No_Failure" 1 " Failure"  ;
VAL_ 338 BCM_LetfligthSt 0 " Close" 1 " Open"  ;
VAL_ 338 BCM_LRDoorSwitchSt 0 " Close" 1 " Open"  ;
VAL_ 338 BCM_RRDoorSwitchSt 0 " Close" 1 " Open"  ;
VAL_ 338 BCM_CentralLockSt 0 " Lock" 1 " Unlock"  ;
VAL_ 338 BCM_Reverse_Light 0 " Off" 1 " On"  ;
VAL_ 338 BCM_Mainbeam_Available 0 " Available" 1 " Unavailable"  ;
VAL_ 338 Bcm_OutSwitchPressCmd 0 " Close" 1 " Open"  ;
VAL_ 338 BCM_HazardwarnLampSt 0 " Close" 1 " Open"  ;
VAL_ 338 BCM_PassSeatbeltBucklestatus 0 " Safety belt tied" 1 " Safety belt not tied"  ;
VAL_ 338 BCM_DrvSeatbeltBucklestatus 0 " Safety belt tied" 1 " Safety belt not tied"  ;
VAL_ 338 BCM_FrontCoverSt 0 " Close" 1 " Open"  ;
VAL_ 338 BCM_Auto_LightSwitch 0 " Off不处于AUTO挡" 1 " On处于AUTO挡"  ;
VAL_ 338 BCM_Brake_Light 0 " Off" 1 " On"  ;
VAL_ 338 BCM_RearViewMirrorAutoFoldFucFeedback 0 " invalid" 1 " close" 2 " open" 3 " Reserved"  ;
VAL_ 338 BCM_Rain_Sensor 0 " No rain(OFF)" 1 " Light rain(LOW)" 2 " Heavy rain(HIGH)"  ;
VAL_ 338 BCM_DrvSeatbeltBucklevalidity 0 " not valid" 1 " valid"  ;
VAL_ 338 BCM_PassSeatbeltBucklevalidity 0 " not valid" 1 " valid"  ;
VAL_ 338 BCM_PowerMode 0 " Invalid无效" 1 " OffPwr_Sts" 2 " Localkeyon" 3 " Remotekeyon                                                          0x4～0x7"  ;
VAL_ 338 BCM_RearViewMirror 0 " Invalid" 1 " 折叠" 2 " 展开" 3 " Reserved"  ;
VAL_ 338 BCM_ChargeCoverLockStatus 0 " unlock" 1 " lock"  ;
VAL_ 338 BCM_RearDeforstSts 0 " OFF" 1 " ON"  ;
VAL_ 338 BCM_BkSeat_1_beltBucklevalidity 0 " invalid" 1 " valid"  ;
VAL_ 338 BCM_BkSeat_1_beltBucklestatus 0 " Safety belt tied" 1 " Safety belt not tied"  ;
VAL_ 338 BCM_BkSeat_2_beltBucklevalidity 0 " invalid" 1 " valid"  ;
VAL_ 338 BCM_BkSeat_2_beltBucklestatus 0 " Safety belt tied" 1 " Safety belt not tied"  ;
VAL_ 338 BCM_BkSeat_3_beltBucklevalidity 0 " invalid" 1 " valid"  ;
VAL_ 338 BCM_BkSeat_3_beltBucklestatus 0 " Safety belt tied" 1 " Safety belt not tied"  ;
VAL_ 338 BCM_RainAutoClsWindowFuncStus 0 " invalid" 1 " Open" 2 " Close" 3 " Reserved"  ;
VAL_ 338 BCM_LockVehicleWarmingTipStus 0 " invalid" 1 " flash" 2 " flash with horn" 3 " Reserved"  ;
VAL_ 338 BCM_CourtesyLampStus 0 " Close" 1 " Open"  ;
VAL_ 338 BCM_VehicleCourtesyLampFuncStus 0 " invalid" 1 " close" 2 " open" 3 " Reserved"  ;
VAL_ 338 BCM_AccLampSetStus 0 " invalid" 1 " close" 2 " 开启(延迟30s关闭)" 3 " 开启(延迟60s关闭)"  ;
VAL_ 588 PEPS_KeyInCarWarning 0 " Inactive" 1 " Active"  ;
VAL_ 588 ReminderPutInP_Nposition_OFF 0 " Inactive" 1 " Active"  ;
VAL_ 588 ReminderPutInP_Nposition_Lock 0 " Inactive" 1 " Active"  ;
VAL_ 588 PEPS_KeyNotInWarning 0 " Inactive" 1 " Active"  ;
VAL_ 588 BCM_FrontWiperSt 0 " OFF" 1 " AUTO or INT" 2 " Continuous slow" 3 " Continuous fast"  ;
VAL_ 588 PEPS_PutKeyInIMMOSocket 0 " Inactive" 1 " Active"  ;
VAL_ 588 PEPS_PowerRelayFault 0 " Inactive" 1 " Active"  ;
VAL_ 588 PEPS_RemoteLowVoltage 0 " Inactive" 1 " Active"  ;
VAL_ 588 PEPS_ESCLFault 0 " no fault" 1 " fault"  ;
VAL_ 588 PEPS_ESCLUnlockFailed 0 " Normal" 1 " Unlock failed"  ;
VAL_ 588 BCM_OpenDoorWarning 0 " Normal" 1 " Alarm（车门已开，欢迎上车）"  ;
VAL_ 589 PEPS_LastLockType 0 " Non" 1 " PE Lock PE" 2 " Remote Key Lock" 3 " Auto Lock" 4 " Other Lock" 5 " Other Lock" 6 " Other Lock" 7 " Other Lock"  ;
VAL_ 589 PEPS_CurrentOperateKeyIndex 0 " no key operation" 1 " key1" 2 " key2" 3 " reserved" 4 " reserved" 5 " reserved" 6 " reserved" 7 " reserved"  ;
VAL_ 589 BCM_LFDoorLockStatus 0 " default" 1 " unlock；" 2 " locked" 7 " Invalid"  ;
VAL_ 589 BCM_TrunkDoorLockSts 0 " default" 1 " unlock；" 2 " locked" 7 " Invalid"  ;
VAL_ 589 PEPS_ESCL_SteeringLockStatus 0 " transforming" 1 " lock" 2 " unlock" 3 " Reserved"  ;
VAL_ 589 BCM_RFDoorLockStatus 0 " default" 1 " unlock；" 2 " locked" 7 " Invalid"  ;
VAL_ 589 BCM_LRDoorLockStatus 0 " default" 1 " unlock；" 2 " locked" 7 " Invalid"  ;
VAL_ 589 PEPS_DrvDoorRequestSwitchSt 0 " Inactive" 1 " Active"  ;
VAL_ 589 PEPS_StartStopButtonSt 0 " Inactive" 1 " Active"  ;
VAL_ 589 PEPS_TrunkRequestSwitchSt 0 " Inactive" 1 " Active"  ;
VAL_ 589 PEPS_VDrvDoorRequestSwitchSt 0 " Inactive" 1 " Active"  ;
VAL_ 589 BCM_RRDoorLockStatus 0 " default" 1 " unlock；" 2 " locked" 7 " Invalid"  ;
VAL_ 589 BCM_RLS_RQ_WiperSPD 0 " No wiping" 1 " Low Speed" 2 " High Speed" 3 " Not used"  ;
VAL_ 589 BCM_RLS_Fault 0 " No fault" 1 " fault" 2 " reserved" 3 " reserved"  ;
VAL_ 610 BCM_RR_TirePrsSt 0 " Normal" 1 " Over-pressure" 2 " Under-pressure" 3 " Reserved"  ;
VAL_ 610 BCM_RL_TirePrsSt 0 " Normal" 1 " Over-pressure" 2 " Under-pressure" 3 " Reserved"  ;
VAL_ 610 BCM_FR_TirePrsSt 0 " Normal" 1 " Over-pressure" 2 " Under-pressure" 3 " Reserved"  ;
VAL_ 610 BCM_FL_TirePrsSt 0 " Normal" 1 " Over-pressure" 2 " Under-pressure" 3 " Reserved"  ;
VAL_ 612 BCM_RR_TireTptSt 0 " Normal" 1 " Over temp"  ;
VAL_ 612 BCM_RL_TireTptSt 0 " Normal" 1 " Over temp"  ;
VAL_ 612 BCM_FR_TireTptSt 0 " Normal" 1 " Over temp"  ;
VAL_ 612 BCM_FL_TireTptSt 0 " Normal" 1 " Over temp"  ;
VAL_ 613 BCM_RR_TireLose 0 " Normal" 1 " RRLose"  ;
VAL_ 613 BCM_RL_TireLose 0 " Normal" 1 " RLLose"  ;
VAL_ 613 BCM_FR_TireLose 0 " Normal" 1 " FRLose"  ;
VAL_ 613 BCM_FL_TireLose 0 " Normal" 1 " FLLose"  ;
VAL_ 613 BCM_RR_TireLowVol 0 " Normal" 1 " LowVoltage"  ;
VAL_ 613 BCM_RL_TireLowVol 0 " Normal" 1 " LowVoltage"  ;
VAL_ 613 BCM_FR_TireLowVol 0 " Normal" 1 " LowVoltage"  ;
VAL_ 613 BCM_FL_TireLowVol 0 " Normal" 1 " LowVoltage"  ;
VAL_ 613 BCM_RR_TestSt 0 " System in normal status" 1 " System inTest status"  ;
VAL_ 613 BCM_RL_TestSt 0 " System in normal status" 1 " System inTest status"  ;
VAL_ 613 BCM_FR_TestSt 0 " System in normal status" 1 " System inTest status"  ;
VAL_ 613 BCM_FL_TestSt 0 " System in normal status" 1 " System inTest status"  ;
VAL_ 613 BCM_BatVol_ErrFlag 0 " Normal" 1 " Abnormal"  ;
VAL_ 613 BCM_TPMS_TestSt 0 " System in normal status" 1 " System in learn status" 2 " Reserved" 3 " Reserved"  ;
VAL_ 613 BCM_RR_Quikleakage 0 " Normal" 1 " Quik leakage"  ;
VAL_ 613 BCM_RL_Quikleakage 0 " Normal" 1 " Quik leakage"  ;
VAL_ 613 BCM_FR_Quikleakage 0 " Normal" 1 " Quik leakage"  ;
VAL_ 613 BCM_FL_Quikleakage 0 " Normal" 1 " Quik leakage"  ;
VAL_ 665 DSM_D_SlideDirection 0 " 无调节" 1 " 调节中" 2 " 调节完" 3 " 异常"  ;
VAL_ 665 DSM_D_FrontLiftDirection 0 " 无调节" 1 " 调节中" 2 " 调节完" 3 " 异常"  ;
VAL_ 665 DSM_D_ReclinerDirection 0 " 无调节" 1 " 调节中" 2 " 调节完" 3 " 异常"  ;
VAL_ 665 DSM_D_AllLiftDirection 0 " 无调节" 1 " 调节中" 2 " 调节完" 3 " 异常"  ;
VAL_ 665 DSM_DrvSeatHandyEntryExitSetStus 0 " invalid" 1 " Open" 2 " Close" 3 " Reserved"  ;
VAL_ 667 DSM_P_SlideDirection 0 " 无调节" 1 " 调节中" 2 " 调节完" 3 " 异常"  ;
VAL_ 667 DSM_P_FrontLiftDirection 0 " 无调节" 1 " 调节中" 2 " 调节完" 3 " 异常"  ;
VAL_ 667 DSM_P_ReclinerDirection 0 " 无调节" 1 " 调节中" 2 " 调节完" 3 " 异常"  ;
VAL_ 667 DSM_P_AllLiftDirection 0 " 无调节" 1 " 调节中" 2 " 调节完" 3 " 异常"  ;
VAL_ 659 FSCM_DrvSeatHeat_Sts 1 " OFF" 2 " Heating Level 1" 3 " Heating Level 2" 4 " Heating Level 3" 5 "reserved" 6 "reserved" 7 "reserved"  ;
VAL_ 659 FSCM_DrvSeatVentilation_Sts 1 " OFF" 2 " Venting Level 1" 3 " Venting Level 2" 4 " Venting Level 3" 5 "reserved" 6 "reserved" 7 "reserved"  ;
VAL_ 659 FSCM_PassSeatHeat_Sts 1 " OFF" 2 " Heating Level 1" 3 " Heating Level 2" 4 " Heating Level 3" 5 "reserved" 6 "reserved" 7 "reserved"  ;
VAL_ 659 FSCM_PassSeatVentilation_Sts 1 " OFF" 2 " Venting Level 1" 3 " Venting Level 2" 4 " Venting Level 3" 5 "reserved" 6 "reserved" 7 "reserved"  ;
VAL_ 856 CWC_Status_Charge 0 " 未充电" 1 " 充电中" 2 " 充满" 3 " 充电故障"  ;
VAL_ 856 CWC_Info_matter 0 " Inactive" 1 " Active"  ;
VAL_ 856 CWC_Info_phoneforgotten 0 " Inactive" 1 " Active"  ;
VAL_ 856 CWC_Over_Temp 0 " 正常；" 1 " 异常；"  ;
VAL_ 856 CWC_Over_Current 0 " 正常；" 1 " 异常；"  ;
VAL_ 856 CWC_Over_Voltage 0 " 正常；" 1 " 异常；"  ;
